VERSION ""

NS_ :

BS_:

BU_: PowertrainControlModule AtmosphericSensor SafetyRestraintSystem2 Aftertreatment_2_GasOutlet Aftertreatment_2_GasIntake DieselPartFilterControl Turbocharger SafetyRestraintSystem1 CabDisplay2 Aftertreatment_1_GasOutlet Aftertreatment_1_GasIntake OnBoardDataLogger OffBoardDiagnosticTool2 OffBoardDiagnosticTool1 FileServer ParkingBrakeController SeatController2 FanDriveController SteeringColumnUnit CommunicationUnitRadio CommunicationUnitSatellite CommunicationUnitCellular PropulsionBatteryCharger ChassisController2 ChassisController1 EngineValveControl AuxiliaryHeater2 AuxiliaryHeater1 ClutchUnit RampControl InformationSystem1 SuspensionSystemController2 OilSensor VehicleDynamicStability ExhaustEmissionController TransmissionDisplay2 TransmissionDisplay1 ClimateControl2 WaterPumpController RearAxleSteeringController LightingOperatorControl SeatController1 IgnitionController2 IgnitionController1 TirePressureController CabController2 CabController1 PneumaticSystemController SuspensionSystemController1 HydraulicPumpController EnduranceBrakingSystem RetarderExhaustEngine2 OnBoardDiagnosticUnit HeadwayController RetarderExhaustEngine1 CabDisplay1 ManagementComputer VirtualTerminal OffVehicleGateway PowerTakeOffFront HitchControl AuxiliaryValveControl BodyController TractorTrailerBridge1 StarterSystem ElectricalSystem VehicleSecurity VehicleNavigation AerodynamicControl ElectricalChargingSystem ClimateControl1 TripRecorder InstrumentCluster SuspensionDriveAxle2 SuspensionDriveAxle1 SuspensionSteerAxle SteeringController FuelSystem CruiseControl RetarderDriveline RetarderEngine BrakesDriveAxle2 BrakesDriveAxle1 BrakesSystemController BrakesSteerAxle AxleDrive2 AxleDrive1 AxleSteering PowerTakeOff ShiftConsoleSecondary ShiftConsolePrimary Transmission2 Transmission1 Engine2 Engine1

BO_ 2566718974 DLCD1: 8 Vector__XXX
 SG_ VhclAcclerationRateLimitLampData : 34|2@1+ (1,0) [0|3] "" Vector__XXX
 SG_ EngSpeedVeryHighLampData : 32|2@1+ (1,0) [0|3] "" Vector__XXX
 SG_ EngSpeedHighLampData : 30|2@1+ (1,0) [0|3] "" Vector__XXX
 SG_ EngCtrlMdule3ReadyForUseLampData : 28|2@1+ (1,0) [0|3] "" Vector__XXX
 SG_ EngCtrlMdule2ReadyForUseLampData : 26|2@1+ (1,0) [0|3] "" Vector__XXX
 SG_ EngCtrlMdule1ReadyForUseLampData : 24|2@1+ (1,0) [0|3] "" Vector__XXX
 SG_ EngWaitToStartLampData : 62|2@1+ (1,0) [0|3] "" Vector__XXX
 SG_ EngFuelFilterRestrictedLampData : 22|2@1+ (1,0) [0|3] "" Vector__XXX
 SG_ EngAirFilterRestrictionLampData : 20|2@1+ (1,0) [0|3] "" Vector__XXX
 SG_ EngIdleManagementActiveLampData : 18|2@1+ (1,0) [0|3] "" Vector__XXX
 SG_ EngCoolantLevelLowLampData : 16|2@1+ (1,0) [0|3] "" Vector__XXX
 SG_ EngCoolantTempHighLampData : 14|2@1+ (1,0) [0|3] "" Vector__XXX
 SG_ EngOilPressLowLampData : 12|2@1+ (1,0) [0|3] "" Vector__XXX
 SG_ CmprssnBrkEnblSwtchIndctrLmpData : 10|2@1+ (1,0) [0|3] "" Vector__XXX
 SG_ EngBrakeActiveLampData : 8|2@1+ (1,0) [0|3] "" Vector__XXX
 SG_ OBDMalfunctionIndicatorLampData : 6|2@1+ (1,0) [0|3] "" Vector__XXX
 SG_ EngRedStopLampData : 4|2@1+ (1,0) [0|3] "" Vector__XXX
 SG_ EngAmberWarningLampData : 2|2@1+ (1,0) [0|3] "" Vector__XXX
 SG_ EngProtectLampData : 0|2@1+ (1,0) [0|3] "" Vector__XXX

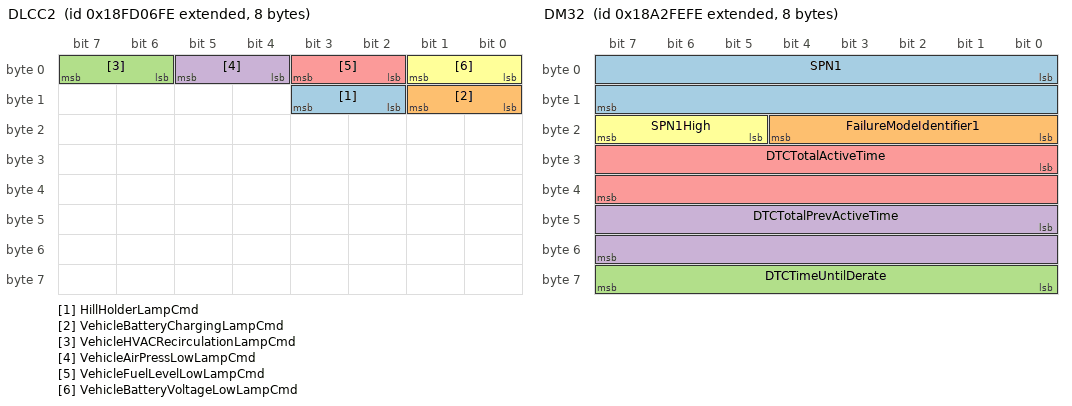
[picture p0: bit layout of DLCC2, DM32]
BO_ 2566719230 DLCC2: 8 Vector__XXX
 SG_ HillHolderLampCmd : 10|2@1+ (1,0) [0|3] "" Vector__XXX
 SG_ VehicleBatteryChargingLampCmd : 8|2@1+ (1,0) [0|3] "" Vector__XXX
 SG_ VehicleHVACRecirculationLampCmd : 6|2@1+ (1,0) [0|3] "" Vector__XXX
 SG_ VehicleAirPressLowLampCmd : 4|2@1+ (1,0) [0|3] "" Vector__XXX
 SG_ VehicleFuelLevelLowLampCmd : 2|2@1+ (1,0) [0|3] "" Vector__XXX
 SG_ VehicleBatteryVoltageLowLampCmd : 0|2@1+ (1,0) [0|3] "" Vector__XXX

BO_ 2560818942 DM32: 8 Vector__XXX
 SG_ SPN1 : 0|16@1+ (1,0) [0|65535] "" Vector__XXX
 SG_ FailureModeIdentifier1 : 16|5@1+ (1,0) [0|0] "" Vector__XXX
 SG_ DTCTimeUntilDerate : 56|8@1+ (0.25,0) [0|62.5] "hr" Vector__XXX
 SG_ DTCTotalPrevActiveTime : 40|16@1+ (0.2,0) [0|12851] "hr" Vector__XXX
 SG_ DTCTotalActiveTime : 24|16@1+ (0.2,0) [0|12851] "hr" Vector__XXX
 SG_ SPN1High : 21|3@1+ (1,0) [0|7] "" Vector__XXX

BO_ 2561212158 DISP1: 8 Vector__XXX
 SG_ TextDisplayIndex : 16|8@1+ (1,0) [0|200] "" Vector__XXX
 SG_ TextDisplayInstructions : 0|4@1+ (1,0) [0|15] "" Vector__XXX

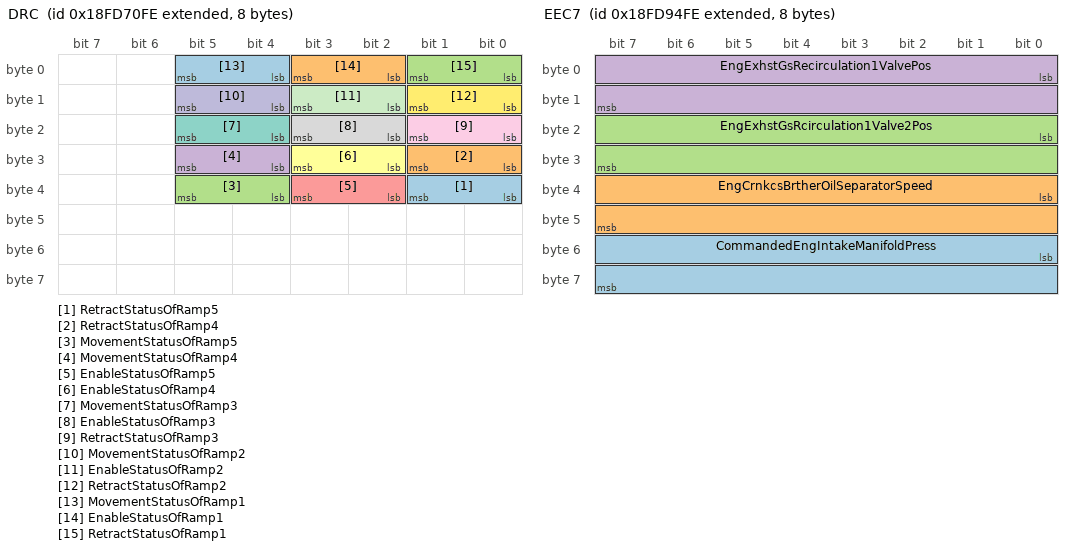
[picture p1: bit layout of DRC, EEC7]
BO_ 2566746366 DRC: 8 Vector__XXX
 SG_ RetractStatusOfRamp5 : 32|2@1+ (1,0) [0|3] "" Vector__XXX
 SG_ RetractStatusOfRamp4 : 24|2@1+ (1,0) [0|3] "" Vector__XXX
 SG_ MovementStatusOfRamp5 : 36|2@1+ (1,0) [0|3] "" Vector__XXX
 SG_ MovementStatusOfRamp4 : 28|2@1+ (1,0) [0|3] "" Vector__XXX
 SG_ EnableStatusOfRamp5 : 34|2@1+ (1,0) [0|3] "" Vector__XXX
 SG_ EnableStatusOfRamp4 : 26|2@1+ (1,0) [0|3] "" Vector__XXX
 SG_ MovementStatusOfRamp3 : 20|2@1+ (1,0) [0|3] "" Vector__XXX
 SG_ EnableStatusOfRamp3 : 18|2@1+ (1,0) [0|3] "" Vector__XXX
 SG_ RetractStatusOfRamp3 : 16|2@1+ (1,0) [0|3] "" Vector__XXX
 SG_ MovementStatusOfRamp2 : 12|2@1+ (1,0) [0|3] "" Vector__XXX
 SG_ EnableStatusOfRamp2 : 10|2@1+ (1,0) [0|3] "" Vector__XXX
 SG_ RetractStatusOfRamp2 : 8|2@1+ (1,0) [0|3] "" Vector__XXX
 SG_ MovementStatusOfRamp1 : 4|2@1+ (1,0) [0|3] "" Vector__XXX
 SG_ EnableStatusOfRamp1 : 2|2@1+ (1,0) [0|3] "" Vector__XXX
 SG_ RetractStatusOfRamp1 : 0|2@1+ (1,0) [0|3] "" Vector__XXX

BO_ 2566750206 EC2: 8 Vector__XXX
 SG_ EngConfigIdentification : 16|16@1+ (1,0) [0|64255] "" Vector__XXX
 SG_ NmbrOfCmbstionCyclesForAveraging : 8|8@1+ (1,0) [1|250] "" Vector__XXX
 SG_ MaxCrankAttemptsPerStartAttempt : 0|8@1+ (1,0) [0|250] "" Vector__XXX

BO_ 2566755582 EEC7: 8 Vector__XXX
 SG_ CommandedEngIntakeManifoldPress : 48|16@1+ (0.125,0) [0|8031.875] "kPa" Vector__XXX
 SG_ EngCrnkcsBrtherOilSeparatorSpeed : 32|16@1+ (1,0) [0|64255] "rpm" Vector__XXX
 SG_ EngExhstGsRcirculation1Valve2Pos : 16|16@1+ (0.0025,0) [0|160.6375] "%" Vector__XXX
 SG_ EngExhstGsRecirculation1ValvePos : 0|16@1+ (0.0025,0) [0|160.6375] "%" Vector__XXX

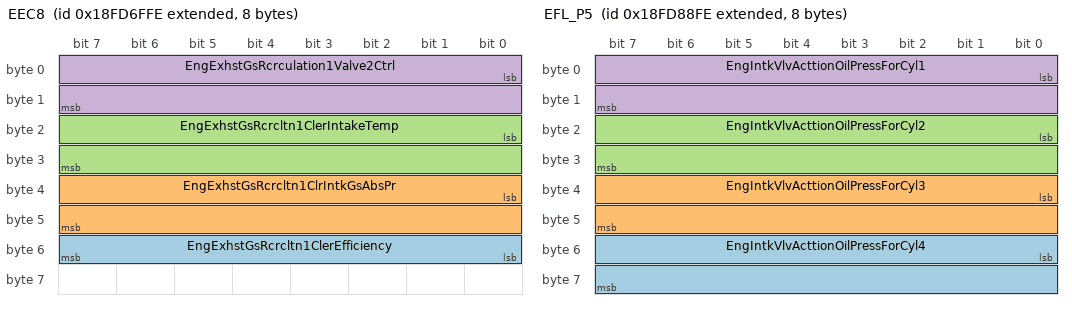
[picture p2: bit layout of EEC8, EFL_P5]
BO_ 2566746110 EEC8: 8 Vector__XXX
 SG_ EngExhstGsRcrcltn1ClerEfficiency : 48|8@1+ (0.4,0) [0|100] "%" Vector__XXX
 SG_ EngExhstGsRcrcltn1ClrIntkGsAbsPr : 32|16@1+ (0.5,0) [0|32127.5] "kPa" Vector__XXX
 SG_ EngExhstGsRcrcltn1ClerIntakeTemp : 16|16@1+ (0.03125,-273) [-273|1734.96875] "°C" Vector__XXX
 SG_ EngExhstGsRcrculation1Valve2Ctrl : 0|16@1+ (0.0025,0) [0|160.6375] "%" Vector__XXX

BO_ 2566752510 EFL_P5: 8 Vector__XXX
 SG_ EngIntkVlvActtionOilPressForCyl4 : 48|16@1+ (0.1,0) [0|6425.5] "kPa" Vector__XXX
 SG_ EngIntkVlvActtionOilPressForCyl3 : 32|16@1+ (0.1,0) [0|6425.5] "kPa" Vector__XXX
 SG_ EngIntkVlvActtionOilPressForCyl2 : 16|16@1+ (0.1,0) [0|6425.5] "kPa" Vector__XXX
 SG_ EngIntkVlvActtionOilPressForCyl1 : 0|16@1+ (0.1,0) [0|6425.5] "kPa" Vector__XXX

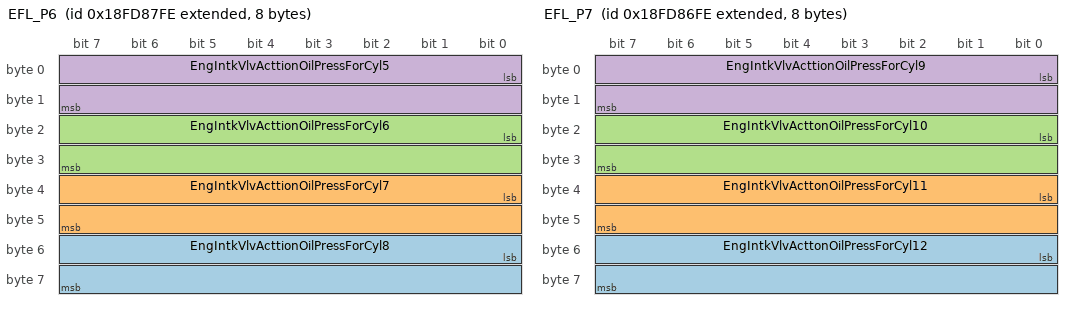
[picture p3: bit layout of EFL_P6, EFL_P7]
BO_ 2566752254 EFL_P6: 8 Vector__XXX
 SG_ EngIntkVlvActtionOilPressForCyl8 : 48|16@1+ (0.1,0) [0|6425.5] "kPa" Vector__XXX
 SG_ EngIntkVlvActtionOilPressForCyl7 : 32|16@1+ (0.1,0) [0|6425.5] "kPa" Vector__XXX
 SG_ EngIntkVlvActtionOilPressForCyl6 : 16|16@1+ (0.1,0) [0|6425.5] "kPa" Vector__XXX
 SG_ EngIntkVlvActtionOilPressForCyl5 : 0|16@1+ (0.1,0) [0|6425.5] "kPa" Vector__XXX

BO_ 2566751998 EFL_P7: 8 Vector__XXX
 SG_ EngIntkVlvActtonOilPressForCyl12 : 48|16@1+ (0.1,0) [0|6425.5] "kPa" Vector__XXX
 SG_ EngIntkVlvActtonOilPressForCyl11 : 32|16@1+ (0.1,0) [0|6425.5] "kPa" Vector__XXX
 SG_ EngIntkVlvActtonOilPressForCyl10 : 16|16@1+ (0.1,0) [0|6425.5] "kPa" Vector__XXX
 SG_ EngIntkVlvActtionOilPressForCyl9 : 0|16@1+ (0.1,0) [0|6425.5] "kPa" Vector__XXX

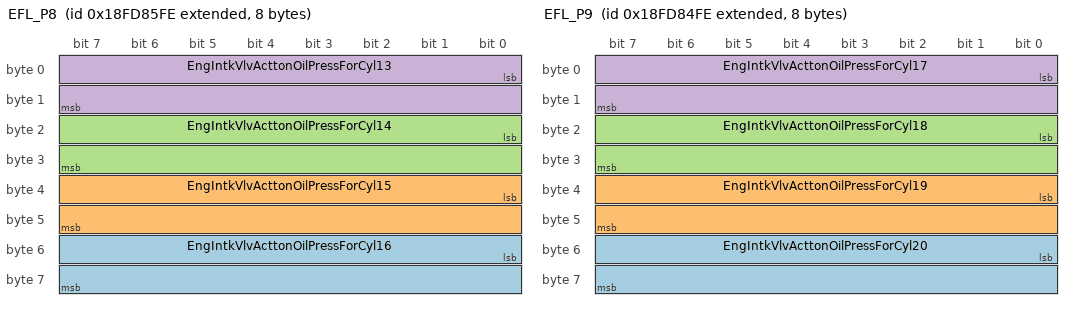
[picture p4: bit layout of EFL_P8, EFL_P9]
BO_ 2566751742 EFL_P8: 8 Vector__XXX
 SG_ EngIntkVlvActtonOilPressForCyl16 : 48|16@1+ (0.1,0) [0|6425.5] "kPa" Vector__XXX
 SG_ EngIntkVlvActtonOilPressForCyl15 : 32|16@1+ (0.1,0) [0|6425.5] "kPa" Vector__XXX
 SG_ EngIntkVlvActtonOilPressForCyl14 : 16|16@1+ (0.1,0) [0|6425.5] "kPa" Vector__XXX
 SG_ EngIntkVlvActtonOilPressForCyl13 : 0|16@1+ (0.1,0) [0|6425.5] "kPa" Vector__XXX

BO_ 2566751486 EFL_P9: 8 Vector__XXX
 SG_ EngIntkVlvActtonOilPressForCyl20 : 48|16@1+ (0.1,0) [0|6425.5] "kPa" Vector__XXX
 SG_ EngIntkVlvActtonOilPressForCyl19 : 32|16@1+ (0.1,0) [0|6425.5] "kPa" Vector__XXX
 SG_ EngIntkVlvActtonOilPressForCyl18 : 16|16@1+ (0.1,0) [0|6425.5] "kPa" Vector__XXX
 SG_ EngIntkVlvActtonOilPressForCyl17 : 0|16@1+ (0.1,0) [0|6425.5] "kPa" Vector__XXX

BO_ 2499641854 EGRBV: 8 Vector__XXX
 SG_ EGR1CoolerBypassActuatorPostion : 0|8@1+ (0.4,0) [0|100] "%" Vector__XXX

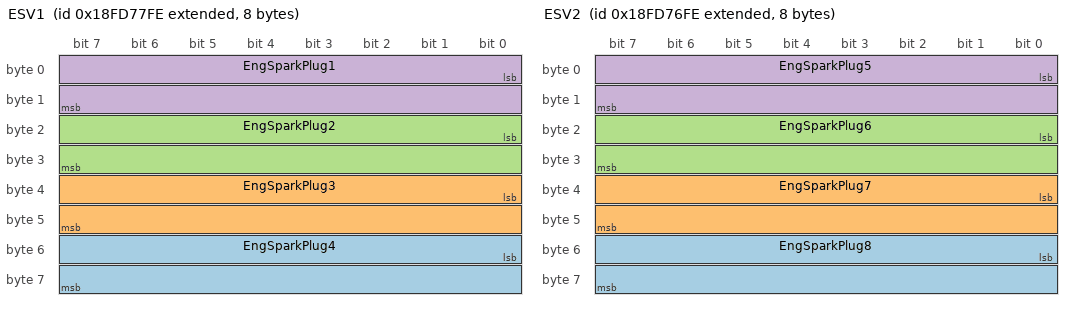
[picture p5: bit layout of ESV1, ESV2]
BO_ 2566748158 ESV1: 8 Vector__XXX
 SG_ EngSparkPlug4 : 48|16@1+ (1,0) [0|64255] "V" Vector__XXX
 SG_ EngSparkPlug3 : 32|16@1+ (1,0) [0|64255] "V" Vector__XXX
 SG_ EngSparkPlug2 : 16|16@1+ (1,0) [0|64255] "V" Vector__XXX
 SG_ EngSparkPlug1 : 0|16@1+ (1,0) [0|64255] "V" Vector__XXX

BO_ 2566747902 ESV2: 8 Vector__XXX
 SG_ EngSparkPlug8 : 48|16@1+ (1,0) [0|64255] "V" Vector__XXX
 SG_ EngSparkPlug7 : 32|16@1+ (1,0) [0|64255] "V" Vector__XXX
 SG_ EngSparkPlug6 : 16|16@1+ (1,0) [0|64255] "V" Vector__XXX
 SG_ EngSparkPlug5 : 0|16@1+ (1,0) [0|64255] "V" Vector__XXX

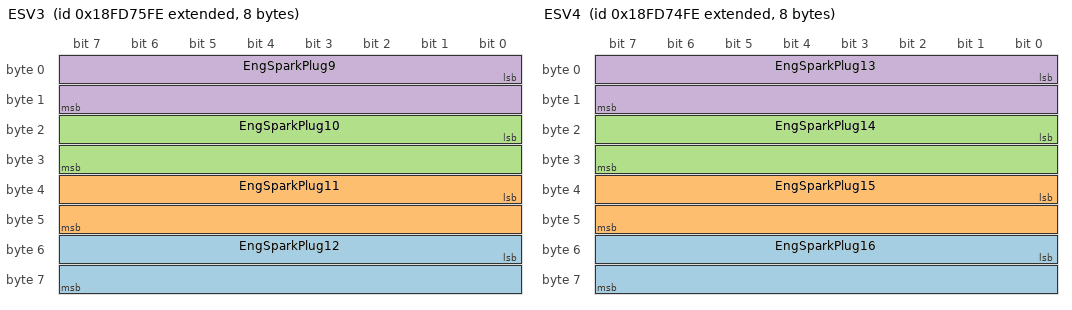
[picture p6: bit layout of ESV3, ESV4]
BO_ 2566747646 ESV3: 8 Vector__XXX
 SG_ EngSparkPlug12 : 48|16@1+ (1,0) [0|64255] "V" Vector__XXX
 SG_ EngSparkPlug11 : 32|16@1+ (1,0) [0|64255] "V" Vector__XXX
 SG_ EngSparkPlug10 : 16|16@1+ (1,0) [0|64255] "V" Vector__XXX
 SG_ EngSparkPlug9 : 0|16@1+ (1,0) [0|64255] "V" Vector__XXX

BO_ 2566747390 ESV4: 8 Vector__XXX
 SG_ EngSparkPlug16 : 48|16@1+ (1,0) [0|64255] "V" Vector__XXX
 SG_ EngSparkPlug15 : 32|16@1+ (1,0) [0|64255] "V" Vector__XXX
 SG_ EngSparkPlug14 : 16|16@1+ (1,0) [0|64255] "V" Vector__XXX
 SG_ EngSparkPlug13 : 0|16@1+ (1,0) [0|64255] "V" Vector__XXX

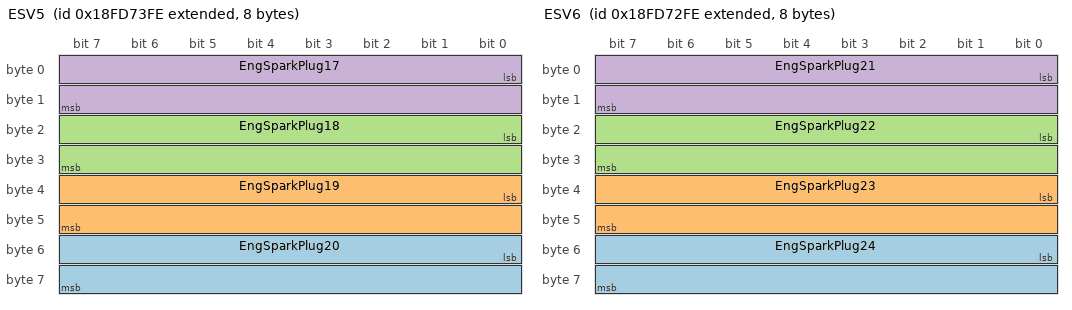
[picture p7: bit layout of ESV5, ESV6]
BO_ 2566747134 ESV5: 8 Vector__XXX
 SG_ EngSparkPlug20 : 48|16@1+ (1,0) [0|64255] "V" Vector__XXX
 SG_ EngSparkPlug19 : 32|16@1+ (1,0) [0|64255] "V" Vector__XXX
 SG_ EngSparkPlug18 : 16|16@1+ (1,0) [0|64255] "V" Vector__XXX
 SG_ EngSparkPlug17 : 0|16@1+ (1,0) [0|64255] "V" Vector__XXX

BO_ 2566746878 ESV6: 8 Vector__XXX
 SG_ EngSparkPlug24 : 48|16@1+ (1,0) [0|64255] "V" Vector__XXX
 SG_ EngSparkPlug23 : 32|16@1+ (1,0) [0|64255] "V" Vector__XXX
 SG_ EngSparkPlug22 : 16|16@1+ (1,0) [0|64255] "V" Vector__XXX
 SG_ EngSparkPlug21 : 0|16@1+ (1,0) [0|64255] "V" Vector__XXX

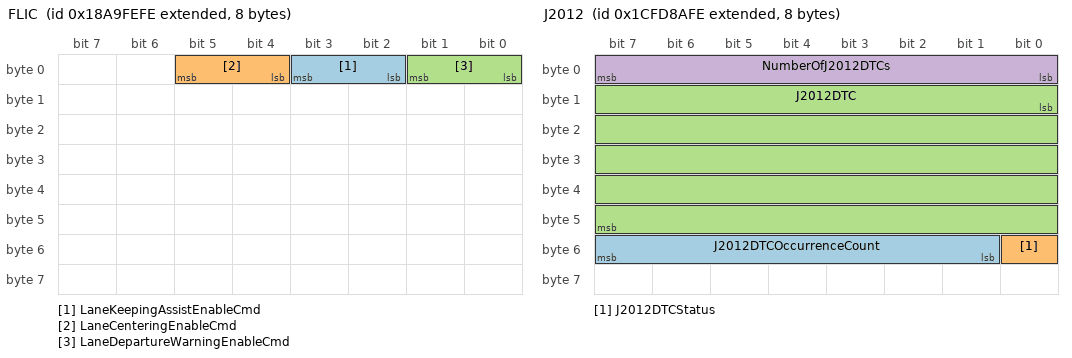
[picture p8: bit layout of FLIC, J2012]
BO_ 2561277694 FLIC: 8 Vector__XXX
 SG_ LaneKeepingAssistEnableCmd : 2|2@1+ (1,0) [0|3] "" Vector__XXX
 SG_ LaneCenteringEnableCmd : 4|2@1+ (1,0) [0|3] "" Vector__XXX
 SG_ LaneDepartureWarningEnableCmd : 0|2@1+ (1,0) [0|3] "" Vector__XXX

BO_ 2633861886 J2012: 8 Vector__XXX
 SG_ J2012DTCOccurrenceCount : 49|7@1+ (1,0) [0|126] "" Vector__XXX
 SG_ J2012DTCStatus : 48|1@1+ (1,0) [0|1] "" Vector__XXX
 SG_ J2012DTC : 8|40@1+ (1,0) [0|255] "" Vector__XXX
 SG_ NumberOfJ2012DTCs : 0|8@1+ (1,0) [0|250] "" Vector__XXX

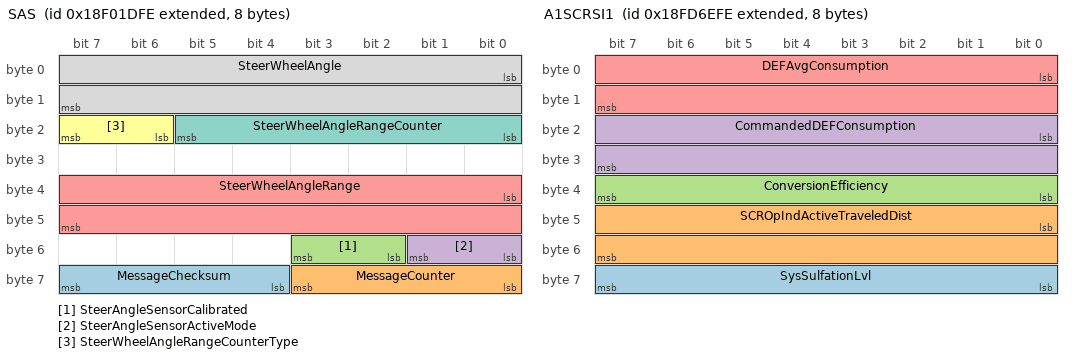
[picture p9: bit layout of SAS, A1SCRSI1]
BO_ 2565873150 SAS: 8 Vector__XXX
 SG_ MessageChecksum : 60|4@1+ (1,0) [0|15] "" Vector__XXX
 SG_ MessageCounter : 56|4@1+ (1,0) [0|15] "" Vector__XXX
 SG_ SteerAngleSensorCalibrated : 50|2@1+ (1,0) [0|3] "" Vector__XXX
 SG_ SteerAngleSensorActiveMode : 48|2@1+ (1,0) [0|3] "" Vector__XXX
 SG_ SteerWheelAngleRange : 32|16@1+ (0.0009765625,-31.374) [0|31.374] "rad" Vector__XXX
 SG_ SteerWheelAngleRangeCounterType : 22|2@1+ (1,0) [0|3] "" Vector__XXX
 SG_ SteerWheelAngleRangeCounter : 16|6@1+ (1,-32) [-32|29] "ranges" Vector__XXX
 SG_ SteerWheelAngle : 0|16@1+ (0.0009765625,-31.374) [-31.374|31.374] "rad" Vector__XXX

BO_ 2566745854 A1SCRSI1: 8 Vector__XXX
 SG_ SysSulfationLvl : 56|8@1+ (1,0) [0|250] "%" Vector__XXX
 SG_ SCROpIndActiveTraveledDist : 40|16@1+ (1,0) [0|64255] "km" Vector__XXX
 SG_ ConversionEfficiency : 32|8@1+ (0.4,0) [0|100] "%" Vector__XXX
 SG_ CommandedDEFConsumption : 16|16@1+ (0.05,0) [0|3212.75] "L/h" Vector__XXX
 SG_ DEFAvgConsumption : 0|16@1+ (0.05,0) [0|3212.75] "L/h" Vector__XXX

BO_ 2566751230 TCI: 8 Vector__XXX
 SG_ TransferCaseStatus : 0|3@1+ (1,0) [0|7] "" Vector__XXX

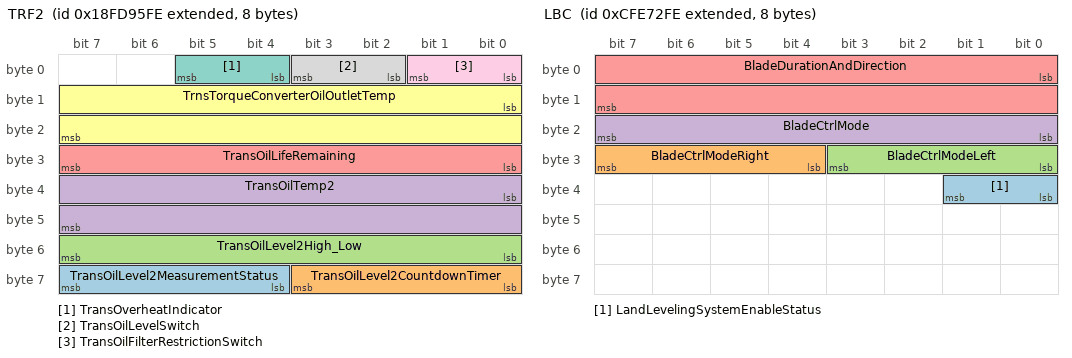
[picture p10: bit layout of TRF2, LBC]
BO_ 2566755838 TRF2: 8 Vector__XXX
 SG_ TransOilLevel2MeasurementStatus : 60|4@1+ (1,0) [0|15] "" Vector__XXX
 SG_ TransOilLevel2CountdownTimer : 56|4@1+ (1,0) [0|13] "" Vector__XXX
 SG_ TransOilLevel2High_Low : 48|8@1+ (0.5,-62.5) [-62.5|62.5] "L" Vector__XXX
 SG_ TransOilTemp2 : 32|16@1+ (0.03125,-273) [-273|1734.96875] "°C" Vector__XXX
 SG_ TransOilLifeRemaining : 24|8@1+ (0.4,0) [0|100] "%" Vector__XXX
 SG_ TrnsTorqueConverterOilOutletTemp : 8|16@1+ (0.03125,-273) [-273|1734.96875] "°C" Vector__XXX
 SG_ TransOverheatIndicator : 4|2@1+ (1,0) [0|3] "" Vector__XXX
 SG_ TransOilLevelSwitch : 2|2@1+ (1,0) [0|3] "" Vector__XXX
 SG_ TransOilFilterRestrictionSwitch : 0|2@1+ (1,0) [0|3] "" Vector__XXX

BO_ 2566752766 VDS2: 8 Vector__XXX
 SG_ VehicleRoll : 0|16@1+ (0.0078125,-200) [-90|90] "deg" Vector__XXX

BO_ 2633938942 LF: 10 Vector__XXX
 SG_ TotalEngCruiseTime : 48|32@1+ (0.05,0) [0|210554060.75] "h" Vector__XXX
 SG_ TotalDriveAverageLoadFactor : 40|8@1+ (0.4,0) [0|100] "%" Vector__XXX
 SG_ TripDriveAverageLoadFactor : 32|8@1+ (0.4,0) [0|100] "%" Vector__XXX
 SG_ TripAverageEngSpeed : 16|16@1+ (0.125,0) [0|8031.875] "rpm" Vector__XXX
 SG_ TripMaxEngSpeed : 0|16@1+ (0.125,0) [0|8031.875] "rpm" Vector__XXX

BO_ 2566799614 LD: 8 Vector__XXX
 SG_ ImplementRearWorkLight : 62|2@1+ (1,0) [0|3] "" Vector__XXX
 SG_ ImplLeftFacingWorkLight : 60|2@1+ (1,0) [0|3] "" Vector__XXX
 SG_ ImplRightForwardWorkLight : 58|2@1+ (1,0) [0|3] "" Vector__XXX
 SG_ ImplLeftForwardWorkLight : 54|2@1+ (1,0) [0|3] "" Vector__XXX
 SG_ ImplRightFacingWorkLight : 52|2@1+ (1,0) [0|3] "" Vector__XXX
 SG_ ImplementOEMOption1Light : 50|2@1+ (1,0) [0|3] "" Vector__XXX
 SG_ ImplementOEMOption2Light : 48|2@1+ (1,0) [0|3] "" Vector__XXX
 SG_ TrctorFrontHighMdWkLights : 46|2@1+ (1,0) [0|3] "" Vector__XXX
 SG_ TractorFrontLowMdWkLights : 44|2@1+ (1,0) [0|3] "" Vector__XXX
 SG_ TractorSideHighMdWkLights : 42|2@1+ (1,0) [0|3] "" Vector__XXX
 SG_ TractorSideLowMdWkLights : 40|2@1+ (1,0) [0|3] "" Vector__XXX
 SG_ TractorRearHighMdWkLights : 38|2@1+ (1,0) [0|3] "" Vector__XXX
 SG_ TractorRearLowMdWkLights : 36|2@1+ (1,0) [0|3] "" Vector__XXX
 SG_ TrctorUndersideMdWkLights : 34|2@1+ (1,0) [0|3] "" Vector__XXX
 SG_ RearFogLights : 32|2@1+ (1,0) [0|3] "" Vector__XXX
 SG_ TractorMarkerLight : 30|2@1+ (1,0) [0|3] "" Vector__XXX
 SG_ ImplementMarkerLight : 28|2@1+ (1,0) [0|3] "" Vector__XXX
 SG_ TractorClearanceLight : 26|2@1+ (1,0) [0|3] "" Vector__XXX
 SG_ ImplementClearanceLight : 24|2@1+ (1,0) [0|3] "" Vector__XXX
 SG_ LeftStopLight : 22|2@1+ (1,0) [0|3] "" Vector__XXX
 SG_ RightStopLight : 20|2@1+ (1,0) [0|3] "" Vector__XXX
 SG_ CenterStopLight : 18|2@1+ (1,0) [0|3] "" Vector__XXX
 SG_ BackUpLightAndAlarmHorn : 16|2@1+ (1,0) [0|3] "" Vector__XXX
 SG_ LeftTurnSignalLights : 14|2@1+ (1,0) [0|3] "" Vector__XXX
 SG_ RightTurnSignalLights : 12|2@1+ (1,0) [0|3] "" Vector__XXX
 SG_ RotatingBeaconLight : 10|2@1+ (1,0) [0|3] "" Vector__XXX
 SG_ TractorFrontFogLights : 8|2@1+ (1,0) [0|3] "" Vector__XXX
 SG_ HighBeamHeadLight : 6|2@1+ (1,0) [0|3] "" Vector__XXX
 SG_ LowBeamHeadLight : 4|2@1+ (1,0) [0|3] "" Vector__XXX
 SG_ AltBeamHeadLight : 2|2@1+ (1,0) [0|3] "" Vector__XXX
 SG_ RunningLight : 0|2@1+ (1,0) [0|3] "" Vector__XXX

BO_ 2365473278 LCMD: 8 Vector__XXX
 SG_ ImplementRearWorkLightCmd : 62|2@1+ (1,0) [0|3] "" Vector__XXX
 SG_ ImplLeftFacingWorkLightCmd : 60|2@1+ (1,0) [0|3] "" Vector__XXX
 SG_ ImplRightFwdWorkLightCmd : 58|2@1+ (1,0) [0|3] "" Vector__XXX
 SG_ LightingDataRqCmd : 56|2@1+ (1,0) [0|3] "" Vector__XXX
 SG_ ImplLeftForwardWorkLightCmd : 54|2@1+ (1,0) [0|3] "" Vector__XXX
 SG_ ImplRightFacingWorkLightCmd : 52|2@1+ (1,0) [0|3] "" Vector__XXX
 SG_ ImplOEMOption1LightCmd : 50|2@1+ (1,0) [0|3] "" Vector__XXX
 SG_ ImplOEMOption2LightCmd : 48|2@1+ (1,0) [0|3] "" Vector__XXX
 SG_ TrctrFrntHghMdWkLightsCmd : 46|2@1+ (1,0) [0|3] "" Vector__XXX
 SG_ TrctrFrntLowMdWkLightsCmd : 44|2@1+ (1,0) [0|3] "" Vector__XXX
 SG_ TrctrSdeHighMdWkLightsCmd : 42|2@1+ (1,0) [0|3] "" Vector__XXX
 SG_ TrctrSideLowMdWkLightsCmd : 40|2@1+ (1,0) [0|3] "" Vector__XXX
 SG_ TrctrRarHighMdWkLightsCmd : 38|2@1+ (1,0) [0|3] "" Vector__XXX
 SG_ TrctrRearLowMdWkLightsCmd : 36|2@1+ (1,0) [0|3] "" Vector__XXX
 SG_ TrctrUndrsdeMdWkLightsCmd : 34|2@1+ (1,0) [0|3] "" Vector__XXX
 SG_ RearFogLightsCmd : 32|2@1+ (1,0) [0|3] "" Vector__XXX
 SG_ TractorMarkerLightCmd : 30|2@1+ (1,0) [0|3] "" Vector__XXX
 SG_ ImplementMarkerLightCmd : 28|2@1+ (1,0) [0|3] "" Vector__XXX
 SG_ TractorClearanceLightCmd : 26|2@1+ (1,0) [0|3] "" Vector__XXX
 SG_ ImplementClearanceLightCmd : 24|2@1+ (1,0) [0|3] "" Vector__XXX
 SG_ LeftStopLightCmd : 22|2@1+ (1,0) [0|3] "" Vector__XXX
 SG_ RightStopLightCmd : 20|2@1+ (1,0) [0|3] "" Vector__XXX
 SG_ CenterStopLightCmd : 18|2@1+ (1,0) [0|3] "" Vector__XXX
 SG_ BackUpLightAndAlarmHornCmd : 16|2@1+ (1,0) [0|3] "" Vector__XXX
 SG_ LeftTurnSignalLightsCmd : 14|2@1+ (1,0) [0|3] "" Vector__XXX
 SG_ RightTurnSignalLightsCmd : 12|2@1+ (1,0) [0|3] "" Vector__XXX
 SG_ RotatingBeaconLightCmd : 10|2@1+ (1,0) [0|3] "" Vector__XXX
 SG_ TractorFrontFogLightsCmd : 8|2@1+ (1,0) [0|3] "" Vector__XXX
 SG_ HighBeamHeadLightCmd : 6|2@1+ (1,0) [0|3] "" Vector__XXX
 SG_ LowBeamHeadLightCmd : 4|2@1+ (1,0) [0|3] "" Vector__XXX
 SG_ AltBeamHeadLightCmd : 2|2@1+ (1,0) [0|3] "" Vector__XXX
 SG_ RunningLightCmd : 0|2@1+ (1,0) [0|3] "" Vector__XXX

BO_ 2365485822 LBC: 8 Vector__XXX
 SG_ LandLevelingSystemEnableStatus : 32|2@1+ (1,0) [0|3] "" Vector__XXX
 SG_ BladeCtrlModeRight : 28|4@1+ (1,0) [0|15] "" Vector__XXX
 SG_ BladeCtrlModeLeft : 24|4@1+ (1,0) [0|15] "" Vector__XXX
 SG_ BladeCtrlMode : 16|8@1+ (1,0) [0|255] "" Vector__XXX
 SG_ BladeDurationAndDirection : 0|16@1+ (0.1,-3276.8) [-3276.8|3148.7] "sec" Vector__XXX

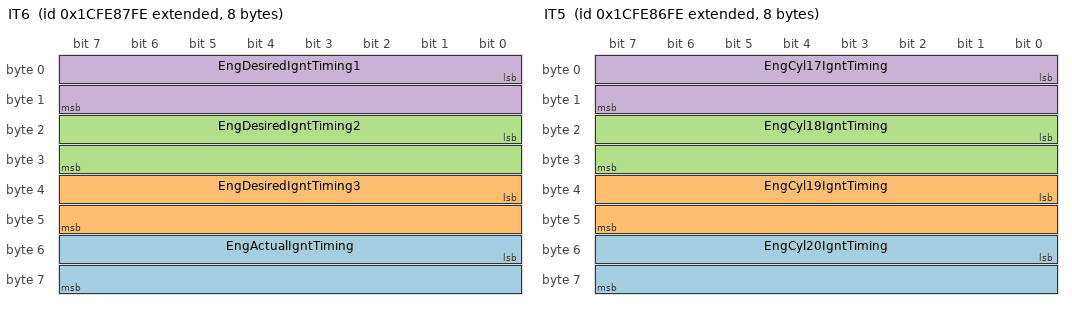
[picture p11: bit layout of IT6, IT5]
BO_ 2633926654 IT6: 8 Vector__XXX
 SG_ EngActualIgntTiming : 48|16@1+ (0.0078125,-200) [-200|301.99] "deg" Vector__XXX
 SG_ EngDesiredIgntTiming3 : 32|16@1+ (0.0078125,-200) [-200|301.99] "deg" Vector__XXX
 SG_ EngDesiredIgntTiming2 : 16|16@1+ (0.0078125,-200) [-200|301.99] "deg" Vector__XXX
 SG_ EngDesiredIgntTiming1 : 0|16@1+ (0.0078125,-200) [-200|301.99] "deg" Vector__XXX

BO_ 2633926398 IT5: 8 Vector__XXX
 SG_ EngCyl20IgntTiming : 48|16@1+ (0.0078125,-200) [-200|301.99] "deg" Vector__XXX
 SG_ EngCyl19IgntTiming : 32|16@1+ (0.0078125,-200) [-200|301.99] "deg" Vector__XXX
 SG_ EngCyl18IgntTiming : 16|16@1+ (0.0078125,-200) [-200|301.99] "deg" Vector__XXX
 SG_ EngCyl17IgntTiming : 0|16@1+ (0.0078125,-200) [-200|301.99] "deg" Vector__XXX

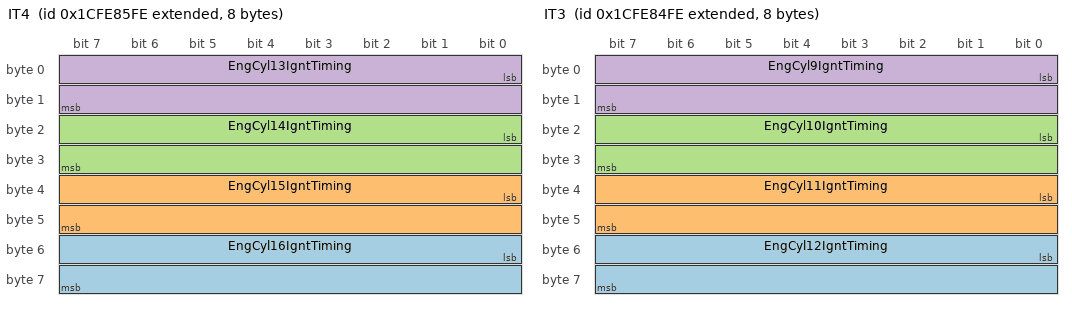
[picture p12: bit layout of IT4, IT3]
BO_ 2633926142 IT4: 8 Vector__XXX
 SG_ EngCyl16IgntTiming : 48|16@1+ (0.0078125,-200) [-200|301.99] "deg" Vector__XXX
 SG_ EngCyl15IgntTiming : 32|16@1+ (0.0078125,-200) [-200|301.99] "deg" Vector__XXX
 SG_ EngCyl14IgntTiming : 16|16@1+ (0.0078125,-200) [-200|301.99] "deg" Vector__XXX
 SG_ EngCyl13IgntTiming : 0|16@1+ (0.0078125,-200) [-200|301.99] "deg" Vector__XXX

BO_ 2633925886 IT3: 8 Vector__XXX
 SG_ EngCyl12IgntTiming : 48|16@1+ (0.0078125,-200) [-200|301.99] "deg" Vector__XXX
 SG_ EngCyl11IgntTiming : 32|16@1+ (0.0078125,-200) [-200|301.99] "deg" Vector__XXX
 SG_ EngCyl10IgntTiming : 16|16@1+ (0.0078125,-200) [-200|301.99] "deg" Vector__XXX
 SG_ EngCyl9IgntTiming : 0|16@1+ (0.0078125,-200) [-200|301.99] "deg" Vector__XXX

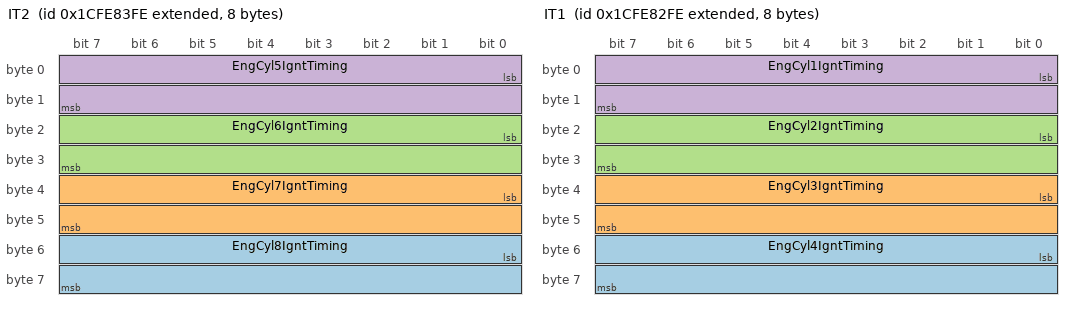
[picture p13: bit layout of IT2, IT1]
BO_ 2633925630 IT2: 8 Vector__XXX
 SG_ EngCyl8IgntTiming : 48|16@1+ (0.0078125,-200) [-200|301.99] "deg" Vector__XXX
 SG_ EngCyl7IgntTiming : 32|16@1+ (0.0078125,-200) [-200|301.99] "deg" Vector__XXX
 SG_ EngCyl6IgntTiming : 16|16@1+ (0.0078125,-200) [-200|301.99] "deg" Vector__XXX
 SG_ EngCyl5IgntTiming : 0|16@1+ (0.0078125,-200) [-200|301.99] "deg" Vector__XXX

BO_ 2633925374 IT1: 8 Vector__XXX
 SG_ EngCyl4IgntTiming : 48|16@1+ (0.0078125,-200) [-200|301.99] "deg" Vector__XXX
 SG_ EngCyl3IgntTiming : 32|16@1+ (0.0078125,-200) [-200|301.99] "deg" Vector__XXX
 SG_ EngCyl2IgntTiming : 16|16@1+ (0.0078125,-200) [-200|301.99] "deg" Vector__XXX
 SG_ EngCyl1IgntTiming : 0|16@1+ (0.0078125,-200) [-200|301.99] "deg" Vector__XXX

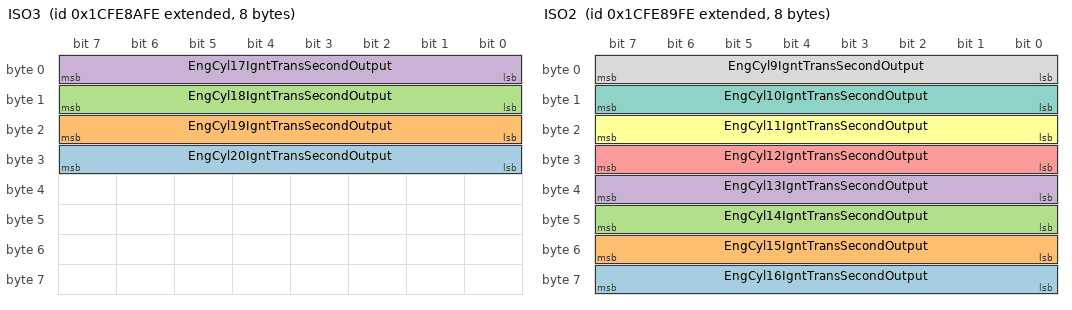
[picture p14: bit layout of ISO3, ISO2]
BO_ 2633927422 ISO3: 8 Vector__XXX
 SG_ EngCyl20IgntTransSecondOutput : 24|8@1+ (1,-125) [-125|125] "%" Vector__XXX
 SG_ EngCyl19IgntTransSecondOutput : 16|8@1+ (1,-125) [-125|125] "%" Vector__XXX
 SG_ EngCyl18IgntTransSecondOutput : 8|8@1+ (1,-125) [-125|125] "%" Vector__XXX
 SG_ EngCyl17IgntTransSecondOutput : 0|8@1+ (1,-125) [-125|125] "%" Vector__XXX

BO_ 2633927166 ISO2: 8 Vector__XXX
 SG_ EngCyl16IgntTransSecondOutput : 56|8@1+ (1,-125) [-125|125] "%" Vector__XXX
 SG_ EngCyl15IgntTransSecondOutput : 48|8@1+ (1,-125) [-125|125] "%" Vector__XXX
 SG_ EngCyl14IgntTransSecondOutput : 40|8@1+ (1,-125) [-125|125] "%" Vector__XXX
 SG_ EngCyl13IgntTransSecondOutput : 32|8@1+ (1,-125) [-125|125] "%" Vector__XXX
 SG_ EngCyl12IgntTransSecondOutput : 24|8@1+ (1,-125) [-125|125] "%" Vector__XXX
 SG_ EngCyl11IgntTransSecondOutput : 16|8@1+ (1,-125) [-125|125] "%" Vector__XXX
 SG_ EngCyl10IgntTransSecondOutput : 8|8@1+ (1,-125) [-125|125] "%" Vector__XXX
 SG_ EngCyl9IgntTransSecondOutput : 0|8@1+ (1,-125) [-125|125] "%" Vector__XXX

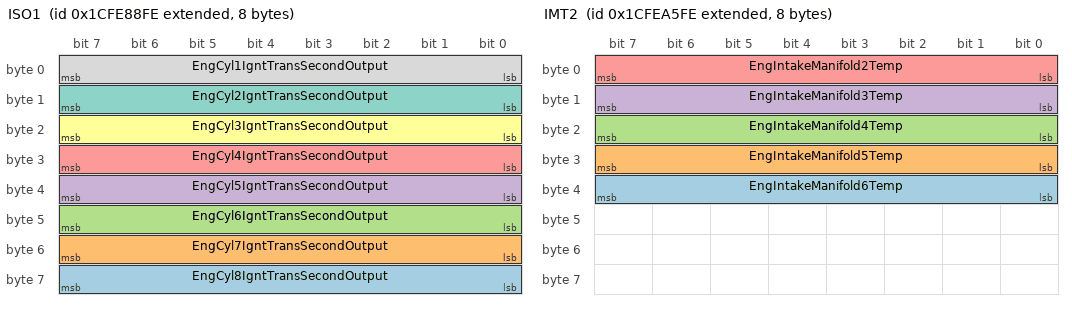
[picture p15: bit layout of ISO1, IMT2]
BO_ 2633926910 ISO1: 8 Vector__XXX
 SG_ EngCyl8IgntTransSecondOutput : 56|8@1+ (1,-125) [-125|125] "%" Vector__XXX
 SG_ EngCyl7IgntTransSecondOutput : 48|8@1+ (1,-125) [-125|125] "%" Vector__XXX
 SG_ EngCyl6IgntTransSecondOutput : 40|8@1+ (1,-125) [-125|125] "%" Vector__XXX
 SG_ EngCyl5IgntTransSecondOutput : 32|8@1+ (1,-125) [-125|125] "%" Vector__XXX
 SG_ EngCyl4IgntTransSecondOutput : 24|8@1+ (1,-125) [-125|125] "%" Vector__XXX
 SG_ EngCyl3IgntTransSecondOutput : 16|8@1+ (1,-125) [-125|125] "%" Vector__XXX
 SG_ EngCyl2IgntTransSecondOutput : 8|8@1+ (1,-125) [-125|125] "%" Vector__XXX
 SG_ EngCyl1IgntTransSecondOutput : 0|8@1+ (1,-125) [-125|125] "%" Vector__XXX

BO_ 2566768894 ISCS: 8 Vector__XXX
 SG_ EngOprtrPrmryIntrmdtSpdSlctState : 0|4@1+ (1,0) [0|15] "" Vector__XXX

BO_ 2566769406 ISC: 8 Vector__XXX
 SG_ EngOprtrPrmryIntrmdteSpeedSelect : 0|4@1+ (1,0) [0|15] "" Vector__XXX

BO_ 2566839550 IO: 8 Vector__XXX
 SG_ EngTotalIdleHours : 32|32@1+ (0.05,0) [0|210554060.75] "h" Vector__XXX
 SG_ EngTotalIdleFuelUsed : 0|32@1+ (0.5,0) [0|2105540607.5] "L" Vector__XXX

BO_ 2633934334 IMT2: 8 Vector__XXX
 SG_ EngIntakeManifold6Temp : 32|8@1+ (1,-40) [-40|210] "°C" Vector__XXX
 SG_ EngIntakeManifold5Temp : 24|8@1+ (1,-40) [-40|210] "°C" Vector__XXX
 SG_ EngIntakeManifold4Temp : 16|8@1+ (1,-40) [-40|210] "°C" Vector__XXX
 SG_ EngIntakeManifold3Temp : 8|8@1+ (1,-40) [-40|210] "°C" Vector__XXX
 SG_ EngIntakeManifold2Temp : 0|8@1+ (1,-40) [-40|210] "°C" Vector__XXX

BO_ 2566825726 IMT1: 8 Vector__XXX
 SG_ EngTurbo4BoostPress : 48|16@1+ (0.125,0) [0|8031.875] "kPa" Vector__XXX
 SG_ EngTurbo3BoostPress : 32|16@1+ (0.125,0) [0|8031.875] "kPa" Vector__XXX
 SG_ EngTurbo2BoostPress : 16|16@1+ (0.125,0) [0|8031.875] "kPa" Vector__XXX
 SG_ EngTurbo1BoostPress : 0|16@1+ (0.125,0) [0|8031.875] "kPa" Vector__XXX

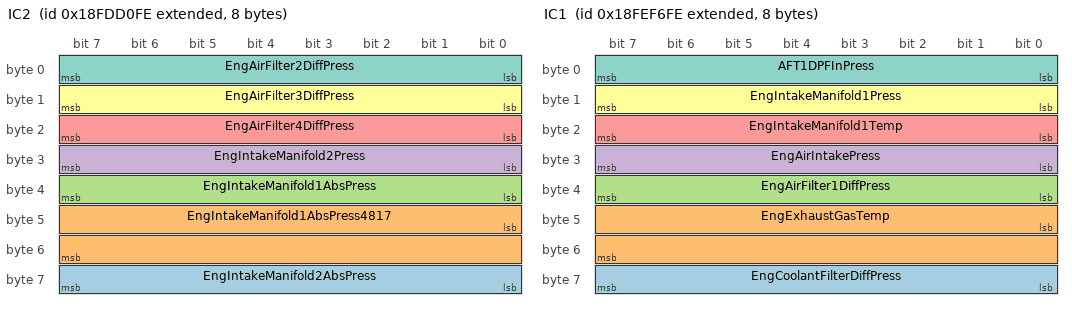
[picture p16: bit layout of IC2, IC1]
BO_ 2566770942 IC2: 8 Vector__XXX
 SG_ EngIntakeManifold2AbsPress : 56|8@1+ (2,0) [0|500] "kPa" Vector__XXX
 SG_ EngIntakeManifold1AbsPress4817 : 40|16@1+ (0.1,0) [0|6425.5] "kPa" Vector__XXX
 SG_ EngIntakeManifold1AbsPress : 32|8@1+ (2,0) [0|500] "kPa" Vector__XXX
 SG_ EngIntakeManifold2Press : 24|8@1+ (2,0) [0|500] "kPa" Vector__XXX
 SG_ EngAirFilter4DiffPress : 16|8@1+ (0.05,0) [0|12.5] "kPa" Vector__XXX
 SG_ EngAirFilter3DiffPress : 8|8@1+ (0.05,0) [0|12.5] "kPa" Vector__XXX
 SG_ EngAirFilter2DiffPress : 0|8@1+ (0.05,0) [0|12.5] "kPa" Vector__XXX

BO_ 2566846206 IC1: 8 Vector__XXX
 SG_ EngCoolantFilterDiffPress : 56|8@1+ (0.5,0) [0|125] "kPa" Vector__XXX
 SG_ EngExhaustGasTemp : 40|16@1+ (0.03125,-273) [-273|1734.96875] "°C" Vector__XXX
 SG_ EngAirFilter1DiffPress : 32|8@1+ (0.05,0) [0|12.5] "kPa" Vector__XXX
 SG_ EngAirIntakePress : 24|8@1+ (2,0) [0|500] "kPa" Vector__XXX
 SG_ EngIntakeManifold1Temp : 16|8@1+ (1,-40) [-40|210] "°C" Vector__XXX
 SG_ EngIntakeManifold1Press : 8|8@1+ (2,0) [0|500] "kPa" Vector__XXX
 SG_ AFT1DPFInPress : 0|8@1+ (0.5,0) [0|125] "kPa" Vector__XXX

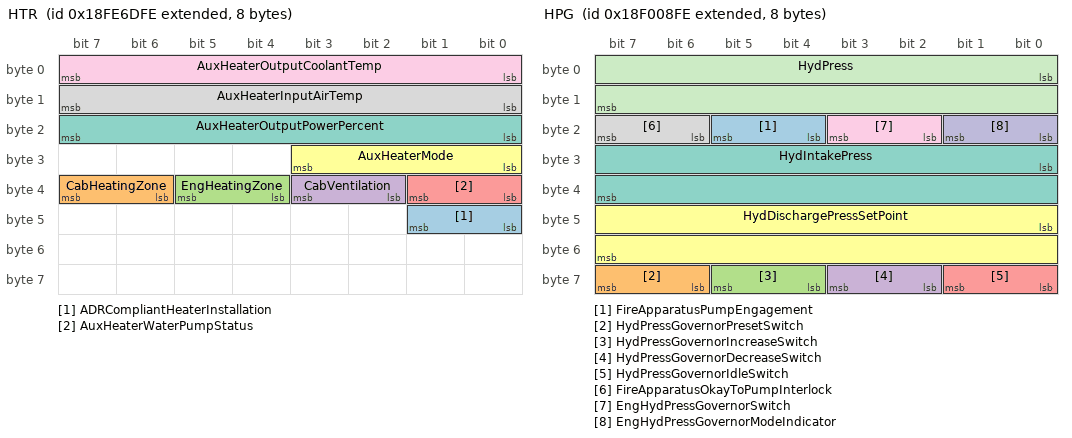
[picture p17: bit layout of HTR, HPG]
BO_ 2566811134 HTR: 8 Vector__XXX
 SG_ ADRCompliantHeaterInstallation : 40|2@1+ (1,0) [0|3] "" Vector__XXX
 SG_ CabHeatingZone : 38|2@1+ (1,0) [0|3] "" Vector__XXX
 SG_ EngHeatingZone : 36|2@1+ (1,0) [0|3] "" Vector__XXX
 SG_ CabVentilation : 34|2@1+ (1,0) [0|3] "" Vector__XXX
 SG_ AuxHeaterWaterPumpStatus : 32|2@1+ (1,0) [0|3] "" Vector__XXX
 SG_ AuxHeaterMode : 24|4@1+ (1,0) [0|15] "" Vector__XXX
 SG_ AuxHeaterOutputPowerPercent : 16|8@1+ (0.4,0) [0|100] "%" Vector__XXX
 SG_ AuxHeaterInputAirTemp : 8|8@1+ (1,-40) [-40|210] "°C" Vector__XXX
 SG_ AuxHeaterOutputCoolantTemp : 0|8@1+ (1,-40) [-40|210] "°C" Vector__XXX

BO_ 2298375934 HRW: 8 Vector__XXX
 SG_ RearAxleRightWheelSpeed : 48|16@1+ (0.00390625,0) [0|250.996] "km/h" Vector__XXX
 SG_ RearAxleLeftWheelSpeed : 32|16@1+ (0.00390625,0) [0|250.996] "km/h" Vector__XXX
 SG_ FrontAxleRightWheelSpeed : 16|16@1+ (0.00390625,0) [0|250.996] "km/h" Vector__XXX
 SG_ FrontAxleLeftWheelSpeed : 0|16@1+ (0.00390625,0) [0|250.996] "km/h" Vector__XXX

BO_ 2565867774 HPG: 8 Vector__XXX
 SG_ FireApparatusPumpEngagement : 20|2@1+ (1,0) [0|3] "" Vector__XXX
 SG_ HydPressGovernorPresetSwitch : 62|2@1+ (1,0) [0|3] "" Vector__XXX
 SG_ HydPressGovernorIncreaseSwitch : 60|2@1+ (1,0) [0|3] "" Vector__XXX
 SG_ HydPressGovernorDecreaseSwitch : 58|2@1+ (1,0) [0|3] "" Vector__XXX
 SG_ HydPressGovernorIdleSwitch : 56|2@1+ (1,0) [0|3] "" Vector__XXX
 SG_ HydDischargePressSetPoint : 40|16@1+ (2,0) [0|128510] "kPa" Vector__XXX
 SG_ HydIntakePress : 24|16@1+ (0.0001220703125,-1) [-1|6.84362793] "MPa" Vector__XXX
 SG_ FireApparatusOkayToPumpInterlock : 22|2@1+ (1,0) [0|3] "" Vector__XXX
 SG_ EngHydPressGovernorSwitch : 18|2@1+ (1,0) [0|3] "" Vector__XXX
 SG_ EngHydPressGovernorModeIndicator : 16|2@1+ (1,0) [0|3] "" Vector__XXX
 SG_ HydPress : 0|16@1+ (2,0) [0|128510] "kPa" Vector__XXX

BO_ 2566841854 HOURS: 8 Vector__XXX
 SG_ EngTotalRevolutions : 32|32@1+ (1000,0) [0|4211081215000] "r" Vector__XXX
 SG_ EngTotalHoursOfOperation : 0|32@1+ (0.05,0) [0|210554060.75] "h" Vector__XXX

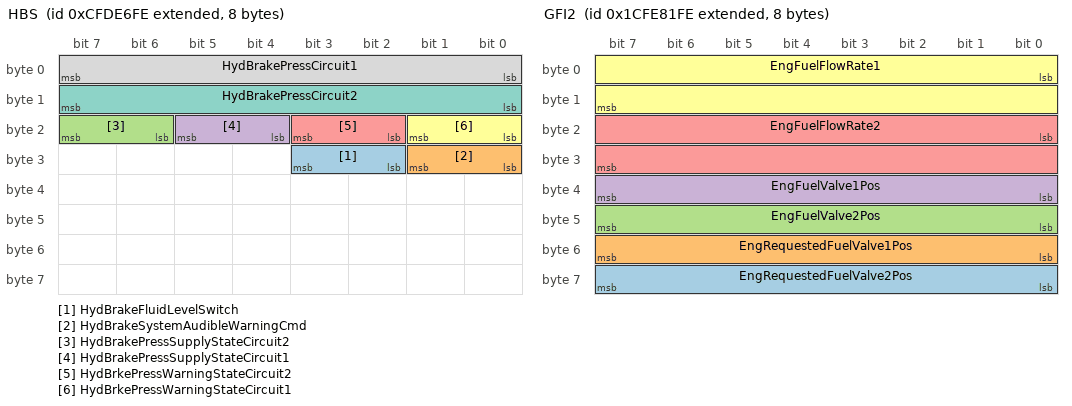
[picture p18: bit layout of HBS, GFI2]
BO_ 2365449982 HBS: 8 Vector__XXX
 SG_ HydBrakeFluidLevelSwitch : 26|2@1+ (1,0) [0|3] "" Vector__XXX
 SG_ HydBrakeSystemAudibleWarningCmd : 24|2@1+ (1,0) [0|3] "" Vector__XXX
 SG_ HydBrakePressSupplyStateCircuit2 : 22|2@1+ (1,0) [0|3] "" Vector__XXX
 SG_ HydBrakePressSupplyStateCircuit1 : 20|2@1+ (1,0) [0|3] "" Vector__XXX
 SG_ HydBrkePressWarningStateCircuit2 : 18|2@1+ (1,0) [0|3] "" Vector__XXX
 SG_ HydBrkePressWarningStateCircuit1 : 16|2@1+ (1,0) [0|3] "" Vector__XXX
 SG_ HydBrakePressCircuit2 : 8|8@1+ (100,0) [0|25000] "kPa" Vector__XXX
 SG_ HydBrakePressCircuit1 : 0|8@1+ (100,0) [0|25000] "kPa" Vector__XXX

BO_ 2633939198 GTFI: 22 Vector__XXX
 SG_ TripDriveFuelEconomy : 160|16@1+ (0.001953125,0) [0|125.498046875] "km/kg" Vector__XXX
 SG_ TripCruiseFuelUsed : 128|32@1+ (0.5,0) [0|2105540607.5] "kg" Vector__XXX
 SG_ TripVehicleIdleFuelUsed : 96|32@1+ (0.5,0) [0|2105540607.5] "kg" Vector__XXX
 SG_ TripPTOGovernorNonmovingFuelUsed : 64|32@1+ (0.5,0) [0|2105540607.5] "kg" Vector__XXX
 SG_ TripPTOGovernorMovingFuelUsed : 32|32@1+ (0.5,0) [0|2105540607.5] "kg" Vector__XXX
 SG_ TripDriveFuelUsed : 0|32@1+ (0.5,0) [0|2105540607.5] "kg" Vector__XXX

BO_ 2633927678 GFP: 8 Vector__XXX
 SG_ EngFuelValve1OutletAbsPress : 48|16@1+ (0.1,0) [0|6425.5] "kPa" Vector__XXX
 SG_ EngAirToFuelDiffPress : 32|16@1+ (0.1,0) [0|6425.5] "kPa" Vector__XXX
 SG_ EngFuelValveDiffPress : 16|16@1+ (0.1,0) [0|6425.5] "kPa" Vector__XXX
 SG_ EngFuelValve1IntakeAbsPress : 0|16@1+ (0.1,0) [0|6425.5] "kPa" Vector__XXX

BO_ 2633925118 GFI2: 8 Vector__XXX
 SG_ EngRequestedFuelValve2Pos : 56|8@1+ (0.4,0) [0|100] "%" Vector__XXX
 SG_ EngRequestedFuelValve1Pos : 48|8@1+ (0.4,0) [0|100] "%" Vector__XXX
 SG_ EngFuelValve2Pos : 40|8@1+ (0.4,0) [0|100] "%" Vector__XXX
 SG_ EngFuelValve1Pos : 32|8@1+ (0.4,0) [0|100] "%" Vector__XXX
 SG_ EngFuelFlowRate2 : 16|16@1+ (0.1,0) [0|6425.5] "m³/h" Vector__XXX
 SG_ EngFuelFlowRate1 : 0|16@1+ (0.1,0) [0|6425.5] "m³/h" Vector__XXX

BO_ 2633937662 GFI1: 8 Vector__XXX
 SG_ EngFuelSpecificGravity : 48|16@1+ (0.0001,0) [0|2] "" Vector__XXX
 SG_ TripAverageFuelRate : 32|16@1+ (0.05,0) [0|3212.75] "kg/h" Vector__XXX
 SG_ TotalEngPTOGovernorFuelUsed : 0|32@1+ (0.5,0) [0|2105540607.5] "kg" Vector__XXX

BO_ 2566804990 GFD: 8 Vector__XXX
 SG_ FuelEnergyContent : 32|16@1+ (0.00390625,0) [0|250.996] "MJ/Nm³" Vector__XXX
 SG_ ReferenceEngGasMassFlowRate : 16|16@1+ (0.05,0) [0|3212.75] "kg/h" Vector__XXX
 SG_ SpecificHeatRatio : 0|16@1+ (0.001,0) [0|2] "" Vector__XXX

BO_ 2633936894 GFC: 8 Vector__XXX
 SG_ TotalFuelUsed : 32|32@1+ (0.5,0) [0|2105540607.5] "kg" Vector__XXX
 SG_ TripFuel : 0|32@1+ (0.5,0) [0|2105540607.5] "kg" Vector__XXX

BO_ 2566757630 SEP2: 8 Vector__XXX
 SG_ SensorSupplyVoltage8 : 48|16@1+ (0.05,0) [0|3212.75] "V" Vector__XXX
 SG_ SensorSupplyVoltage7 : 32|16@1+ (0.05,0) [0|3212.75] "V" Vector__XXX
 SG_ SensorSupplyVoltage6 : 16|16@1+ (0.05,0) [0|3212.75] "V" Vector__XXX
 SG_ SensorSupplyVoltage5 : 0|16@1+ (0.05,0) [0|3212.75] "V" Vector__XXX

BO_ 2566757886 SEP1: 8 Vector__XXX
 SG_ SensorSupplyVoltage4 : 48|16@1+ (0.05,0) [0|3212.75] "V" Vector__XXX
 SG_ SensorSupplyVoltage3 : 32|16@1+ (0.05,0) [0|3212.75] "V" Vector__XXX
 SG_ SensorSupplyVoltage2 : 16|16@1+ (0.05,0) [0|3212.75] "V" Vector__XXX
 SG_ SensorSupplyVoltage1 : 0|16@1+ (0.05,0) [0|3212.75] "V" Vector__XXX

BO_ 2566759678 PTODE: 8 Vector__XXX
 SG_ AtLeastOnePTOEngaged : 48|2@1+ (1,0) [0|3] "" Vector__XXX
 SG_ EnggmntSttsPTOEngAccessoryDrive2 : 44|2@1+ (1,0) [0|3] "" Vector__XXX
 SG_ EnggmntSttsPTOEngAccessoryDrive1 : 42|2@1+ (1,0) [0|3] "" Vector__XXX
 SG_ EngagementStatusPTOEngFlywheel : 40|2@1+ (1,0) [0|3] "" Vector__XXX
 SG_ EnggmntStatusTransInputShaftPTO1 : 38|2@1+ (1,0) [0|3] "" Vector__XXX
 SG_ EnggmntStatusTransInputShaftPTO2 : 36|2@1+ (1,0) [0|3] "" Vector__XXX
 SG_ EnggmntStatusTransOutputShaftPTO : 34|2@1+ (1,0) [0|3] "" Vector__XXX
 SG_ EnggmntSttsTrnsfrCsOtputShaftPTO : 32|2@1+ (1,0) [0|3] "" Vector__XXX
 SG_ EnggmntCnsntPTOEngAccssoryDrive2 : 28|2@1+ (1,0) [0|3] "" Vector__XXX
 SG_ EnggmntCnsntPTOEngAccssoryDrive1 : 26|2@1+ (1,0) [0|3] "" Vector__XXX
 SG_ EngagementConsentPTOEngFlywheel : 24|2@1+ (1,0) [0|3] "" Vector__XXX
 SG_ EnggmntCnsentTransInputShaftPTO1 : 22|2@1+ (1,0) [0|3] "" Vector__XXX
 SG_ EnggmntCnsentTransInputShaftPTO2 : 20|2@1+ (1,0) [0|3] "" Vector__XXX
 SG_ EnggmntCnsentTransOutputShaftPTO : 18|2@1+ (1,0) [0|3] "" Vector__XXX
 SG_ EnggmntCnsntTrnsfrCsOtptShaftPTO : 16|2@1+ (1,0) [0|3] "" Vector__XXX
 SG_ EnbleSwitchPTOEngAccessoryDrive2 : 12|2@1+ (1,0) [0|3] "" Vector__XXX
 SG_ EnbleSwitchPTOEngAccessoryDrive1 : 10|2@1+ (1,0) [0|3] "" Vector__XXX
 SG_ EnableSwitchPTOEngFlywheel : 8|2@1+ (1,0) [0|3] "" Vector__XXX
 SG_ EnableSwitchTransInputShaftPTO1 : 6|2@1+ (1,0) [0|3] "" Vector__XXX
 SG_ EnableSwitchTransInputShaftPTO2 : 4|2@1+ (1,0) [0|3] "" Vector__XXX
 SG_ EnableSwitchTransOutputShaftPTO : 2|2@1+ (1,0) [0|3] "" Vector__XXX
 SG_ EnblSwtchTrnsfrCseOutputShaftPTO : 0|2@1+ (1,0) [0|3] "" Vector__XXX

BO_ 2432541438 GFI3: 8 Vector__XXX
 SG_ EngFuelValve2OutletAbsPress : 48|16@1+ (0.1,0) [0|6425.5] "kPa" Vector__XXX
 SG_ EngFuelTemp2 : 32|8@1+ (1,-40) [-40|210] "°C" Vector__XXX
 SG_ EngGas2MassFlowRate : 16|16@1+ (0.05,0) [0|3212.75] "kg/h" Vector__XXX
 SG_ EngFuelValve2IntakeAbsPress : 0|16@1+ (0.1,0) [0|6425.5] "kPa" Vector__XXX

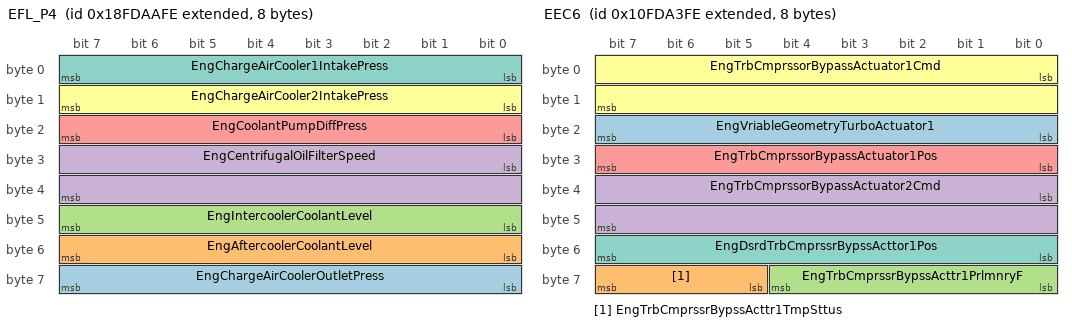
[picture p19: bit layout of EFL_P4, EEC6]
BO_ 2566761214 EFL_P4: 8 Vector__XXX
 SG_ EngChargeAirCoolerOutletPress : 56|8@1+ (2,0) [0|500] "kPa" Vector__XXX
 SG_ EngAftercoolerCoolantLevel : 48|8@1+ (0.4,0) [0|100] "%" Vector__XXX
 SG_ EngIntercoolerCoolantLevel : 40|8@1+ (0.4,0) [0|100] "%" Vector__XXX
 SG_ EngCentrifugalOilFilterSpeed : 24|16@1+ (4,0) [0|257020] "rpm" Vector__XXX
 SG_ EngCoolantPumpDiffPress : 16|8@1+ (1.64,-7) [-7|403] "kPa" Vector__XXX
 SG_ EngChargeAirCooler2IntakePress : 8|8@1+ (2,0) [0|500] "kPa" Vector__XXX
 SG_ EngChargeAirCooler1IntakePress : 0|8@1+ (2,0) [0|500] "kPa" Vector__XXX

BO_ 2432541694 EEC6: 8 Vector__XXX
 SG_ EngVriableGeometryTurboActuator1 : 16|8@1+ (0.4,0) [0|100] "%" Vector__XXX
 SG_ EngTrbCmprssrBypssActtr1TmpSttus : 61|3@1+ (1,0) [0|7] "" Vector__XXX
 SG_ EngTrbCmprssrBypssActtr1PrlmnryF : 56|5@1+ (1,0) [0|31] "" Vector__XXX
 SG_ EngTrbCmprssorBypassActuator2Cmd : 32|16@1+ (0.0025,0) [0|160.6375] "%" Vector__XXX
 SG_ EngTrbCmprssorBypassActuator1Pos : 24|8@1+ (0.4,0) [0|100] "%" Vector__XXX
 SG_ EngTrbCmprssorBypassActuator1Cmd : 0|16@1+ (0.0025,0) [0|100] "%" Vector__XXX
 SG_ EngDsrdTrbCmprssrBypssActtor1Pos : 48|8@1+ (0.4,0) [0|100] "%" Vector__XXX

BO_ 2566759934 DC2: 8 Vector__XXX
 SG_ EnableStatusOfDoor10 : 58|2@1+ (1,0) [0|3] "" Vector__XXX
 SG_ OpenStatusOfDoor10 : 56|2@1+ (1,0) [0|3] "" Vector__XXX
 SG_ LockStatusOfDoor10 : 54|2@1+ (1,0) [0|3] "" Vector__XXX
 SG_ EnableStatusOfDoor9 : 52|2@1+ (1,0) [0|3] "" Vector__XXX
 SG_ OpenStatusOfDoor9 : 50|2@1+ (1,0) [0|3] "" Vector__XXX
 SG_ LockStatusOfDoor9 : 48|2@1+ (1,0) [0|3] "" Vector__XXX
 SG_ EnableStatusOfDoor8 : 46|2@1+ (1,0) [0|3] "" Vector__XXX
 SG_ OpenStatusOfDoor8 : 44|2@1+ (1,0) [0|3] "" Vector__XXX
 SG_ LockStatusOfDoor8 : 42|2@1+ (1,0) [0|3] "" Vector__XXX
 SG_ EnableStatusOfDoor7 : 40|2@1+ (1,0) [0|3] "" Vector__XXX
 SG_ OpenStatusOfDoor7 : 38|2@1+ (1,0) [0|3] "" Vector__XXX
 SG_ LockStatusOfDoor7 : 36|2@1+ (1,0) [0|3] "" Vector__XXX
 SG_ EnableStatusOfDoor6 : 34|2@1+ (1,0) [0|3] "" Vector__XXX
 SG_ OpenStatusOfDoor6 : 32|2@1+ (1,0) [0|3] "" Vector__XXX
 SG_ LockStatusOfDoor6 : 30|2@1+ (1,0) [0|3] "" Vector__XXX
 SG_ EnableStatusOfDoor5 : 28|2@1+ (1,0) [0|3] "" Vector__XXX
 SG_ OpenStatusOfDoor5 : 26|2@1+ (1,0) [0|3] "" Vector__XXX
 SG_ LockStatusOfDoor5 : 24|2@1+ (1,0) [0|3] "" Vector__XXX
 SG_ EnableStatusOfDoor4 : 22|2@1+ (1,0) [0|3] "" Vector__XXX
 SG_ OpenStatusOfDoor4 : 20|2@1+ (1,0) [0|3] "" Vector__XXX
 SG_ LockStatusOfDoor4 : 18|2@1+ (1,0) [0|3] "" Vector__XXX
 SG_ EnableStatusOfDoor3 : 16|2@1+ (1,0) [0|3] "" Vector__XXX
 SG_ OpenStatusOfDoor3 : 14|2@1+ (1,0) [0|3] "" Vector__XXX
 SG_ LockStatusOfDoor3 : 12|2@1+ (1,0) [0|3] "" Vector__XXX
 SG_ EnableStatusOfDoor2 : 10|2@1+ (1,0) [0|3] "" Vector__XXX
 SG_ OpenStatusOfDoor2 : 8|2@1+ (1,0) [0|3] "" Vector__XXX
 SG_ LockStatusOfDoor2 : 6|2@1+ (1,0) [0|3] "" Vector__XXX
 SG_ EnableStatusOfDoor1 : 4|2@1+ (1,0) [0|3] "" Vector__XXX
 SG_ OpenStatusOfDoor1 : 2|2@1+ (1,0) [0|3] "" Vector__XXX
 SG_ LockStatusOfDoor1 : 0|2@1+ (1,0) [0|3] "" Vector__XXX

CM_ BO_ 2566718974 "Direct Lamp Control Data 1
This message will be transmitted by the controller that is illuminating the lamps.

It is not required to be used with PGN 64775.";
CM_ SG_ 2566718974 VhclAcclerationRateLimitLampData "This parameter provides measured data from the Vehicle Acceleration Rate Limit Lamp.

00 - Lamp deactivated (Off)
01 - Lamp activated (On)
10 - Error
11 - Not available";
CM_ SG_ 2566718974 EngSpeedVeryHighLampData "This parameter provides measured data from the Engine Speed Very High Warning Lamp.

00 - Lamp Deactivated (Off)
01 - Lamp Activated (On)
10 - Error
11 - Not available";
CM_ SG_ 2566718974 EngSpeedHighLampData "This parameter provides measured data from the Engine Speed High Warning Lamp.

00 - Lamp Deactivated (Off)
01 - Lamp Activated (On)
10 - Error
11 - Not available";
CM_ SG_ 2566718974 EngCtrlMdule3ReadyForUseLampData "This parameter provides measured data from the Engine Control Module 3 Ready for Use Lamp.

00 - Lamp deactivated (Off)
01 - Lamp activated (On)
10 - Error
11 - Not Available";
CM_ SG_ 2566718974 EngCtrlMdule2ReadyForUseLampData "This parameter provides measured data from the Engine Control Module 2 Ready for Use Lamp.

00 - Lamp deactivated (Off)
01 - Lamp activated (On)
10 - Error
11 - Not Available";
CM_ SG_ 2566718974 EngCtrlMdule1ReadyForUseLampData "This parameter provides measured data from the Engine Control Module 1 Ready for Use Lamp.

00 - Lamp deactivated (Off)
01 - Lamp activated (On)
10 - Error
11 - Not Available";
CM_ SG_ 2566718974 EngWaitToStartLampData "This parameter provides measured data from the Engine Wait To Start Lamp.  See SPN 1081 for the command.

00 - Lamp deactived (off)
01 - Lamp actived (on)
10 - Error
11 - Not available";
CM_ SG_ 2566718974 EngFuelFilterRestrictedLampData "This parameter provides measured data from the Engine Fuel Filter Restricted Lamp.

00 - Lamp deactivated (Off)
01 - Lamp activated (On)
10 - Error
11 - Not available";
CM_ SG_ 2566718974 EngAirFilterRestrictionLampData "This parameter provides measured data from the Engine Air Filter Restriction Lamp.

00 - Lamp deactivated (Off)
01 - Lamp activated (On)
10 - Error
11 - Not available";
CM_ SG_ 2566718974 EngIdleManagementActiveLampData "This parameter provides measured data from the Engine Idle Management Active Lamp.

00 - Lamp deactivated (Off)
01 - Lamp activated (On)
10 - Error
11 - Not available";
CM_ SG_ 2566718974 EngCoolantLevelLowLampData "This parameter provides measured data from the Engine Coolant Level Low Lamp.

00 - Lamp deactivated (Off)
01 - Lamp activated (On)
10 - Error
11 - Not available";
CM_ SG_ 2566718974 EngCoolantTempHighLampData "This parameter provides measured data from the Engine Coolant Temperature High Lamp.

00 - Lamp deactivated (Off)
01 - Lamp activated (On)
10 - Error
11 - Not available";
CM_ SG_ 2566718974 EngOilPressLowLampData "This parameter provides measured data from the Engine Oil Pressure Low Lamp.

00 - Lamp deactivated (Off)
01 - Lamp activated (On)
10 - Error
11 - Not available";
CM_ SG_ 2566718974 CmprssnBrkEnblSwtchIndctrLmpData "This parameter provides measured data from the Compression Brake Enable Switch Indicator Lamp.

00 - Lamp deactivated (Off)
01 - Lamp activated (On)
10 - Error
11 - Not available";
CM_ SG_ 2566718974 EngBrakeActiveLampData "This parameter provides measured data from the Engine Brake Active Lamp.

00 - Lamp deactivated (Off)
01 - Lamp activated (On)
10 - Error
11 - Not available";
CM_ SG_ 2566718974 OBDMalfunctionIndicatorLampData "This parameter provides measured data from the OBD Malfunction Indicator Lamp.

00 - Lamp deactivated (Off)
01 - Lamp activated (On)
10 - Error
11 - Not available";
CM_ SG_ 2566718974 EngRedStopLampData "This parameter provides measured data from the Engine Red Stop Lamp.

00 - Lamp deactivated (Off)
01 - Lamp activated (On)
10 - Error
11 - Not available";
CM_ SG_ 2566718974 EngAmberWarningLampData "This parameter provides measured data from the Engine Amber Warning Lamp.

00 - Lamp deactivated (Off)
01 - Lamp activated (On)
10 - Error
11 - Not available";
CM_ SG_ 2566718974 EngProtectLampData "This parameter provides measured data from the Engine Protect Lamp.

00 - Lamp deactivated (Off)
01 - Lamp activated (On)
10 - Error
11 - Not available";
CM_ BO_ 2566719230 "Direct Lamp Control Command 2
Message that directly controls the driver indicator lamps.   See also PGN 64775 for additional lamps and PGN 64772 for the feedback information about these lamps.
Note: Since this message is direct lamp control, it is ...";
CM_ SG_ 2566719230 HillHolderLampCmd "Command signal directly controlling Hill Holder Lamp.

00 - Lamp Off
01 - Lamp On
10 - Lamp Flash (1 Hz)
11 - Not available";
CM_ SG_ 2566719230 VehicleBatteryChargingLampCmd "Command signal directly controlling the Vehicle Battery Charging Lamp.

00 - Lamp Off
01 - Lamp On
10 - Reserved
11 - Not available";
CM_ SG_ 2566719230 VehicleHVACRecirculationLampCmd "Command signal directly controlling the Vehicle HVAC Recirculation Lamp.

00 - Lamp Off
01 - Lamp On
10 - Reserved
11 - Not available";
CM_ SG_ 2566719230 VehicleAirPressLowLampCmd "Command signal directly controlling the Vehicle Air Pressure Low Lamp.

00 - Lamp Off
01 - Lamp On
10 - Reserved
11 - Not available";
CM_ SG_ 2566719230 VehicleFuelLevelLowLampCmd "Command signal directly controlling the Vehicle Fuel Level Low Lamp.

00 - Lamp Off
01 - Lamp On
10 - Reserved
11 - Not available";
CM_ SG_ 2566719230 VehicleBatteryVoltageLowLampCmd "Command signal directly controlling the Vehicle Battery Voltage Low Lamp.

00 - Lamp Off
01 - Lamp On
10 - Reserved
11 - Not available";
CM_ BO_ 2560818942 "Regulated Exhaust Emission Level Exceedance
Provides the DTCs and associated timers related to a regulated exhaust emission level exceedance due to an emission control system malfunction.";
CM_ SG_ 2560818942 SPN1 "This 19-bit number is used to identify the item for which diagnostics are being reported.";
CM_ SG_ 2560818942 FailureModeIdentifier1 "The FMI defines the type of failure detected in the subsystem identified by an SPN.";
CM_ SG_ 2560818942 DTCTimeUntilDerate "This timer provides the number of hours the malfunction has until the OBD required derate will occur";
CM_ SG_ 2560818942 DTCTotalPrevActiveTime "This timer provides the number of hours the NOx malfunction has been confirmed and previously active";
CM_ SG_ 2560818942 DTCTotalActiveTime "This timer provides the total number of hours the DTC has been confirmed and active";
CM_ SG_ 2560818942 SPN1High "SPN #1 (Conversion Version 4)";
CM_ BO_ 2561212158 "Text Display
This provides ASCII text information, for example to an display instrument.  Broadcast rate should be on event and 1-5 seconds due to variable character length.  This message is to convey information from an ecu to a display.  In its ...";
CM_ SG_ 2561212158 TextDisplayIndex "Used for overwriting consecutive bytes of a displayed string when byte 1 'Text Display Instructions' state is set for 'overwrite substring' mode.  When used, this byte declares where in the text string that the new text will start overwriting, this ...";
CM_ SG_ 2561212158 TextDisplayInstructions "This parameter describes the status for the display how to show the information.
0000 Clear display - The displayed information should be deleted or not displayed any more.
0001 Hold display - The presently displayed information should be retained
 ...";
CM_ BO_ 2566746366 "Door ramp control
This message reports the current status of door ramps";
CM_ SG_ 2566746366 RetractStatusOfRamp5 "Retract status of ramp at doorway 5, counting from front to back on the vehicle.
 
00 ramp retracted
01 ramp extended
10 error
11 not available";
CM_ SG_ 2566746366 RetractStatusOfRamp4 "Retract status of ramp at doorway 4, counting from front to back on the vehicle.
 
00 ramp retracted
01 ramp extended
10 error
11 not available";
CM_ SG_ 2566746366 MovementStatusOfRamp5 "Movement status of ramp at doorway 5, counting from front to back on the vehicle.

00 ramp not being moved
01 ramp being moved
10 error
11 not available";
CM_ SG_ 2566746366 MovementStatusOfRamp4 "Movement status of ramp at doorway 4, counting from front to back on the vehicle.

00 ramp not being moved
01 ramp being moved
10 error
11 not available";
CM_ SG_ 2566746366 EnableStatusOfRamp5 "Enable status of ramp at doorway 5, counting from front to back on the vehicle.

00 ramp disabled
01 ramp enabled 
10 error 
11 not available";
CM_ SG_ 2566746366 EnableStatusOfRamp4 "Enable status of ramp at doorway 4, counting from front to back on the vehicle.

00 ramp disabled
01 ramp enabled 
10 error 
11 not available";
CM_ SG_ 2566746366 MovementStatusOfRamp3 "Movement status of ramp at doorway 3, counting from front to back on the vehicle.

00 ramp not being moved
01 ramp being moved
10 error
11 not available";
CM_ SG_ 2566746366 EnableStatusOfRamp3 "Enable status of ramp at doorway 3, counting from front to back on the vehicle.

00 ramp disabled
01 ramp enabled 
10 error 
11 not available";
CM_ SG_ 2566746366 RetractStatusOfRamp3 "Retract status of ramp at doorway 3, counting from front to back on the vehicle.

00 ramp retracted
01 ramp extended
10 error
11 not available";
CM_ SG_ 2566746366 MovementStatusOfRamp2 "Movement status of ramp at doorway 2, counting from front to back on the vehicle.

00 ramp not being moved
01 ramp being moved
10 error
11 not available";
CM_ SG_ 2566746366 EnableStatusOfRamp2 "Enable status of ramp at doorway 2, counting from front to back on the vehicle.

00 ramp disabled
01 ramp enabled 
10 error 
11 not available";
CM_ SG_ 2566746366 RetractStatusOfRamp2 "Retract status of ramp at doorway 2, counting from front to back on the vehicle.

00 ramp retracted
01 ramp extended
10 error
11 not available";
CM_ SG_ 2566746366 MovementStatusOfRamp1 "Movement status of ramp at doorway 1, counting from front to back on the vehicle.

00 ramp not being moved
01 ramp being moved
10 error
11 not available";
CM_ SG_ 2566746366 EnableStatusOfRamp1 "Enable status of ramp at doorway 1, counting from front to back on the vehicle.

        00 ramp disabled
        01 ramp enabled 
       10 error 
       11 not available";
CM_ SG_ 2566746366 RetractStatusOfRamp1 "Retract status of ramp at doorway 1, counting from front to back on the vehicle.
 
00 ramp retracted
01 ramp extended
10 error
11 not available";
CM_ BO_ 2566750206 "Engine Configuration 2
Contains static information about the engine.  To be used with data that will not change during vehicle operation.
.";
CM_ SG_ 2566750206 EngConfigIdentification "Used to identify the hardware configuration of engine family. Each number will have a reference to set of parameters such as, but not limited to, number of cylinders, piston displacement, bore size and firing angles.";
CM_ SG_ 2566750206 NmbrOfCmbstionCyclesForAveraging "Defined number of combustion cycles used for calculating average parameters of combustion in each cylinder.";
CM_ SG_ 2566750206 MaxCrankAttemptsPerStartAttempt "The number of cranking cycles that will be performed before ending the start attempt.  This is intended to be used in conjunction with Crank Attempt Count on Present Start Attempt, in order to give a FMI 0 diagnostic on the latter.";
CM_ BO_ 2566755582 "Electronic Engine Controller 7
Engine related parameters";
CM_ SG_ 2566755582 CommandedEngIntakeManifoldPress "Provides the commanded set point value for the engine intake manifold pressure.";
CM_ SG_ 2566755582 EngCrnkcsBrtherOilSeparatorSpeed "The speed of a rotating (centrifugal) crankcase oil separator.";
CM_ SG_ 2566755582 EngExhstGsRcirculation1Valve2Pos "The position of the second exhaust gas recirculation valve expressed as a percentage of full travel. Zero percent means the valve is closed and no exhaust gas is flowing into the intake air stream. One hundred percent means the valve is fully ...";
CM_ SG_ 2566755582 EngExhstGsRecirculation1ValvePos "The position of the exhaust gas recirculation valve expressed as a percentage of full travel. Zero percent means the valve is closed and no exhaust gas is flowing into the intake air stream. One hundred percent means the valve is fully opened.";
CM_ BO_ 2566746110 "Electronic Engine Controller 8
Engine related parameters";
CM_ SG_ 2566746110 EngExhstGsRcrcltn1ClerEfficiency "Exhaust Gas Recirculation cooler efficiency is an indication of the cooler's ability to reduce the temperature of the exhaust gas that is being recirculated back to the intake. 0% = no reduction in temperature, 100% = maximum cooling.  The EGR ...";
CM_ SG_ 2566746110 EngExhstGsRcrcltn1ClrIntkGsAbsPr "Exhaust gas recirculation absolute pressure is measured at the EGR cooler intake. See SPN 3358 for EGR pressure measured at the EGR cooler outlet before the valve.";
CM_ SG_ 2566746110 EngExhstGsRcrcltn1ClerIntakeTemp "Exhaust Gas Recirculation (EGR) Temperature measured at the EGR cooler intake.  See SPN 412 for Engine EGR temperature which is typically measured at the EGR cooler outlet.";
CM_ SG_ 2566746110 EngExhstGsRcrculation1Valve2Ctrl "Desired percentage of maximum Exhaust Gas Recirculation (EGR) valve opening for valve 2.  0% means valve is closed. 100% means maximum valve opening (full gas flow).";
CM_ BO_ 2566752510 "Engine Fluid Level/Pressure 5
This message contains Engine Intake Valve Actuation Oil Pressure information.";
CM_ SG_ 2566752510 EngIntkVlvActtionOilPressForCyl4 "The gage pressure of the oil in the hydraulic accumulator that powers the engine intake valve for cylinder #4.";
CM_ SG_ 2566752510 EngIntkVlvActtionOilPressForCyl3 "The gage pressure of the oil in the hydraulic accumulator that powers the engine intake valve for cylinder #3.";
CM_ SG_ 2566752510 EngIntkVlvActtionOilPressForCyl2 "The gage pressure of the oil in the hydraulic accumulator that powers the engine intake valve for cylinder #2.";
CM_ SG_ 2566752510 EngIntkVlvActtionOilPressForCyl1 "The gage pressure of the oil in the hydraulic accumulator that powers the engine intake valve for cylinder #1.
This intake valve pressure is at the first cylinder in the engine, while SPN 2948 reflects the intake valve pressure of the entire engine ...";
CM_ BO_ 2566752254 "Engine Fluid Level/Pressure 6
This message contains Engine Intake Valve Actuation Oil Pressure information.";
CM_ SG_ 2566752254 EngIntkVlvActtionOilPressForCyl8 "The gage pressure of the oil in the hydraulic accumulator that powers the engine intake valve for cylinder #8.";
CM_ SG_ 2566752254 EngIntkVlvActtionOilPressForCyl7 "The gage pressure of the oil in the hydraulic accumulator that powers the engine intake valve for cylinder #7.";
CM_ SG_ 2566752254 EngIntkVlvActtionOilPressForCyl6 "The gage pressure of the oil in the hydraulic accumulator that powers the engine intake valve for cylinder #6.";
CM_ SG_ 2566752254 EngIntkVlvActtionOilPressForCyl5 "The gage pressure of the oil in the hydraulic accumulator that powers the engine intake valve for cylinder #5.";
CM_ BO_ 2566751998 "Engine Fluid Level/Pressure 7
This message contains Engine Intake Valve Actuation Oil Pressure information.";
CM_ SG_ 2566751998 EngIntkVlvActtonOilPressForCyl12 "The gage pressure of the oil in the hydraulic accumulator that powers the engine intake valve for cylinder #12.";
CM_ SG_ 2566751998 EngIntkVlvActtonOilPressForCyl11 "The gage pressure of the oil in the hydraulic accumulator that powers the engine intake valve for cylinder #11.";
CM_ SG_ 2566751998 EngIntkVlvActtonOilPressForCyl10 "The gage pressure of the oil in the hydraulic accumulator that powers the engine intake valve for cylinder #10.";
CM_ SG_ 2566751998 EngIntkVlvActtionOilPressForCyl9 "The gage pressure of the oil in the hydraulic accumulator that powers the engine intake valve for cylinder #9.";
CM_ BO_ 2566751742 "Engine Fluid Level/Pressure 8
This message contains Engine Intake Valve Actuation Oil Pressure information.";
CM_ SG_ 2566751742 EngIntkVlvActtonOilPressForCyl16 "The gage pressure of the oil in the hydraulic accumulator that powers the engine intake valve for cylinder #16.";
CM_ SG_ 2566751742 EngIntkVlvActtonOilPressForCyl15 "The gage pressure of the oil in the hydraulic accumulator that powers the engine intake valve for cylinder #15.";
CM_ SG_ 2566751742 EngIntkVlvActtonOilPressForCyl14 "The gage pressure of the oil in the hydraulic accumulator that powers the engine intake valve for cylinder #14.";
CM_ SG_ 2566751742 EngIntkVlvActtonOilPressForCyl13 "The gage pressure of the oil in the hydraulic accumulator that powers the engine intake valve for cylinder #13.";
CM_ BO_ 2566751486 "Engine Fluid Level/Pressure 9
This message contains Engine Intake Valve Actuation Oil Pressure information.";
CM_ SG_ 2566751486 EngIntkVlvActtonOilPressForCyl20 "The gage pressure of the oil in the hydraulic accumulator that powers the engine intake valve for cylinder #20.";
CM_ SG_ 2566751486 EngIntkVlvActtonOilPressForCyl19 "The gage pressure of the oil in the hydraulic accumulator that powers the engine intake valve for cylinder #19.";
CM_ SG_ 2566751486 EngIntkVlvActtonOilPressForCyl18 "The gage pressure of the oil in the hydraulic accumulator that powers the engine intake valve for cylinder #18.";
CM_ SG_ 2566751486 EngIntkVlvActtonOilPressForCyl17 "The gage pressure of the oil in the hydraulic accumulator that powers the engine intake valve for cylinder #17.";
CM_ BO_ 2499641854 "EGR Cooler Bypass
Contains information about the EGR Cooler Bypass";
CM_ SG_ 2499641854 EGR1CoolerBypassActuatorPostion "The parameter gives the % open of the exhaust gas recirculation cooler bypass actuator, where 0% = Fully Closed (no gas flowing through the bypass), and 100% = Fully Open.";
CM_ BO_ 2566748158 "Engine Spark Voltage 1
The PGN contains information about spark voltage values for cylinders 1 through 4.  This is the secondary voltage of the combustion event.";
CM_ SG_ 2566748158 EngSparkPlug4 "The measured voltage of the spark event on Cylinder #4";
CM_ SG_ 2566748158 EngSparkPlug3 "The measured voltage of the spark event on Cylinder #3";
CM_ SG_ 2566748158 EngSparkPlug2 "The measured voltage of the spark event on Cylinder #2";
CM_ SG_ 2566748158 EngSparkPlug1 "The measured voltage of the spark event on Cylinder #1";
CM_ BO_ 2566747902 "Engine Spark Voltage 2
The PGN contains information about spark voltage values for cylinders 5 through 8.  This is the secondary voltage of the combustion event.";
CM_ SG_ 2566747902 EngSparkPlug8 "The measured voltage of the spark event on Cylinder #8";
CM_ SG_ 2566747902 EngSparkPlug7 "The measured voltage of the spark event on Cylinder #7";
CM_ SG_ 2566747902 EngSparkPlug6 "The measured voltage of the spark event on Cylinder #6";
CM_ SG_ 2566747902 EngSparkPlug5 "The measured voltage of the spark event on Cylinder #5";
CM_ BO_ 2566747646 "Engine Spark Voltage 3
The PGN contains information about spark voltage values for cylinders 9 through 12.  This is the secondary voltage of the combustion event.";
CM_ SG_ 2566747646 EngSparkPlug12 "The measured voltage of the spark event on Cylinder #12";
CM_ SG_ 2566747646 EngSparkPlug11 "The measured voltage of the spark event on Cylinder #11";
CM_ SG_ 2566747646 EngSparkPlug10 "The measured voltage of the spark event on Cylinder #10";
CM_ SG_ 2566747646 EngSparkPlug9 "The measured voltage of the spark event on Cylinder #9";
CM_ BO_ 2566747390 "Engine Spark Voltage 4
The PGN contains information about spark voltage values for cylinders 13 through 16.  This is the secondary voltage of the combustion event.";
CM_ SG_ 2566747390 EngSparkPlug16 "The measured voltage of the spark event on Cylinder #16";
CM_ SG_ 2566747390 EngSparkPlug15 "The measured voltage of the spark event on Cylinder #15";
CM_ SG_ 2566747390 EngSparkPlug14 "The measured voltage of the spark event on Cylinder #14";
CM_ SG_ 2566747390 EngSparkPlug13 "The measured voltage of the spark event on Cylinder #13";
CM_ BO_ 2566747134 "Engine Spark Voltage 5
The PGN contains information about spark voltage values for cylinders 17 through 20.  This is the secondary voltage of the combustion event.";
CM_ SG_ 2566747134 EngSparkPlug20 "The measured voltage of the spark event on Cylinder #20";
CM_ SG_ 2566747134 EngSparkPlug19 "The measured voltage of the spark event on Cylinder #19";
CM_ SG_ 2566747134 EngSparkPlug18 "The measured voltage of the spark event on Cylinder #18";
CM_ SG_ 2566747134 EngSparkPlug17 "The measured voltage of the spark event on Cylinder #17";
CM_ BO_ 2566746878 "Engine Spark Voltage 6
The PGN contains information about spark voltage values for cylinders 21 through 24.  This is the secondary voltage of the combustion event.";
CM_ SG_ 2566746878 EngSparkPlug24 "The measured voltage of the spark event on Cylinder #24";
CM_ SG_ 2566746878 EngSparkPlug23 "The measured voltage of the spark event on Cylinder #23";
CM_ SG_ 2566746878 EngSparkPlug22 "The measured voltage of the spark event on Cylinder #22";
CM_ SG_ 2566746878 EngSparkPlug21 "The measured voltage of the spark event on Cylinder #21";
CM_ BO_ 2561277694 "Forward Lane Image Command
Message containing commands, sent to the forward image controller";
CM_ SG_ 2561277694 LaneKeepingAssistEnableCmd "Command to enable/disable lane keeping assist system.

00b = Disable lane keeping assist
01b = Enable lane keeping assist
10b = Reserved
11b = Don?t care";
CM_ SG_ 2561277694 LaneCenteringEnableCmd "Command to enable/disable lane centering system.

00b = Disable lane centering
01b = Enable lane centering
10b = Reserved
11b = Don?t care";
CM_ SG_ 2561277694 LaneDepartureWarningEnableCmd "Command to enable/disable Lane Departure Indication

00   Disable Lane Departure Warning
01   Enable Lane Departure Warning
10   Reserved
11   Don´t care";
CM_ BO_ 2633861886 "SAE J2012 DTC Display
Conveys basic SAE J2012 DTC information for on-board or service tool displays.
If PGN 64906 is requested and a supporting device has no active or inactive J2012 DTCs, PGN 64906 shall be sent with the first data byte ( Number ...";
CM_ SG_ 2633861886 J2012DTCOccurrenceCount "Number of occurrences of the respective SAE J2012 DTC being conveyed.
If more than 126 occurrences happen the value shall be set to 126.
If the occurrence count is not available to be sent then this value shall be set to 127.";
CM_ SG_ 2633861886 J2012DTCStatus "Indicates if the respective SAE J2012 DTC is active or previously active.

0 - DTC is previously active
1 - DTC is active";
CM_ SG_ 2633861886 J2012DTC "Five character ASCII SAE J2012 DTC, sent most significant byte first.";
CM_ SG_ 2633861886 NumberOfJ2012DTCs "The number J2012 DTCs being conveyed in PGN 64906.  If the value of this parameter is zero, the device broadcasting PGN 64906 has no active or previously active J2012 DTCs.";
CM_ BO_ 2565873150 "Steering Angle Sensor Information
Contains information which relates to a steering angle sensor.";
CM_ SG_ 2565873150 MessageChecksum "The message checksum is used to verify the signal path from the demanding device to the steering controller.  The support of this parameter is mandatory if PGN 61469 is supported as there is no means to indicate 'not available'.
The 4 bit checksum ...";
CM_ SG_ 2565873150 MessageCounter "The message counter is to verify the signal path from the demanding device to the steering controller.  The support of this parameter is mandatory.
Note:  The initial value of the 4 bit message counter for the first message during a driving cycle ...";
CM_ SG_ 2565873150 SteerAngleSensorCalibrated "This signal indicates the calibration status of the steering angle sensor.

00 - SAS not calibrated
01 - SAS calibrated
10 - Reserved
11 - Not available";
CM_ SG_ 2565873150 SteerAngleSensorActiveMode "This signal indicates the operational mode of the steering angle sensor.

00 - Programming mode active
01 - Normal mode active
10 - Reserved
11 - Not available";
CM_ SG_ 2565873150 SteerWheelAngleRange "The signal indicates the range of  the steering wheel angle the sensor element is capable to measure. The steering wheel angle signal ranges between the negative and the positive value of the steering wheel angle range.
For example, a steering ...";
CM_ SG_ 2565873150 SteerWheelAngleRangeCounterType "The signal indicates whether the steering wheel angle sensor is capable of absolute measuring of the number of steering wheel angle ranges or not.  Absolute measuring means that the steering wheel angle range counter signal indicates the real ...";
CM_ SG_ 2565873150 SteerWheelAngleRangeCounter "The signal indicates the number of steering wheel angle range overflows if the operating range of steering wheel is greater than the measuring range of sensor element. Positive values indicate left turns (counterclockwise). If the steering wheel ...";
CM_ SG_ 2565873150 SteerWheelAngle "The main operator`s steering wheel angle (on the steering column, not the actual wheel angle). The vehicle being steered to the left (counterclockwise) results in a positive steering wheel angle.  This is the yaw angle of the steering wheel with the ...";
CM_ BO_ 2566745854 "Aftertreatment 1 SCR Service Information 1
This message contains SCR service information for aftertreatment system 1 (or bank 1).";
CM_ SG_ 2566745854 SysSulfationLvl "Indicates the sulfur level in the SCR system for aftertreatment 1.
.
100% level could be the regeneration trigger level (and if conditions are not favorable for regeneration, sulfation loading can continue beyond 100%). During normal operation and ...";
CM_ SG_ 2566745854 SCROpIndActiveTraveledDist "The distance traveled while SCR inducement (SPN 5246 is equal to level 1 to 5) is active.  Distance is reset once inducement is no longer active for SCR (SPN 5246 = 0).
Emission Control System Operator Inducement Severity, SPN 5826, may be active ...";
CM_ SG_ 2566745854 ConversionEfficiency "The SCR conversion efficiency percentage.  Calculated as 100 times the catalyst intake NOx minus the catalyst outlet NOx divided by the catalyst intake NOx.  The catalyst conversion efficiency number in itself does not imply emissions compliance or ...";
CM_ SG_ 2566745854 CommandedDEFConsumption "This parameter transmits the amount of diesel exhaust fluid that the emissions control system has requested to be used, averaged over the past 15 hours of engine operation.
Used to determine whether the SCR system is using an appropriate amount of ...";
CM_ SG_ 2566745854 DEFAvgConsumption "Measured use of diesel exhaust fluid by a Selective Catalytic Reduction system for exhaust emission control, averaged over the previous 15 hours of engine operation.
Used to determine whether the SCR system is using an appropriate amount of diesel ...";
CM_ BO_ 2566751230 "Transfer Case Information
Transfer Case Information";
CM_ SG_ 2566751230 TransferCaseStatus "This parameter describes the feedback from the  transfer case controller . Used by instrument clusters,  tachographs, PTOs , etc.
000 2 wheel high (normal or `'On Highway' Range)
001 4 wheel high (normal or  'On Highway' Range
010 neutral
011 2 ...";
CM_ BO_ 2566755838 "Transmission Fluids 2";
CM_ SG_ 2566755838 TransOilLevel2MeasurementStatus "Measurement status for the second instance of a transmission oil level indicator. Indicates if conditions are acceptable to obtain a valid transmission oil level measurement as conveyed in SPN 5914 Transmission Oil Level 2 High / Low. If conditions ...";
CM_ SG_ 2566755838 TransOilLevel2CountdownTimer "Countdown timer for the second instance of a transmission oil level indicator. Once all vehicle conditions (such as vehicle stopped, etc) are met, some transmissions may require a ‘settling time' to allow the fluid level to normalize. This parameter ...";
CM_ SG_ 2566755838 TransOilLevel2High_Low "Second instance of a transmission oil level indicator. Conveys the current volume of transmission sump oil compared to recommended volume. Positive values indicate overfill. Zero means the transmission fluid is filled to the recommended level. If ...";
CM_ SG_ 2566755838 TransOilTemp2 "Second instance of transmission lubricant temperature. This parameter may reflect the temperature of a second sump or oil supply. If only one instance of transmission lubricant temperature measurement exists, SPN 177 Transmission Oil Temperature 1 ...";
CM_ SG_ 2566755838 TransOilLifeRemaining "Signal which indicates the actual oil life remaining in percent.  100% means the transmission oil is brand new, and 0% means the transmission oil is at the end of its life.";
CM_ SG_ 2566755838 TrnsTorqueConverterOilOutletTemp "Temperature of transmission torque converter outlet oil.";
CM_ SG_ 2566755838 TransOverheatIndicator "Signal from transmission indicating that its fluid temperature is above normal acceptable limits, and as a result, transmission operation may be altered or restricted.  The indicator is typically a lamp.  Distinctions in meaning between the ...";
CM_ SG_ 2566755838 TransOilLevelSwitch "This switch indicates whether transmission oil level is full or empty.

00 - Empty
01 - Full or not empty
10 - Error
11 - Not available";
CM_ SG_ 2566755838 TransOilFilterRestrictionSwitch "This switch indicates whether the transmission oil filter is clogged.

00 - No restriction
01 - Restriction exists on oil filter
10 - Error
11 - Not available";
CM_ BO_ 2566752766 "Vehicle Direction/Speed 2
Vehicle Direction/Speed 2 PGN contains the vehicle roll data.";
CM_ SG_ 2566752766 VehicleRoll "This parameter indicates the roll in degrees from level.  Facing the direction of travel a tip to the left would be indicated by a negative number and a tip to the right would be indicated by a positive number.";
CM_ BO_ 2633938942 "Engine Speed/Load Factor Information";
CM_ SG_ 2633938942 TotalEngCruiseTime "Total time that the engine has operated in the cruise hold state, excluding time in accelerator override, over the life of the engine.";
CM_ SG_ 2633938942 TotalDriveAverageLoadFactor "Average engine load factor while engine speed is greater than zero, vehicle speed is greater than or equal to 2 km/h, and both the PTO (moving/non-moving) and remote PTO governors are not in the hold state, over the life of the engine.  Engine ...";
CM_ SG_ 2633938942 TripDriveAverageLoadFactor "Average engine load factor while engine speed is greater than zero, vehicle speed is greater than or equal to 2 km/h, and both the PTO (moving/non-moving) and remote PTO governors are not in the hold state, since the last trip reset.  Engine ...";
CM_ SG_ 2633938942 TripAverageEngSpeed "Average speed of the engine since the last trip reset.

NOTE - Excludes ignition-on time without the engine speed above zero.  Includes idle, engine PTO governor (moving and non-moving), and drive operation.";
CM_ SG_ 2633938942 TripMaxEngSpeed "Maximum engine speed achieved since the last trip reset.";
CM_ BO_ 2566799614 "Lighting Data
This lighting message is a response to the request for lighting data in the lighting command message.  Each lighting controller on the tractor and attached implements must transmit this message to the Tractor ECU when requested.  The ...";
CM_ SG_ 2566799614 ImplementRearWorkLight "This parameter provides measured data from the implement rear work lamps.

00 De-activated
01 Activated
10 Fault Detected
11 Not Available";
CM_ SG_ 2566799614 ImplLeftFacingWorkLight "This parameter provides measured data from the left facing work lights toward the left end of the implement.

00 De-activated
01 Activated
10 Fault Detected
11 Not Available";
CM_ SG_ 2566799614 ImplRightForwardWorkLight "This parameter provides measured data from the forward facing work lights toward the right end of the implement.

00 De-activated
01 Activated
10 Fault Detected
11 Not Available";
CM_ SG_ 2566799614 ImplLeftForwardWorkLight "This parameter provides measured data from the work lights mounted on an implement to illuminate the forward left end of the implement.

00 De-activate
01 Activate
10 Fault Detected
11 Not Available";
CM_ SG_ 2566799614 ImplRightFacingWorkLight "This parameter provides measured data from the work lights mounted on an implement to illuminate beyond right end of the implement.

00 De-activated
01 Activated
10 Fault Detected
11 Not Available";
CM_ SG_ 2566799614 ImplementOEMOption1Light "This parameter provides measured data from the implement OEM option 1 light.

00 De-activated
01 Activated
10 Fault Detected
11 Not Available";
CM_ SG_ 2566799614 ImplementOEMOption2Light "This parameter provides measured data from the implement OEM option 2 light.

00 De-activated
01 Activated
10 Fault Detected
11 Not Available";
CM_ SG_ 2566799614 TrctorFrontHighMdWkLights "This parameter provides measured data from the tractor front high mounted work lights. 

00 De-activated
01 Activated
10 Fault Detected
11 Not Available";
CM_ SG_ 2566799614 TractorFrontLowMdWkLights "This parameter provides measured data from the tractor front low mounted work lights. 

00 De-activated
01 Activated
10 Fault Detected
11 Not Available";
CM_ SG_ 2566799614 TractorSideHighMdWkLights "This parameter provides measured data from the tractor side high mounted work lights. 

00 De-activated
01 Activated
10 Fault Detected
11 Not Available";
CM_ SG_ 2566799614 TractorSideLowMdWkLights "This parameter provides measured data from the tractor side low mounted work lights. 

00 De-activated
01 Activated
10 Fault Detected
11 Not Available";
CM_ SG_ 2566799614 TractorRearHighMdWkLights "This parameter provides measured data from the tractor rear high mounted work lights. 

00 De-activated
01 Activated
10 Fault Detected
11 Not Available";
CM_ SG_ 2566799614 TractorRearLowMdWkLights "This parameter provides measured data from the tractor rear low mounted work lights.

00 De-activated
01 Activated
10 Fault Detected
11 Not Available";
CM_ SG_ 2566799614 TrctorUndersideMdWkLights "This parameter provides measured data from the tractor underside mounted work lights. 

00 De-activated
01 Activated
10 Fault Detected
11 Not Available";
CM_ SG_ 2566799614 RearFogLights "This parameter provides measured data from the tractor and/or implement rear fog lights.

00 De-activated
01 Activated
10 Fault Detected
11 Not Available";
CM_ SG_ 2566799614 TractorMarkerLight "This parameter provides measured data from the tractor and attached implement marker lights, including front position lights, rear tail lights, side running lights, license plate lights and instruments and switch back lights.
00 De-activated
01 ...";
CM_ SG_ 2566799614 ImplementMarkerLight "This parameter provides measured data from an attached implement marker lights, including front position lights, rear tail lights, side running lights, license plate lights and instruments and switch back lights.
00 De-activated
01 Activated
10 ...";
CM_ SG_ 2566799614 TractorClearanceLight "This parameter provides measured data from the tractor high mounted clearance and center ID lights.

00 De-activated
01 Activated
10 Fault Detected
11 Not Available";
CM_ SG_ 2566799614 ImplementClearanceLight "This parameter provides measured data from an attached implement high mounted clearance lights.

00 De-activated
01 Activated
10 Fault Detected
11 Not Available";
CM_ SG_ 2566799614 LeftStopLight "This parameter provides measured data from the tractor and attached implement left stop lights.

00 De-activated
01 Activated
10 Fault Detected
11 Not Available";
CM_ SG_ 2566799614 RightStopLight "This parameter provides measured data from the tractor and attached implement right stop lights.

00 De-activated
01 Activated
10 Fault Detected
11 Not Available";
CM_ SG_ 2566799614 CenterStopLight "This parameter provides measured data from the tractor and attached implement center stop lights.

00 De-activated
01 Activated
10 Fault Detected
11 Not Available";
CM_ SG_ 2566799614 BackUpLightAndAlarmHorn "This parameter provides measured data from the back up lights and/ or associated alarm.

00 De-activated
01 Activated
10 Fault Detected
11 Not Available";
CM_ SG_ 2566799614 LeftTurnSignalLights "This parameter provides measured data from the tractor and attached implement left turn signal lights.

00 De-activated
01 Activated
10 Fault Detected
11 Not Available";
CM_ SG_ 2566799614 RightTurnSignalLights "This parameter provides measured data from the tractor and attached implement right turn signal lights.

00 De-activated
01 Activated
10 Fault Detected
11 Not Available";
CM_ SG_ 2566799614 RotatingBeaconLight "This parameter provides measured data from the beacon light on tractor or attached implements.

00 De-activated
01 Activated
10 Fault Detected
11 Not Available";
CM_ SG_ 2566799614 TractorFrontFogLights "This parameter provides measured data from the tractor front fog lights.

00 De-activated
01 Activated
10 Fault Detected
11 Not Available";
CM_ SG_ 2566799614 HighBeamHeadLight "This parameter provides measured data from the tractor high beam head light lamps. 

00 De-activated
01 Activated
10 Fault Detected
11 Not Available";
CM_ SG_ 2566799614 LowBeamHeadLight "This parameter provides measured data from the tractor low beam head light lamps. 

00 De-activated
01 Activated
10 Fault Detected
11 Not Available";
CM_ SG_ 2566799614 AltBeamHeadLight "This parameter provides measured data from the tractor alternate beam head light lamps. 

00 De-activated
01 Activated
10 Fault Detected
11 Not Available";
CM_ SG_ 2566799614 RunningLight "This parameter provides measured data from the vehicle's running lights.

00 De-activated
01 Activated
10 Fault Detected
11 Not Available";
CM_ BO_ 2365473278 "Lighting Command
The lighting command message has been defined as a global message from the tractor to all lighting controllers on the tractor and attached implements.  Separate messages are provided for tractor and implement work and driving ...";
CM_ SG_ 2365473278 ImplementRearWorkLightCmd "Command to activate or de-activate implement rear work lights.  (This is also the same as Reversing Lights for truck applications.)  

00 De-activate
01 Activate
10 Reserved
11 Don't Care";
CM_ SG_ 2365473278 ImplLeftFacingWorkLightCmd "Command to activate or de-activate the left facing work lights toward the left end of the implement.

00 De-activate
01 Activate
10 Reserved
11 Don't Care";
CM_ SG_ 2365473278 ImplRightFwdWorkLightCmd "Command to activate or de-activate the forward facing work lights toward the right end of the implement.

00 De-activate
01 Activate
10 Reserved
11 Don't Care";
CM_ SG_ 2365473278 LightingDataRqCmd "Command to provide a response of the light state

00 De-activate
01 Activate
10 Reserved
11 Don't Care";
CM_ SG_ 2365473278 ImplLeftForwardWorkLightCmd "Command to activate or de-activate work lights mounted on an implement to illuminate beyond left end of the implement.

00 De-activate
01 Activate
10 Reserved
11 Don't Care";
CM_ SG_ 2365473278 ImplRightFacingWorkLightCmd "Command to activate or de-activate work lights mounted on an implement to illuminate beyond right end of the implement.

00 De-activate
01 Activate
10 Reserved
11 Don't Care";
CM_ SG_ 2365473278 ImplOEMOption1LightCmd "Command to activate or de-activate an implement OEM option 1 light.  This is provided to meet special needs on implements, such as tank inspection or filling lights.

00 De-activate
01 Activate
10 Reserved
11 Don't Care";
CM_ SG_ 2365473278 ImplOEMOption2LightCmd "Command to activate or de-activate an implement OEM option 2 light.  This is provided to meet special needs on implements, such as tank inspection or filling lights.

00 De-activate
01 Activate
10 Reserved
11 Don't Care";
CM_ SG_ 2365473278 TrctrFrntHghMdWkLightsCmd "Command to activate or de-activate the tractor front high mounted work lights.

00 De-activate
01 Activate
10 Reserved
11 Don't Care";
CM_ SG_ 2365473278 TrctrFrntLowMdWkLightsCmd "Command to activate or de-activate the tractor front low mounted work lights.

00 De-activate
01 Activate
10 Reserved
11 Don't Care";
CM_ SG_ 2365473278 TrctrSdeHighMdWkLightsCmd "Command to activate or de-activate the tractor side high mounted work lights.

00 De-activate
01 Activate
10 Reserved
11 Don't Care";
CM_ SG_ 2365473278 TrctrSideLowMdWkLightsCmd "Command to activate or de-activate the tractor side low mounted work lights.

00 De-activate
01 Activate
10 Reserved
11 Don't Care";
CM_ SG_ 2365473278 TrctrRarHighMdWkLightsCmd "Command to activate or de-activate the tractor rear high  mounted work lights.

00 De-activate
01 Activate
10 Reserved
11 Don't Care";
CM_ SG_ 2365473278 TrctrRearLowMdWkLightsCmd "Command to activate or de-activate the tractor rear low  mounted work lights.

00 De-activate
01 Activate
10 Reserved
11 Don't Care";
CM_ SG_ 2365473278 TrctrUndrsdeMdWkLightsCmd "Command to activate or de-activate the tractor underside mounted work lights.

00 De-activate
01 Activate
10 Reserved
11 Don't Care";
CM_ SG_ 2365473278 RearFogLightsCmd "Command to activate or de-activate tractor or implement rear fog lights.  

00 De-activate
01 Activate
10 Reserved
11 Don't Care";
CM_ SG_ 2365473278 TractorMarkerLightCmd "Command to activate or de-activate tractor and implement front position lights, rear red tail lights, side amber running lights, license plate lights and instrument and switch back lights.  

00 De-activate
01 Activate
10 Reserved
11 Don't Care";
CM_ SG_ 2365473278 ImplementMarkerLightCmd "Command to activate or de-activate implement front position lights, rear red tail lights, side amber running lights, license plate lights and instrument and switch back lights.  

00 De-activate
01 Activate
10 Reserved
11 Don't Care";
CM_ SG_ 2365473278 TractorClearanceLightCmd "Command to activate or de-activate the tractor high mounted clearance and center ID lights

00 De-activate
01 Activate
10 Reserved
11 Don't Care";
CM_ SG_ 2365473278 ImplementClearanceLightCmd "Command to activate or de-activate the implement high mounted clearance and lights.  

00 De-activate
01 Activate
10 Reserved
11 Don't Care";
CM_ SG_ 2365473278 LeftStopLightCmd "Command to activate or de-activate the tractor and implement left stop lights

00 De-activate
01 Activate
10 Reserved
11 Don't Care";
CM_ SG_ 2365473278 RightStopLightCmd "Command to activate or de-activate the tractor and implement right stop light

00 De-activate
01 Activate
10 Reserved
11 Don't Care";
CM_ SG_ 2365473278 CenterStopLightCmd "Command to activate or de-activate the tractor and implement center stop light

00 De-activate
01 Activate
10 Reserved
11 Don't Care";
CM_ SG_ 2365473278 BackUpLightAndAlarmHornCmd "Command to activate or de-activate the back up lights and/ or associated alarm if required

00 De-activate
01 Activate
10 Reserved
11 Don't Care";
CM_ SG_ 2365473278 LeftTurnSignalLightsCmd "Command to activate or de-activate left turn signal lights on the tractor and all connected implements

00 De-activate
01 Activate
10 Reserved
11 Don't Care";
CM_ SG_ 2365473278 RightTurnSignalLightsCmd "Command to activate or de-activate right turn signal lights on the tractor and all connected implements

00 De-activate
01 Activate
10 Reserved
11 Don't Care";
CM_ SG_ 2365473278 RotatingBeaconLightCmd "Command to activate or de-activate slow moving vehicle indicator lights on tractor and/or implements.  Activation of the slow moving vehicle lights implies that the controller should manipulate the lighting as appropriate to provide the slow moving ...";
CM_ SG_ 2365473278 TractorFrontFogLightsCmd "Command to activate or de-activate tractor front fog lights.

00 De-activate
01 Activate
10 Reserved
11 Don't Care";
CM_ SG_ 2365473278 HighBeamHeadLightCmd "Command to activate or de-activate the tractor high beam head light lamps. 

00 De-activate
01 Activate
10 Reserved
11 Don't Care";
CM_ SG_ 2365473278 LowBeamHeadLightCmd "Command to activate or de-activate the tractor low beam head light lamps. 

00 De-activate
01 Activate
10 Reserved
11 Don't Care";
CM_ SG_ 2365473278 AltBeamHeadLightCmd "Command to activate or de-activate the tractor alternate head lights (only low beam is available on alternate head lights).  The alternate position lights are intended for use with loader and snow plows that tend to block the primary head lights.
 ...";
CM_ SG_ 2365473278 RunningLightCmd "Command to activate or de-activate the tractor or powered vehicle running lights.  Usually only used for on road vehicles.

00 De-activate
01 Activate
10 Reserved
11 Don't Care";
CM_ BO_ 2365485822 "Laser Leveling System Blade Control";
CM_ SG_ 2365485822 LandLevelingSystemEnableStatus "Communicate the enable/disable status of the Land Leveling System.

00 = Disabled
01= Enabled
10 = Error
11 = Not available / Not installed";
CM_ SG_ 2365485822 BladeCtrlModeRight "Indicate if the land leveling system's automatic control is active or inactive for the elevation sensor on the right side of the blade.  The 'left' notation is applicable to grading machines such tractors and motor graders where 'right' is the ...";
CM_ SG_ 2365485822 BladeCtrlModeLeft "Indicate if the land leveling system's automatic control is active or inactive for the elevation sensor on the left side of the blade.  The 'left' notation is applicable to grading machines such tractors and motor graders where 'left' is the ...";
CM_ SG_ 2365485822 BladeCtrlMode "Allows the user to select the type of blade control for the land leveling system.  

00000000 Manual mode
00000001 Automatic mode
00000010 Inactive automatic mode
All other values Reserved";
CM_ SG_ 2365485822 BladeDurationAndDirection "Used to indicate the duration and direction that the land leveling system blade moves.";
CM_ BO_ 2633926654 "Ignition Timing 6";
CM_ SG_ 2633926654 EngActualIgntTiming "The actual ignition timing at the current engine conditions. This parameter may or may not be equal to one of the desired timing parameters (see SPNs 1433-1435), depending on the status of the engine. Positive values indicate an increasingly ...";
CM_ SG_ 2633926654 EngDesiredIgntTiming3 "A programmable timing value specific to the engine's application. Factors affecting this value include both fuel type and the nature of the load being driven. Positive values indicate an increasingly advanced timing from TDC.";
CM_ SG_ 2633926654 EngDesiredIgntTiming2 "A programmable timing value specific to the engine's application. Factors affecting this value include both fuel type and the nature of the load being driven. Positive values indicate an increasingly advanced timing from TDC.";
CM_ SG_ 2633926654 EngDesiredIgntTiming1 "A programmable timing value specific to the engine's application. Factors affecting this value include both fuel type and the nature of the load being driven. Positive values indicate an increasingly advanced timing from TDC.";
CM_ BO_ 2633926398 "Ignition Timing 5";
CM_ SG_ 2633926398 EngCyl20IgntTiming "The ignition timing (SI engines) or main fuel injection timing (CI engines) of the cylinder. Positive values indicate an increasingly advanced timing from TDC.";
CM_ SG_ 2633926398 EngCyl19IgntTiming "The ignition timing (SI engines) or main fuel injection timing (CI engines) of the cylinder. Positive values indicate an increasingly advanced timing from TDC.";
CM_ SG_ 2633926398 EngCyl18IgntTiming "The ignition timing (SI engines) or main fuel injection timing (CI engines) of the cylinder. Positive values indicate an increasingly advanced timing from TDC.";
CM_ SG_ 2633926398 EngCyl17IgntTiming "The ignition timing (SI engines) or main fuel injection timing (CI engines) of the cylinder. Positive values indicate an increasingly advanced timing from TDC.";
CM_ BO_ 2633926142 "Ignition Timing 4";
CM_ SG_ 2633926142 EngCyl16IgntTiming "The ignition timing (SI engines) or main fuel injection timing (CI engines) of the cylinder. Positive values indicate an increasingly advanced timing from TDC.";
CM_ SG_ 2633926142 EngCyl15IgntTiming "The ignition timing (SI engines) or main fuel injection timing (CI engines) of the cylinder. Positive values indicate an increasingly advanced timing from TDC.";
CM_ SG_ 2633926142 EngCyl14IgntTiming "The ignition timing (SI engines) or main fuel injection timing (CI engines) of the cylinder. Positive values indicate an increasingly advanced timing from TDC.";
CM_ SG_ 2633926142 EngCyl13IgntTiming "The ignition timing (SI engines) or main fuel injection timing (CI engines) of the cylinder. Positive values indicate an increasingly advanced timing from TDC.";
CM_ BO_ 2633925886 "Ignition Timing 3";
CM_ SG_ 2633925886 EngCyl12IgntTiming "The ignition timing (SI engines) or main fuel injection timing (CI engines) of the cylinder. Positive values indicate an increasingly advanced timing from TDC.";
CM_ SG_ 2633925886 EngCyl11IgntTiming "The ignition timing (SI engines) or main fuel injection timing (CI engines) of the cylinder. Positive values indicate an increasingly advanced timing from TDC.";
CM_ SG_ 2633925886 EngCyl10IgntTiming "The ignition timing (SI engines) or main fuel injection timing (CI engines) of the cylinder. Positive values indicate an increasingly advanced timing from TDC.";
CM_ SG_ 2633925886 EngCyl9IgntTiming "The ignition timing (SI engines) or main fuel injection timing (CI engines) of the cylinder. Positive values indicate an increasingly advanced timing from TDC.";
CM_ BO_ 2633925630 "Ignition Timing 2";
CM_ SG_ 2633925630 EngCyl8IgntTiming "The ignition timing (SI engines) or main fuel injection timing (CI engines) of the cylinder. Positive values indicate an increasingly advanced timing from TDC.";
CM_ SG_ 2633925630 EngCyl7IgntTiming "The ignition timing (SI engines) or main fuel injection timing (CI engines) of the cylinder. Positive values indicate an increasingly advanced timing from TDC.";
CM_ SG_ 2633925630 EngCyl6IgntTiming "The ignition timing (SI engines) or main fuel injection timing (CI engines) of the cylinder. Positive values indicate an increasingly advanced timing from TDC.";
CM_ SG_ 2633925630 EngCyl5IgntTiming "The ignition timing (SI engines) or main fuel injection timing (CI engines) of the cylinder. Positive values indicate an increasingly advanced timing from TDC.";
CM_ BO_ 2633925374 "Ignition Timing 1";
CM_ SG_ 2633925374 EngCyl4IgntTiming "The ignition timing (SI engines) or main fuel injection timing (CI engines) of the cylinder. Positive values indicate an increasingly advanced timing from TDC.";
CM_ SG_ 2633925374 EngCyl3IgntTiming "The ignition timing (SI engines) or main fuel injection timing (CI engines) of the cylinder. Positive values indicate an increasingly advanced timing from TDC.";
CM_ SG_ 2633925374 EngCyl2IgntTiming "The ignition timing (SI engines) or main fuel injection timing (CI engines) of the cylinder. Positive values indicate an increasingly advanced timing from TDC.";
CM_ SG_ 2633925374 EngCyl1IgntTiming "The ignition timing (SI engines) or main fuel injection timing (CI engines) of the cylinder. Positive values indicate an increasingly advanced timing from TDC.";
CM_ BO_ 2633927422 "Ignition Transformer Secondary Output 3";
CM_ SG_ 2633927422 EngCyl20IgntTransSecondOutput "This parameter indicates the relative intensity of the secondary output voltage of the ignition transformer.";
CM_ SG_ 2633927422 EngCyl19IgntTransSecondOutput "This parameter indicates the relative intensity of the secondary output voltage of the ignition transformer.";
CM_ SG_ 2633927422 EngCyl18IgntTransSecondOutput "This parameter indicates the relative intensity of the secondary output voltage of the ignition transformer.";
CM_ SG_ 2633927422 EngCyl17IgntTransSecondOutput "This parameter indicates the relative intensity of the secondary output voltage of the ignition transformer.";
CM_ BO_ 2633927166 "Ignition Transformer Secondary Output 2";
CM_ SG_ 2633927166 EngCyl16IgntTransSecondOutput "This parameter indicates the relative intensity of the secondary output voltage of the ignition transformer.";
CM_ SG_ 2633927166 EngCyl15IgntTransSecondOutput "This parameter indicates the relative intensity of the secondary output voltage of the ignition transformer.";
CM_ SG_ 2633927166 EngCyl14IgntTransSecondOutput "This parameter indicates the relative intensity of the secondary output voltage of the ignition transformer.";
CM_ SG_ 2633927166 EngCyl13IgntTransSecondOutput "This parameter indicates the relative intensity of the secondary output voltage of the ignition transformer.";
CM_ SG_ 2633927166 EngCyl12IgntTransSecondOutput "This parameter indicates the relative intensity of the secondary output voltage of the ignition transformer.";
CM_ SG_ 2633927166 EngCyl11IgntTransSecondOutput "This parameter indicates the relative intensity of the secondary output voltage of the ignition transformer.";
CM_ SG_ 2633927166 EngCyl10IgntTransSecondOutput "This parameter indicates the relative intensity of the secondary output voltage of the ignition transformer.";
CM_ SG_ 2633927166 EngCyl9IgntTransSecondOutput "This parameter indicates the relative intensity of the secondary output voltage of the ignition transformer.";
CM_ BO_ 2633926910 "Ignition Transformer Secondary Output 1";
CM_ SG_ 2633926910 EngCyl8IgntTransSecondOutput "This parameter indicates the relative intensity of the secondary output voltage of the ignition transformer.";
CM_ SG_ 2633926910 EngCyl7IgntTransSecondOutput "This parameter indicates the relative intensity of the secondary output voltage of the ignition transformer.";
CM_ SG_ 2633926910 EngCyl6IgntTransSecondOutput "This parameter indicates the relative intensity of the secondary output voltage of the ignition transformer.";
CM_ SG_ 2633926910 EngCyl5IgntTransSecondOutput "This parameter indicates the relative intensity of the secondary output voltage of the ignition transformer.";
CM_ SG_ 2633926910 EngCyl4IgntTransSecondOutput "This parameter indicates the relative intensity of the secondary output voltage of the ignition transformer.";
CM_ SG_ 2633926910 EngCyl3IgntTransSecondOutput "This parameter indicates the relative intensity of the secondary output voltage of the ignition transformer.";
CM_ SG_ 2633926910 EngCyl2IgntTransSecondOutput "This parameter indicates the relative intensity of the secondary output voltage of the ignition transformer.";
CM_ SG_ 2633926910 EngCyl1IgntTransSecondOutput "This parameter indicates the relative intensity of the secondary output voltage of the ignition transformer.";
CM_ BO_ 2566768894 "Operator Primary Intermediate Speed Control state
The Operator Primary Intermediate Speed Control State is used to provide the controller feedback to indicate the controls state achieved.";
CM_ SG_ 2566768894 EngOprtrPrmryIntrmdtSpdSlctState "13 preprogrammed intermediate speed control settings are available for the controlling ECM to select.  If no speed setting is requested, the engine operates normally. The Intermediate Speed Control is widely used in the Industrial application to ...";
CM_ BO_ 2566769406 "Intermediate Speed Control
The Intermediate Speed Control is widely used in the Industrial application to control the engine to an intermediate speed setting which can bypass the accelerator position control. An example of this operation would be ...";
CM_ SG_ 2566769406 EngOprtrPrmryIntrmdteSpeedSelect "Allows the operator to select one of 13 preprogrammed Intermediate Speed Control settings. If no speed setting is requested, the engine operates normally. The Intermediate Speed Control is widely used in the Industrial application to control the ...";
CM_ BO_ 2566839550 "Idle Operation";
CM_ SG_ 2566839550 EngTotalIdleHours "Accumulated time of operation of the engine while under idle conditions.";
CM_ SG_ 2566839550 EngTotalIdleFuelUsed "Accumulated amount of fuel used during vehicle operation while under idle conditions.";
CM_ BO_ 2633934334 "Intake Manifold Information 2";
CM_ SG_ 2633934334 EngIntakeManifold6Temp "Temperature of pre-combustion air found in intake manifold  number 6 of engine air supply system.";
CM_ SG_ 2633934334 EngIntakeManifold5Temp "Temperature of pre-combustion air found in intake manifold number 5 of engine air supply system.";
CM_ SG_ 2633934334 EngIntakeManifold4Temp "Temperature of pre-combustion air found in intake manifold of engine air supply system.";
CM_ SG_ 2633934334 EngIntakeManifold3Temp "Temperature of pre-combustion air found in intake manifold of engine air supply system.";
CM_ SG_ 2633934334 EngIntakeManifold2Temp "Temperature of pre-combustion air found in intake manifold of engine air supply system.";
CM_ BO_ 2566825726 "Intake Manifold Information 1";
CM_ SG_ 2566825726 EngTurbo4BoostPress "Gage pressure of air measured downstream of the compressor discharge side of the turbocharger.  See also SPN 102 for alternate range and resolution. If there is only one boost pressure to report and the range and resolution in SPN 102 is adequate, ...";
CM_ SG_ 2566825726 EngTurbo3BoostPress "Gage pressure of air measured downstream of the compressor discharge side of the turbocharger.  See also SPN 102 for alternate range and resolution. If there is only one boost pressure to report and the range and resolution in SPN 102 is adequate, ...";
CM_ SG_ 2566825726 EngTurbo2BoostPress "Gage pressure of air measured downstream of the compressor discharge side of the turbocharger.  See also SPN 102 for alternate range and resolution. If there is only one boost pressure to report and the range and resolution in SPN 102  is adequate, ...";
CM_ SG_ 2566825726 EngTurbo1BoostPress "Gage pressure of air measured downstream of the compressor discharge side of the turbocharger.  See also SPN 102 for alternate range and resolution. If there is only one boost pressure to report and the range and resolution in SPN 102 is adequate, ...";
CM_ BO_ 2566770942 "Intake/Exhaust Conditions 2
Intake/Exhaust Conditions 2 is a second PGN conveying this type of engine information. Also see PGN 65270.";
CM_ SG_ 2566770942 EngIntakeManifold2AbsPress "The absolute pressure measurement of the air intake manifold for bank 2 or the second air intake manifold. If there are multiple air pressure sensors in the intake stream, this is the last one in flow direction before entering the combustion ...";
CM_ SG_ 2566770942 EngIntakeManifold1AbsPress4817 "The absolute pressure measurement of the air intake manifold. If there are multiple air pressure sensors in the intake stream, this is the last one in flow direction before entering the combustion chamber.  This SPN is a high resolution measurement ...";
CM_ SG_ 2566770942 EngIntakeManifold1AbsPress "The absolute pressure measurement of the air intake manifold. If there are multiple air pressure sensors in the intake stream, this is the last one in flow direction before entering the combustion chamber.";
CM_ SG_ 2566770942 EngIntakeManifold2Press "The gage pressure measurement of the air intake manifold for bank #2 or the second air intake manifold. If there are multiple air pressure sensors in the second intake stream, this is the last one in flow direction before entering the combustion ...";
CM_ SG_ 2566770942 EngAirFilter4DiffPress "Change in engine air system pressure, measured across the fourth air filter, due to the filter and any accumulation of solid foreign matter on or in the filter.
This is for monitoring the air filter on the intake to the fourth turbocharger. Filter ...";
CM_ SG_ 2566770942 EngAirFilter3DiffPress "Change in engine air system pressure, measured across the third air filter, due to the filter and any accumulation of solid foreign matter on or in the filter.
This is for monitoring the air filter on the intake to the third turbocharger. Filter ...";
CM_ SG_ 2566770942 EngAirFilter2DiffPress "Change in engine air system pressure, measured across the second air filter, due to the filter and any accumulation of solid foreign matter on or in the filter.
This is for monitoring the air filter on the intake to the second turbocharger. Filter ...";
CM_ BO_ 2566846206 "Intake/Exhaust Conditions 1";
CM_ SG_ 2566846206 EngCoolantFilterDiffPress "Change in coolant pressure, measured across the filter, due to the filter and any accumulation of solid or semisolid matter on or in the filter.";
CM_ SG_ 2566846206 EngExhaustGasTemp "Temperature of combustion byproducts leaving the engine.  See SPNs 2433, 2434, 5969 and 5970 for engines with more than one exhaust temperature measurement.";
CM_ SG_ 2566846206 EngAirFilter1DiffPress "Change in engine air system pressure, measured across the filter, due to the filter and any accumulation of solid foreign matter on or in the filter.
This is the measurement of the first filter in a multiple air filter system.  In a single air ...";
CM_ SG_ 2566846206 EngAirIntakePress "Absolute air pressure at input port to intake manifold or air box.";
CM_ SG_ 2566846206 EngIntakeManifold1Temp "Temperature of pre-combustion air found in intake manifold of engine air supply system.";
CM_ SG_ 2566846206 EngIntakeManifold1Press "The gage pressure measurement of the air intake manifold. If there are multiple air pressure sensors in the intake stream, this is the last one in flow direction before entering the combustion chamber.  This should be the pressure used to drive ...";
CM_ SG_ 2566846206 AFT1DPFInPress "Exhaust pressure as a result of particle accumulation on filter media placed in the exhaust stream.  It is recommended that SPN 3609 be used as it has better resolution.";
CM_ BO_ 2566811134 "Heater Information";
CM_ SG_ 2566811134 ADRCompliantHeaterInstallation "Indicates that the heater is installed in an ADR compliant vehicle.
00 -  Heater installation is not ADR compliant
01 -  Heater installation is ADR compliant
10 -  Error
11 -  Not Available
Note:  ADR is a European agreement concerning the ...";
CM_ SG_ 2566811134 CabHeatingZone "Parameter indicating whether the cab zone is being heated.

00 Cab heating zone off
01 Cab heating zone on
10 Reserved
11 Not available";
CM_ SG_ 2566811134 EngHeatingZone "Parameter indicating whether the engine zone is being heated.

00 Engine heating zone off
01 Engine heating zone on
10 Reserved
11 Not available";
CM_ SG_ 2566811134 CabVentilation "Indicates whether the cab is being ventilated or not.

00 Cab not ventilated
01 Cab is ventilated
10 Reserved
11 Not available";
CM_ SG_ 2566811134 AuxHeaterWaterPumpStatus "Parameter indicating whether the auxiliary heater water pump is running

00 Water Pump is not running
01 Water Pump is  running
10 Reserved
11 Not available";
CM_ SG_ 2566811134 AuxHeaterMode "State of the auxiliary heater
0000 Heater not active
0001 Off due to ADR per European Regulations for Transport of hazardous materials
0010 Economy mode
0011 Normal mode
0100 Heater pump up-keep   (running the equipment in order to keep it in ...";
CM_ SG_ 2566811134 AuxHeaterOutputPowerPercent "Current auxiliary heater output power, relative to the auxiliary heater maximum output power.";
CM_ SG_ 2566811134 AuxHeaterInputAirTemp "Temperature of the input air in an auxiliary heater system.";
CM_ SG_ 2566811134 AuxHeaterOutputCoolantTemp "Temperature of the auxiliary heater output coolant (I.e. water in a water heater system.)";
CM_ BO_ 2298375934 "High Resolution Wheel Speed";
CM_ SG_ 2298375934 RearAxleRightWheelSpeed "High resolution measurement of the speed of the right wheel on the rear axle.";
CM_ SG_ 2298375934 RearAxleLeftWheelSpeed "High resolution measurement of the speed of the left wheel on the rear axle.";
CM_ SG_ 2298375934 FrontAxleRightWheelSpeed "High resolution measurement of the speed of the right wheel on the front axle.";
CM_ SG_ 2298375934 FrontAxleLeftWheelSpeed "High resolution measurement of the speed of the left wheel on the front axle.";
CM_ BO_ 2565867774 "Hydraulic Pressure Governor Info
Information to be used for a hydraulic pressure governing control system";
CM_ SG_ 2565867774 FireApparatusPumpEngagement "The measured status of the pump used to provide water in fire fighting apparatus for distribution of water through water cannons or fire hoses.

00 Pump not engaged
01 Pump engaged
10 Error
11 Not available or not installed";
CM_ SG_ 2565867774 HydPressGovernorPresetSwitch "Switch that commands hydraulic pressure governor to increase or decrease engine rpm to achieve a predefined discharge pressure.

00 Preset Switch Inactive
01 Preset Switch Active
10 Error
11 Not available";
CM_ SG_ 2565867774 HydPressGovernorIncreaseSwitch "Switch that commands hydraulic pressure governor to increase engine rpm resulting in expected increase of hydraulic discharge pressure.

00 Increase Switch Inactive
01 Increase Switch Active
10 Error
11 Not available";
CM_ SG_ 2565867774 HydPressGovernorDecreaseSwitch "Switch that commands hydraulic pressure governor to decrease engine rpm resulting in expected decrease of hydraulic discharge pressure.

00 Decrease Switch Inactive
01 Decrease Switch Active
10 Error
11 Not available";
CM_ SG_ 2565867774 HydPressGovernorIdleSwitch "Switch that commands hydraulic pressure governor to decrease engine rpm to its idle position.

00 Idle Switch Inactive
01 Idle Switch Active
10 Error
11 Not available";
CM_ SG_ 2565867774 HydDischargePressSetPoint "Hydraulic pressure governing system discharge pressure set point.";
CM_ SG_ 2565867774 HydIntakePress "Hydraulic pressure measured at the intake of the hydraulic pump.";
CM_ SG_ 2565867774 FireApparatusOkayToPumpInterlock "The measured state of the Okay To Pump interlock of the fire apparatus.
00 Okay to Pump Interlock Inactive
01 Okay to Pump Interlock Active
10 Error
11 Not Available
Note: 'Okay to Pump' is incorporated into the NFPA 1901 Standard for Fire ...";
CM_ SG_ 2565867774 EngHydPressGovernorSwitch "Switch that sets the  mode of hydraulic governor

00 Pressure Mode Inactive
01 Pressure Mode Active
10 Error Indicator
11 Not Available";
CM_ SG_ 2565867774 EngHydPressGovernorModeIndicator "Mode for governor operation is hydraulic pressure control.

00 Disabled
01 Enabled
10 Error Indicator
11 Not Available";
CM_ SG_ 2565867774 HydPress "Hydraulic pressure measured at the output of the hydraulic pump.";
CM_ BO_ 2566841854 "Engine Hours, Revolutions";
CM_ SG_ 2566841854 EngTotalRevolutions "Accumulated number of revolutions of engine crankshaft during its operation.";
CM_ SG_ 2566841854 EngTotalHoursOfOperation "Accumulated time of operation of engine.";
CM_ BO_ 2365449982 "Hydraulic Braking System
Used for information on a hydraulic brake system
As an example: this PGN may be used for a two circuit hydraulic brake system with separate circuits for front and rear axle. The hydraulic energy is supplied via two ...";
CM_ SG_ 2365449982 HydBrakeFluidLevelSwitch "Signal which indicates whether the hydraulic fluid level in the reservoir(s) is sufficient.

00      Fluid level is not sufficient
01      Fluid level is sufficient
10      Error indicator
11      Not available";
CM_ SG_ 2365449982 HydBrakeSystemAudibleWarningCmd "Signal which commands an audible warning by the hydraulic braking system.

00       Audible warning off
01       Audible warning on
10       Reserved
11       Don't care";
CM_ SG_ 2365449982 HydBrakePressSupplyStateCircuit2 "Signal which indicates whether the hydraulic brake pressure supply of circuit 2 is reliable; that is, able to support continued braking.

00 Supply is not reliable
01 Supply is reliable
10 Error indicator
11 Not available";
CM_ SG_ 2365449982 HydBrakePressSupplyStateCircuit1 "Signal which indicates whether the hydraulic brake pressure supply of circuit 1 is reliable; that is, able to support continued braking.

00 Supply is not reliable
01 Supply is reliable
10 Error indicator
11 Not available";
CM_ SG_ 2365449982 HydBrkePressWarningStateCircuit2 "Signal which indicates whether the hydraulic brake pressure of circuit 2 is below the warning level

00 Pressure level sufficient
01 Pressure level below warning level
10 Error indicator
11 Not available";
CM_ SG_ 2365449982 HydBrkePressWarningStateCircuit1 "Signal which indicates whether the hydraulic brake pressure of circuit 1 is below the warning level

00 Pressure level sufficient
01 Pressure level below warning level
10 Error indicator
11 Not available";
CM_ SG_ 2365449982 HydBrakePressCircuit2 "Gage hydraulic pressure in circuit 2 of the hydraulic brake system";
CM_ SG_ 2365449982 HydBrakePressCircuit1 "Gage hydraulic pressure in circuit 1 of the hydraulic brake system";
CM_ BO_ 2633939198 "Trip Fuel Information (Gaseous)";
CM_ SG_ 2633939198 TripDriveFuelEconomy "Trip drive fuel economy is equal to the distance traveled by vehicle in the drive state (engine speed greater than zero, vehicle speed greater than or equal to 2 km/h, and neither the PTO or remote PTO governors are controlling engine power output) ...";
CM_ SG_ 2633939198 TripCruiseFuelUsed "Total fuel consumed while the engine is in the cruise hold state since the last trip reset.  If both cruise control and VSL (vehicle speed limiter) are commanding the same amount of fuel, the cruise control is deemed the active torque mode and fuel ...";
CM_ SG_ 2633939198 TripVehicleIdleFuelUsed "Total fuel consumed while neither the PTO or remote PTO governors are active, the engine speed is greater than zero, and vehicle speed is less than to 2 km/h, since the last trip reset.
NOTE-This parameter is intended for gaseous fueled engines ...";
CM_ SG_ 2633939198 TripPTOGovernorNonmovingFuelUsed "Total fuel consumed while the PTO or remote PTO governors are in the hold state, the engine speed is greater than zero, and vehicle speed is less than to 2 km/h, since the last trip reset.
NOTE-This parameter is intended for gaseous fueled engines ...";
CM_ SG_ 2633939198 TripPTOGovernorMovingFuelUsed "Total fuel consumed while the PTO or remote PTO governors are in the hold state, the engine speed is greater than zero, and vehicle speed is greater than or equal to 2 km/h, since the last trip reset.
NOTE-This parameter is intended for gaseous ...";
CM_ SG_ 2633939198 TripDriveFuelUsed "Total fuel consumed while the engine speed is greater than zero, vehicle speed is greater than or equal to 2 km/h, and neither the PTO or the remote PTO governors are controlling the engine power output, since the last trip reset.
NOTE-This ...";
CM_ BO_ 2633927678 "Gaseous Fuel Pressure";
CM_ SG_ 2633927678 EngFuelValve1OutletAbsPress "Absolute Pressure of gas on outlet side of the first or only fuel system control valve.  See SPN 3469 for the second fuel control valve.";
CM_ SG_ 2633927678 EngAirToFuelDiffPress "The differential pressure between the gaseous fuel and the air intake manifold.";
CM_ SG_ 2633927678 EngFuelValveDiffPress "The differential pressure between the intake and the outlet of the first or only gaseous fuel valve.";
CM_ SG_ 2633927678 EngFuelValve1IntakeAbsPress "The absolute pressure of gas on the intake side of the first system control valve.  See SPN 3466 for Engine Fuel Valve 2, 7505 for Engine Fuel Valve 3 & 7506 for Engine Fuel Valve 4.";
CM_ BO_ 2633925118 "Fuel Information 2 (Gaseous)
Gaseous fuel information 2";
CM_ SG_ 2633925118 EngRequestedFuelValve2Pos "The commanded position of the second fuel valve that is metering the fuel flow to the engine.";
CM_ SG_ 2633925118 EngRequestedFuelValve1Pos "The commanded position of the first fuel valve that is metering the fuel flow to the engine.";
CM_ SG_ 2633925118 EngFuelValve2Pos "The position of a gaseous fuel valve that is metering the fuel flow to the engine.  0% indicates no fuel flow through valve and 100% means maximum fuel flow through valve.";
CM_ SG_ 2633925118 EngFuelValve1Pos "The position of a gaseous fuel valve that is metering the fuel flow to the engine.  0% indicates no fuel flow through valve and 100% means maximum fuel flow through valve.";
CM_ SG_ 2633925118 EngFuelFlowRate2 "The rate at which the fuel is flowing through a fuel valve.";
CM_ SG_ 2633925118 EngFuelFlowRate1 "The rate at which the fuel is flowing through a fuel valve.";
CM_ BO_ 2633937662 "Fuel Information 1 (Gaseous)";
CM_ SG_ 2633937662 EngFuelSpecificGravity "This parameter conveys the specific gravity of the gaseous fuel being used by the engine.  The specific gravity of the fuel can then be used to compute the density of the fuel.";
CM_ SG_ 2633937662 TripAverageFuelRate "Average fuel rate, equal to trip fuel divided by trip time while the engine speed is above zero, since the last trip reset.  This includes idle, engine PTO governor (both moving and non-moving) and drive operation but excludes ignition-on time while ...";
CM_ SG_ 2633937662 TotalEngPTOGovernorFuelUsed "Total fuel used while the PTO or remote PTO governors are in the hold state and engine speed is above zero, over the life of the engine.

NOTE-This parameter is intended for gaseous fueled engines.  See SPN 1028 for alternate resolution.";
CM_ BO_ 2566804990 "Gaseous Fuel Properties";
CM_ SG_ 2566804990 FuelEnergyContent "Energy content (lower heating value) of the gaseous fuel.
Note:  For gaseous fuels, the fuel's energy content (lower heating value) is commonly defined in terms of energy / volume. The gas volume is defined for regular pressure and temperature ...";
CM_ SG_ 2566804990 ReferenceEngGasMassFlowRate "Configuration of the mass flow rate of gaseous fuel expected for 100% engine fuel valve control command.
Note:  The actuator will request this parameter from the ECU in order to determine what mass fuel flow to associate with a command of 100% from ...";
CM_ SG_ 2566804990 SpecificHeatRatio "The specific heat ratio of the fuel.";
CM_ BO_ 2633936894 "Fuel Consumption (Gaseous)";
CM_ SG_ 2633936894 TotalFuelUsed "Total fuel consumed (trip drive fuel + trip PTO governor moving fuel + trip PTO governor non-moving fuel + trip idle fuel) over the life of the engine.";
CM_ SG_ 2633936894 TripFuel "Total fuel consumed (trip drive fuel + trip PTO governor moving fuel + trip PTO governor non-moving fuel + trip idle fuel) since the last trip reset.";
CM_ BO_ 2566757630 "Sensor Electrical Power #2
Voltage supplies for sensors #2";
CM_ SG_ 2566757630 SensorSupplyVoltage8 "Sensor ECU supply voltage 8";
CM_ SG_ 2566757630 SensorSupplyVoltage7 "Sensor ECU supply voltage 7";
CM_ SG_ 2566757630 SensorSupplyVoltage6 "Sensor ECU supply voltage 6";
CM_ SG_ 2566757630 SensorSupplyVoltage5 "Sensor ECU supply voltage 5";
CM_ BO_ 2566757886 "Sensor Electrical Power #1
Voltage supplies for sensors #1";
CM_ SG_ 2566757886 SensorSupplyVoltage4 "Sensor ECU supply voltage 4";
CM_ SG_ 2566757886 SensorSupplyVoltage3 "Sensor ECU supply voltage 3";
CM_ SG_ 2566757886 SensorSupplyVoltage2 "Sensor ECU supply voltage 2";
CM_ SG_ 2566757886 SensorSupplyVoltage1 "Sensor ECU supply voltage 1";
CM_ BO_ 2566759678 "PTO Drive Engagement
Information relating to the request for engagement, consent for engagement, and status of engagement of various specific physical PTO drives.  This message may be broadcast by one or all controllers involved in the enabling of ...";
CM_ SG_ 2566759678 AtLeastOnePTOEngaged "Indicates that at least one PTO is engaged
00 No PTO drive is engaged
01 At least one PTO drive is engaged
10 Error
11 Not available
Note:  This parameter should only be sent by the controller that has knowledge of all PTO drives on the vehicle ...";
CM_ SG_ 2566759678 EnggmntSttsPTOEngAccessoryDrive2 "Engagement status of the PTO engine accessory drive 2

00 Drive not engaged
01 Drive engaged
10 Error
11 Not available";
CM_ SG_ 2566759678 EnggmntSttsPTOEngAccessoryDrive1 "Engagement status of the PTO engine accessory drive 1

00 Drive not engaged
01 Drive engaged
10 Error
11 Not available";
CM_ SG_ 2566759678 EngagementStatusPTOEngFlywheel "Engagement status of the PTO Engine Flywheel

00 Drive not engaged
01 Drive engaged
10 Error
11 Not available";
CM_ SG_ 2566759678 EnggmntStatusTransInputShaftPTO1 "Reports if this specific PTO drive is engaged.  This parameter should be broadcast only by the controller(s) receiving feedback about the specific drive.
For example, a pressure switch may be used to determine if a PTO-driven pump has been engaged ...";
CM_ SG_ 2566759678 EnggmntStatusTransInputShaftPTO2 "Reports if this specific PTO drive is engaged.  This parameter should be broadcast only by the controller(s) receiving feedback about the specific drive.
For example, a pressure switch may be used to determine if a PTO-driven pump has been engaged ...";
CM_ SG_ 2566759678 EnggmntStatusTransOutputShaftPTO "Reports if this specific PTO drive is engaged.  This parameter should be broadcast only by the controller(s) receiving feedback about the specific drive.
For example, a pressure switch may be used to determine if a PTO-driven pump has been engaged ...";
CM_ SG_ 2566759678 EnggmntSttsTrnsfrCsOtputShaftPTO "Reports if this specific PTO drive is engaged.  This parameter should be broadcast only by the controller(s) receiving feedback about the specific drive.
For example, a pressure switch may be used to determine if a PTO-driven pump has been engaged ...";
CM_ SG_ 2566759678 EnggmntCnsntPTOEngAccssoryDrive2 "Engagement Consent status for the PTO engine accessory drive 2 

00 Consent not given - PTO drive may not be engaged
01 Consent given - PTO drive may be engaged
10 Error
11 Not available";
CM_ SG_ 2566759678 EnggmntCnsntPTOEngAccssoryDrive1 "Engagement consent status for the PTO engine accessory drive 1

00 Consent not given - PTO drive may not be engaged
01 Consent given - PTO drive may be engaged
10 Error
11 Not available";
CM_ SG_ 2566759678 EngagementConsentPTOEngFlywheel "Engagement Consent status for the PTO Engine Flywheel

00 Consent not given - PTO drive may not be engaged
01 Consent given - PTO drive may be engaged
10 Error
11 Not available";
CM_ SG_ 2566759678 EnggmntCnsentTransInputShaftPTO1 "Status of the transmission controller's consent to engage the first or sole PTO drive mounted on the transmission case.  The controller in charge of the PTO drive should monitor this parameter and only engage the drive when consent is given.  If ...";
CM_ SG_ 2566759678 EnggmntCnsentTransInputShaftPTO2 "Status of the transmission controller's consent to engage the second PTO drive mounted on the transmission case.  The controller in charge of the PTO drive should monitor this parameter and only engage the drive when consent is given.  If consent is ...";
CM_ SG_ 2566759678 EnggmntCnsentTransOutputShaftPTO "Status of the transmission controller's consent to engage the PTO drive connected to the transmission output shaft.  The controller in charge of the PTO drive should monitor this parameter and only engage the drive when consent is given.  If consent ...";
CM_ SG_ 2566759678 EnggmntCnsntTrnsfrCsOtptShaftPTO "Status of the transmission controller's consent to engage the PTO drive connected to the transfer case output shaft.  The controller in charge of the PTO drive should monitor this parameter and only engage the drive when consent is given.  If ...";
CM_ SG_ 2566759678 EnbleSwitchPTOEngAccessoryDrive2 "Status of the PTO engine accessory drive 2 enable switch

00 Enable switch off - PTO operation not desired
01 Enable switch on - PTO operation desired
10 Error
11 Not available";
CM_ SG_ 2566759678 EnbleSwitchPTOEngAccessoryDrive1 "Status of the PTO engine accessory drive 1 enable switch

00 Enable switch off - PTO operation not desired
01 Enable switch on - PTO operation desired
10 Error
11 Not available";
CM_ SG_ 2566759678 EnableSwitchPTOEngFlywheel "Status of the PTO Engine Flywheel enable switch

00 Enable switch off - PTO operation not desired
01 Enable switch on - PTO operation desired 
10 Error
11 Not available";
CM_ SG_ 2566759678 EnableSwitchTransInputShaftPTO1 "Status of the operator's switch or other input which indicates the desire for engaging the first PTO drive mounted on the transmission case.  There may be more than one PTO drive mounted on the transmission case.
00   Enable switch off - PTO ...";
CM_ SG_ 2566759678 EnableSwitchTransInputShaftPTO2 "Status of the operator's switch or other input which indicates the desire for engaging the second PTO drive mounted on the transmission case.   If there is only one PTO drive on the transmission case, use SPN 3452 Enable Switch - Transmission input ...";
CM_ SG_ 2566759678 EnableSwitchTransOutputShaftPTO "Status of the operator's switch or other input which indicates the desire for engaging the PTO drive mounted on the transmission output shaft.
00   Enable switch off - PTO operation not desired
01   Enable switch on - PTO operation desired
10 ...";
CM_ SG_ 2566759678 EnblSwtchTrnsfrCseOutputShaftPTO "Status of the operator's switch or other input which indicates the desire for engaging the PTO drive mounted on the output shaft of the transfer case.
00   Enable switch off - PTO operation not desired
01   Enable switch on - PTO operation desired
 ...";
CM_ BO_ 2432541438 "Fuel Information 3 (Gaseous)
Gaseous fuel information 3";
CM_ SG_ 2432541438 EngFuelValve2OutletAbsPress "Absolute pressure of gas on outlet side of the second fuel system control valve.  See SPN 2980 for the first or only fuel system control valve.";
CM_ SG_ 2432541438 EngFuelTemp2 "Second Temperature measurement of fuel (or gas) of the first fuel type. See SPN 174 for first fuel temperature measurement.";
CM_ SG_ 2432541438 EngGas2MassFlowRate "Gas mass flow rate delivered to an engine through its second fuel control system, using standard convention for determining position.
In a system with two fuel system control valves, left/front is #1 (SPN 1241) and right/rear is #2 (SPN 3467).
In ...";
CM_ SG_ 2432541438 EngFuelValve2IntakeAbsPress "Absolute pressure of gas on intake side of the second fuel system control valve, using standard convention for determining position.
In a system with two fuel system control valves, left/front is #1 (SPN 1390) and right/rear is #2 (SPN 3466).
In a ...";
CM_ BO_ 2566761214 "Engine Fluid Level/Pressure 4
4th PGN which identifies parameters that are either measuring various pressures within the engine or identifying engine fluid levels";
CM_ SG_ 2566761214 EngChargeAirCoolerOutletPress "Measures pressure of air at outlet from charge air cooler";
CM_ SG_ 2566761214 EngAftercoolerCoolantLevel "Ratio of aftercooler coolant system volume of liquid to total cooling system volume.  The engine aftercooler coolant level is for  the low temperature (LT) cooling circuit used for the compressor outlet air or charge aftercooling.
SPN 111 'Coolant ...";
CM_ SG_ 2566761214 EngIntercoolerCoolantLevel "Ratio of volume of liquid found in an engine charge air cooler cooling system to total engine charge air cooler cooling system volume.";
CM_ SG_ 2566761214 EngCentrifugalOilFilterSpeed "The speed of a rotating (centrifugal) engine oil filter.";
CM_ SG_ 2566761214 EngCoolantPumpDiffPress "The differential pressure measured across the input and output of the engine coolant pump.";
CM_ SG_ 2566761214 EngChargeAirCooler2IntakePress "Pressure of air at intake to 2nd charge air cooler, from multiple first stage turbochargers being cooled and feeding multiple second stage turbochargers.";
CM_ SG_ 2566761214 EngChargeAirCooler1IntakePress "Pressure of air at intake to 1st or only charge air cooler, from multiple first stage turbochargers being cooled and feeding multiple second stage turbochargers.";
CM_ BO_ 2432541694 "Electronic Engine Controller 6
Engine related parameters";
CM_ SG_ 2432541694 EngVriableGeometryTurboActuator1 "Actuator that controls the variable geometry turbocharger geometry.The control command to the actuator, normalized to percent, where 0% nominally represents fully closed (smallest turbocharger geometry) and 100% represents fully open (largest ...";
CM_ SG_ 2432541694 EngTrbCmprssrBypssActtr1TmpSttus "Used to identify the status of the Engine Turbocharger Compresssor Bypass Actuator 1 drive circuitry temperature.  Temperature excursions may affect the torque output.
000 - High Most severe
001 - High Least severe
010 - In Range
011 - Low Least ...";
CM_ SG_ 2432541694 EngTrbCmprssrBypssActtr1PrlmnryF "Used to identify  the appplicable J1939-73 FMI detected in the Engine Turbocharger Compressor Bypass Actuator 1 by the manufacturers software. When there is no failure FMI 31 is transmitted. When there is multiple failures, the most severe is ...";
CM_ SG_ 2432541694 EngTrbCmprssorBypassActuator2Cmd "The command to a compressor bypass actuator 2, normalized to percent, where 0% nominally represents fully closed and 100% represents fully open. Typically, the turbocharger compressor bypass actuator is used to keep the engine out of surge by ...";
CM_ SG_ 2432541694 EngTrbCmprssorBypassActuator1Pos "Measures the position of the turbocharger compressor bypass actuator, where 0% represents bypass fully closed and 100% represents bypass fully open.  Typically, the compressor bypass is used to lower the compressor outlet pressure and/or intake ...";
CM_ SG_ 2432541694 EngTrbCmprssorBypassActuator1Cmd "The command to a compressor bypass actuator, normalized to percent, where 0% nominally represents fully closed and 100% represents fully open.  Typically, the turbocharger compressor bypass actuator is used to keep the engine out of surge by ...";
CM_ SG_ 2432541694 EngDsrdTrbCmprssrBypssActtor1Pos "The requested position of the Engine Turbocharger Compressor Bypass actuator by the engine ECU, where 0% represents bypass fully closed and 100% represents bypass fully open.

This is the position that the device is attempting to achieve.";
CM_ BO_ 2566759934 "Door Control 2
Used for door information.";
CM_ SG_ 2566759934 EnableStatusOfDoor10 "Enable status of bus door 10.  Enabled means the bus doors are able to be automatically opened or closed.

00  door disabled
01  door enabled
10  error
11  not available";
CM_ SG_ 2566759934 OpenStatusOfDoor10 "Open status of bus door 10

00  door closed
01  door opened
10  error
11  not available";
CM_ SG_ 2566759934 LockStatusOfDoor10 "Lock status of bus door 10

00  unlocked 
01  locked
10  error
11  not available";
CM_ SG_ 2566759934 EnableStatusOfDoor9 "Enable status of bus door 9.  Enabled means the bus doors are able to be automatically opened or closed.

00  door disabled
01  door enabled
10  error
11  not available";
CM_ SG_ 2566759934 OpenStatusOfDoor9 "Open status of bus door 9

00  door closed
01  door opened
10  error
11  not available";
CM_ SG_ 2566759934 LockStatusOfDoor9 "Lock status of bus door 9

00  unlocked 
01  locked
10  error
11  not available";
CM_ SG_ 2566759934 EnableStatusOfDoor8 "Enable status of bus door 8.  Enabled means the bus doors are able to be automatically opened or closed.

00  door disabled
01  door enabled
10  error
11  not available";
CM_ SG_ 2566759934 OpenStatusOfDoor8 "Open status of bus door 8

00  door closed
01  door opened
10  error
11  not available";
CM_ SG_ 2566759934 LockStatusOfDoor8 "Lock status of bus door 8

00  unlocked 
01  locked
10  error
11  not available";
CM_ SG_ 2566759934 EnableStatusOfDoor7 "Enable status of bus door 7.  Enabled means the bus doors are able to be automatically opened or closed.

00  door disabled
01  door enabled
10  error
11  not available";
CM_ SG_ 2566759934 OpenStatusOfDoor7 "Open status of bus door 7

00  door closed
01  door opened
10  error
11  not available";
CM_ SG_ 2566759934 LockStatusOfDoor7 "Lock status of bus door 7

00  unlocked 
01  locked
10  error
11  not available";
CM_ SG_ 2566759934 EnableStatusOfDoor6 "Enable status of bus door 6.  Enabled means the bus doors are able to be automatically opened or closed.

00  door disabled
01  door enabled
10  error
11  not available";
CM_ SG_ 2566759934 OpenStatusOfDoor6 "Open status of bus door 6

00  door closed
01  door opened
10  error
11  not available";
CM_ SG_ 2566759934 LockStatusOfDoor6 "Lock status of bus door 6

00  unlocked 
01  locked
10  error
11  not available";
CM_ SG_ 2566759934 EnableStatusOfDoor5 "Enable status of bus door 5.  Enabled means the bus doors are able to be automatically opened or closed.

00  door disabled
01  door enabled
10  error
11  not available";
CM_ SG_ 2566759934 OpenStatusOfDoor5 "Open status of bus door 5

00  door closed
01  door opened
10  error
11  not available";
CM_ SG_ 2566759934 LockStatusOfDoor5 "Lock status of bus door 5

00  unlocked 
01  locked
10  error
11  not available";
CM_ SG_ 2566759934 EnableStatusOfDoor4 "Enable status of bus door 4.  Enabled means the bus doors are able to be automatically opened or closed.

00  door disabled
01  door enabled
10  error
11  not available";
CM_ SG_ 2566759934 OpenStatusOfDoor4 "Open status of bus door 4

00  door closed
01  door opened
10  error
11  not available";
CM_ SG_ 2566759934 LockStatusOfDoor4 "Lock status of bus door 4

00  unlocked 
01  locked
10  error
11  not available";
CM_ SG_ 2566759934 EnableStatusOfDoor3 "Enable status of bus door 3.  Enabled means the bus doors are able to be automatically opened or closed.

00  door disabled
01  door enabled
10  error
11  not available";
CM_ SG_ 2566759934 OpenStatusOfDoor3 "Open status of bus door 3

00  door closed
01  door opened
10  error
11  not available";
CM_ SG_ 2566759934 LockStatusOfDoor3 "Lock status of bus door 3

00  unlocked 
01  locked
10  error
11  not available";
CM_ SG_ 2566759934 EnableStatusOfDoor2 "Enable status of bus door 2.  Enabled means the bus doors are able to be automatically opened or closed.

00  door disabled
01  door enabled
10  error
11  not available";
CM_ SG_ 2566759934 OpenStatusOfDoor2 "Open status of bus door 2

00  door closed
01  door opened
10  error
11  not available";
CM_ SG_ 2566759934 LockStatusOfDoor2 "Lock status of bus door 2

00  unlocked 
01  locked
10  error
11  not available";
CM_ SG_ 2566759934 EnableStatusOfDoor1 "Enable status of bus door 1.  Enabled means the bus doors are able to be automatically opened or closed.

00  door disabled
01  door enabled
10  error
11  not available";
CM_ SG_ 2566759934 OpenStatusOfDoor1 "Open status of bus door 1

00  door closed
01  door opened
10  error
11  not available";
CM_ SG_ 2566759934 LockStatusOfDoor1 "Lock status of bus door 1

00  unlocked 
01  locked
10  error
11  not available";
BA_DEF_ SG_  "SigType" ENUM  "Default","Range","RangeSigned","ASCII","Discrete","Control","ReferencePGN","DTC","StringDelimiter","StringLength","StringLengthControl","MessageCounter","MessageChecksum";
BA_DEF_ SG_  "GenSigStartValue" INT 0 2147483647;
BA_DEF_ SG_  "GenSigSendType" ENUM  "Cyclic","OnWrite","OnWriteWithRepetition","OnChange","OnChangeWithRepetition","IfActive","IfActiveWithRepetition","NoSigSendType";
BA_DEF_ SG_  "GenSigILSupport" ENUM  "No","Yes";
BA_DEF_ SG_  "GenSigEVName" STRING ;
BA_DEF_ SG_  "SPN" INT 0 524287;
BA_DEF_ BO_  "TpJ1939VarDlc" ENUM  "No","Yes";
BA_DEF_ BO_  "GenMsgCycleTimeFast" INT 0 3600000;
BA_DEF_ BO_  "GenMsgStartDelayTime" INT 0 100000;
BA_DEF_ BO_  "GenMsgILSupport" ENUM  "No","Yes";
BA_DEF_ BO_  "GenMsgDelayTime" INT 0 1000;
BA_DEF_ BO_  "GenMsgRequestable" INT 0 1;
BA_DEF_ BO_  "GenMsgSendType" ENUM  "cyclic","NotUsed","NotUsed","NotUsed","NotUsed","NotUsed","NotUsed","IfActive","noMsgSendType";
BA_DEF_ BO_  "VFrameFormat" ENUM  "StandardCAN","ExtendedCAN","reserved","J1939PG";
BA_DEF_ BO_  "GenMsgCycleTime" INT 0 3600000;
BA_DEF_ BO_  "SendOnChange" ENUM  "No","Yes";
BA_DEF_ SG_  "SystemSignalLongSymbol" STRING ;
BA_DEF_DEF_  "SigType" "Default";
BA_DEF_DEF_  "GenSigStartValue" 0;
BA_DEF_DEF_  "GenSigSendType" "NoSigSendType";
BA_DEF_DEF_  "GenSigILSupport" "Yes";
BA_DEF_DEF_  "GenSigEVName" "Env@Nodename_@Signame";
BA_DEF_DEF_  "SPN" 0;
BA_DEF_DEF_  "TpJ1939VarDlc" "No";
BA_DEF_DEF_  "GenMsgCycleTimeFast" 0;
BA_DEF_DEF_  "GenMsgStartDelayTime" 0;
BA_DEF_DEF_  "GenMsgILSupport" "Yes";
BA_DEF_DEF_  "GenMsgDelayTime" 0;
BA_DEF_DEF_  "GenMsgRequestable" 1;
BA_DEF_DEF_  "GenMsgSendType" "noMsgSendType";
BA_DEF_DEF_  "VFrameFormat" "J1939PG";
BA_DEF_DEF_  "GenMsgCycleTime" 0;
BA_DEF_DEF_  "SendOnChange" "No";
BA_DEF_DEF_  "SystemSignalLongSymbol" "";
BA_ "GenMsgCycleTime" BO_ 2566718974 1000;
BA_ "GenMsgSendType" BO_ 2566718974 0;
BA_ "GenMsgCycleTime" BO_ 2566719230 1000;
BA_ "GenMsgSendType" BO_ 2566719230 0;
BA_ "GenMsgDelayTime" BO_ 2566719230 100;
BA_ "TpJ1939VarDlc" BO_ 2560818942 1;
BA_ "GenMsgCycleTime" BO_ 2566746366 1000;
BA_ "GenMsgDelayTime" BO_ 2566746366 100;
BA_ "GenMsgCycleTime" BO_ 2566755582 100;
BA_ "GenMsgSendType" BO_ 2566755582 0;
BA_ "GenMsgCycleTime" BO_ 2566752510 500;
BA_ "GenMsgSendType" BO_ 2566752510 0;
BA_ "GenMsgCycleTime" BO_ 2566752254 500;
BA_ "GenMsgSendType" BO_ 2566752254 0;
BA_ "GenMsgCycleTime" BO_ 2566751998 500;
BA_ "GenMsgSendType" BO_ 2566751998 0;
BA_ "GenMsgCycleTime" BO_ 2566751742 500;
BA_ "GenMsgSendType" BO_ 2566751742 0;
BA_ "GenMsgCycleTime" BO_ 2566751486 500;
BA_ "GenMsgSendType" BO_ 2566751486 0;
BA_ "GenMsgCycleTime" BO_ 2499641854 500;
BA_ "GenMsgSendType" BO_ 2499641854 0;
BA_ "GenMsgCycleTime" BO_ 2561277694 100;
BA_ "GenMsgSendType" BO_ 2561277694 0;
BA_ "GenMsgCycleTime" BO_ 2565873150 10;
BA_ "GenMsgSendType" BO_ 2565873150 0;
BA_ "GenMsgCycleTime" BO_ 2566751230 1000;
BA_ "GenMsgSendType" BO_ 2566751230 0;
BA_ "GenMsgDelayTime" BO_ 2566751230 100;
BA_ "GenMsgCycleTime" BO_ 2566755838 1000;
BA_ "GenMsgSendType" BO_ 2566755838 0;
BA_ "GenMsgCycleTime" BO_ 2566799614 100;
BA_ "GenMsgCycleTime" BO_ 2365473278 1000;
BA_ "GenMsgSendType" BO_ 2365473278 0;
BA_ "GenMsgDelayTime" BO_ 2365473278 100;
BA_ "SendOnChange" BO_ 2365473278 1;
BA_ "GenMsgCycleTime" BO_ 2365485822 50;
BA_ "GenMsgSendType" BO_ 2365485822 0;
BA_ "GenMsgCycleTime" BO_ 2566768894 1000;
BA_ "GenMsgSendType" BO_ 2566768894 0;
BA_ "GenMsgCycleTime" BO_ 2566769406 1000;
BA_ "GenMsgSendType" BO_ 2566769406 0;
BA_ "GenMsgCycleTime" BO_ 2633934334 1000;
BA_ "GenMsgSendType" BO_ 2633934334 0;
BA_ "GenMsgCycleTime" BO_ 2566825726 5000;
BA_ "GenMsgSendType" BO_ 2566825726 0;
BA_ "GenMsgCycleTime" BO_ 2566770942 5000;
BA_ "GenMsgSendType" BO_ 2566770942 0;
BA_ "GenMsgCycleTime" BO_ 2566846206 5000;
BA_ "GenMsgSendType" BO_ 2566846206 0;
BA_ "GenMsgCycleTime" BO_ 2566811134 1000;
BA_ "GenMsgSendType" BO_ 2566811134 0;
BA_ "GenMsgCycleTime" BO_ 2298375934 20;
BA_ "GenMsgSendType" BO_ 2298375934 0;
BA_ "GenMsgCycleTime" BO_ 2565867774 50;
BA_ "GenMsgSendType" BO_ 2565867774 0;
BA_ "GenMsgCycleTime" BO_ 2365449982 100;
BA_ "GenMsgSendType" BO_ 2365449982 0;
BA_ "GenMsgCycleTime" BO_ 2566757630 1000;
BA_ "GenMsgSendType" BO_ 2566757630 0;
BA_ "GenMsgCycleTime" BO_ 2566757886 1000;
BA_ "GenMsgSendType" BO_ 2566757886 0;
BA_ "GenMsgCycleTime" BO_ 2566759678 100;
BA_ "GenMsgSendType" BO_ 2566759678 0;
BA_ "GenMsgCycleTime" BO_ 2432541438 500;
BA_ "GenMsgSendType" BO_ 2432541438 0;
BA_ "GenMsgCycleTime" BO_ 2566761214 500;
BA_ "GenMsgSendType" BO_ 2566761214 0;
BA_ "GenMsgCycleTime" BO_ 2432541694 100;
BA_ "GenMsgSendType" BO_ 2432541694 0;
BA_ "GenMsgCycleTime" BO_ 2566759934 100;
BA_ "GenMsgSendType" BO_ 2566759934 0;
BA_ "SPN" SG_ 2566718974 VhclAcclerationRateLimitLampData 6900;
BA_ "SigType" SG_ 2566718974 VhclAcclerationRateLimitLampData 4;
BA_ "SPN" SG_ 2566718974 EngSpeedVeryHighLampData 6712;
BA_ "SigType" SG_ 2566718974 EngSpeedVeryHighLampData 5;
BA_ "SPN" SG_ 2566718974 EngSpeedHighLampData 6711;
BA_ "SigType" SG_ 2566718974 EngSpeedHighLampData 5;
BA_ "SPN" SG_ 2566718974 EngCtrlMdule3ReadyForUseLampData 6204;
BA_ "SigType" SG_ 2566718974 EngCtrlMdule3ReadyForUseLampData 4;
BA_ "SPN" SG_ 2566718974 EngCtrlMdule2ReadyForUseLampData 6203;
BA_ "SigType" SG_ 2566718974 EngCtrlMdule2ReadyForUseLampData 4;
BA_ "SPN" SG_ 2566718974 EngCtrlMdule1ReadyForUseLampData 6202;
BA_ "SigType" SG_ 2566718974 EngCtrlMdule1ReadyForUseLampData 4;
BA_ "SPN" SG_ 2566718974 EngWaitToStartLampData 5416;
BA_ "SigType" SG_ 2566718974 EngWaitToStartLampData 4;
BA_ "SPN" SG_ 2566718974 EngFuelFilterRestrictedLampData 5470;
BA_ "SigType" SG_ 2566718974 EngFuelFilterRestrictedLampData 5;
BA_ "SPN" SG_ 2566718974 EngAirFilterRestrictionLampData 5103;
BA_ "SigType" SG_ 2566718974 EngAirFilterRestrictionLampData 4;
BA_ "SPN" SG_ 2566718974 EngIdleManagementActiveLampData 5102;
BA_ "SigType" SG_ 2566718974 EngIdleManagementActiveLampData 4;
BA_ "SPN" SG_ 2566718974 EngCoolantLevelLowLampData 5101;
BA_ "SigType" SG_ 2566718974 EngCoolantLevelLowLampData 4;
BA_ "SPN" SG_ 2566718974 EngCoolantTempHighLampData 5100;
BA_ "SigType" SG_ 2566718974 EngCoolantTempHighLampData 4;
BA_ "SPN" SG_ 2566718974 EngOilPressLowLampData 5099;
BA_ "SigType" SG_ 2566718974 EngOilPressLowLampData 4;
BA_ "SPN" SG_ 2566718974 CmprssnBrkEnblSwtchIndctrLmpData 5098;
BA_ "SigType" SG_ 2566718974 CmprssnBrkEnblSwtchIndctrLmpData 4;
BA_ "SPN" SG_ 2566718974 EngBrakeActiveLampData 5097;
BA_ "SigType" SG_ 2566718974 EngBrakeActiveLampData 4;
BA_ "SPN" SG_ 2566718974 OBDMalfunctionIndicatorLampData 5096;
BA_ "SigType" SG_ 2566718974 OBDMalfunctionIndicatorLampData 4;
BA_ "SPN" SG_ 2566718974 EngRedStopLampData 5095;
BA_ "SigType" SG_ 2566718974 EngRedStopLampData 4;
BA_ "SPN" SG_ 2566718974 EngAmberWarningLampData 5094;
BA_ "SigType" SG_ 2566718974 EngAmberWarningLampData 4;
BA_ "SPN" SG_ 2566718974 EngProtectLampData 5093;
BA_ "SigType" SG_ 2566718974 EngProtectLampData 4;
BA_ "SPN" SG_ 2566719230 HillHolderLampCmd 1847;
BA_ "SigType" SG_ 2566719230 HillHolderLampCmd 5;
BA_ "SPN" SG_ 2566719230 VehicleBatteryChargingLampCmd 5091;
BA_ "SigType" SG_ 2566719230 VehicleBatteryChargingLampCmd 5;
BA_ "SPN" SG_ 2566719230 VehicleHVACRecirculationLampCmd 5090;
BA_ "SigType" SG_ 2566719230 VehicleHVACRecirculationLampCmd 5;
BA_ "SPN" SG_ 2566719230 VehicleAirPressLowLampCmd 5089;
BA_ "SigType" SG_ 2566719230 VehicleAirPressLowLampCmd 5;
BA_ "SPN" SG_ 2566719230 VehicleFuelLevelLowLampCmd 5088;
BA_ "SigType" SG_ 2566719230 VehicleFuelLevelLowLampCmd 5;
BA_ "SPN" SG_ 2566719230 VehicleBatteryVoltageLowLampCmd 5087;
BA_ "SigType" SG_ 2566719230 VehicleBatteryVoltageLowLampCmd 5;
BA_ "SPN" SG_ 2560818942 SPN1 1214;
BA_ "SPN" SG_ 2560818942 FailureModeIdentifier1 1215;
BA_ "SPN" SG_ 2560818942 DTCTimeUntilDerate 4123;
BA_ "SigType" SG_ 2560818942 DTCTimeUntilDerate 1;
BA_ "SPN" SG_ 2560818942 DTCTotalPrevActiveTime 4122;
BA_ "SigType" SG_ 2560818942 DTCTotalPrevActiveTime 1;
BA_ "SPN" SG_ 2560818942 DTCTotalActiveTime 4121;
BA_ "SigType" SG_ 2560818942 DTCTotalActiveTime 1;
BA_ "SPN" SG_ 2561212158 TextDisplayIndex 3614;
BA_ "SigType" SG_ 2561212158 TextDisplayIndex 1;
BA_ "SPN" SG_ 2561212158 TextDisplayInstructions 3613;
BA_ "SPN" SG_ 2566746366 RetractStatusOfRamp5 4457;
BA_ "SigType" SG_ 2566746366 RetractStatusOfRamp5 5;
BA_ "SPN" SG_ 2566746366 RetractStatusOfRamp4 4454;
BA_ "SigType" SG_ 2566746366 RetractStatusOfRamp4 5;
BA_ "SPN" SG_ 2566746366 MovementStatusOfRamp5 4459;
BA_ "SigType" SG_ 2566746366 MovementStatusOfRamp5 5;
BA_ "SPN" SG_ 2566746366 MovementStatusOfRamp4 4456;
BA_ "SigType" SG_ 2566746366 MovementStatusOfRamp4 5;
BA_ "SPN" SG_ 2566746366 EnableStatusOfRamp5 4458;
BA_ "SigType" SG_ 2566746366 EnableStatusOfRamp5 5;
BA_ "SPN" SG_ 2566746366 EnableStatusOfRamp4 4455;
BA_ "SigType" SG_ 2566746366 EnableStatusOfRamp4 5;
BA_ "SPN" SG_ 2566746366 MovementStatusOfRamp3 3818;
BA_ "SigType" SG_ 2566746366 MovementStatusOfRamp3 5;
BA_ "SPN" SG_ 2566746366 EnableStatusOfRamp3 3817;
BA_ "SigType" SG_ 2566746366 EnableStatusOfRamp3 5;
BA_ "SPN" SG_ 2566746366 RetractStatusOfRamp3 3816;
BA_ "SigType" SG_ 2566746366 RetractStatusOfRamp3 5;
BA_ "SPN" SG_ 2566746366 MovementStatusOfRamp2 3815;
BA_ "SigType" SG_ 2566746366 MovementStatusOfRamp2 5;
BA_ "SPN" SG_ 2566746366 EnableStatusOfRamp2 3814;
BA_ "SigType" SG_ 2566746366 EnableStatusOfRamp2 5;
BA_ "SPN" SG_ 2566746366 RetractStatusOfRamp2 3813;
BA_ "SigType" SG_ 2566746366 RetractStatusOfRamp2 5;
BA_ "SPN" SG_ 2566746366 MovementStatusOfRamp1 3812;
BA_ "SigType" SG_ 2566746366 MovementStatusOfRamp1 5;
BA_ "SPN" SG_ 2566746366 EnableStatusOfRamp1 3811;
BA_ "SigType" SG_ 2566746366 EnableStatusOfRamp1 5;
BA_ "SPN" SG_ 2566746366 RetractStatusOfRamp1 3810;
BA_ "SigType" SG_ 2566746366 RetractStatusOfRamp1 5;
BA_ "SPN" SG_ 2566750206 EngConfigIdentification 6395;
BA_ "SigType" SG_ 2566750206 EngConfigIdentification 1;
BA_ "SPN" SG_ 2566750206 NmbrOfCmbstionCyclesForAveraging 6394;
BA_ "GenSigStartValue" SG_ 2566750206 NmbrOfCmbstionCyclesForAveraging 1;
BA_ "SigType" SG_ 2566750206 NmbrOfCmbstionCyclesForAveraging 1;
BA_ "SPN" SG_ 2566750206 MaxCrankAttemptsPerStartAttempt 3670;
BA_ "SigType" SG_ 2566750206 MaxCrankAttemptsPerStartAttempt 1;
BA_ "SPN" SG_ 2566755582 CommandedEngIntakeManifoldPress 5312;
BA_ "SigType" SG_ 2566755582 CommandedEngIntakeManifoldPress 1;
BA_ "SPN" SG_ 2566755582 EngCrnkcsBrtherOilSeparatorSpeed 5444;
BA_ "SigType" SG_ 2566755582 EngCrnkcsBrtherOilSeparatorSpeed 1;
BA_ "SPN" SG_ 2566755582 EngExhstGsRcirculation1Valve2Pos 3822;
BA_ "SigType" SG_ 2566755582 EngExhstGsRcirculation1Valve2Pos 1;
BA_ "SPN" SG_ 2566755582 EngExhstGsRecirculation1ValvePos 27;
BA_ "SigType" SG_ 2566755582 EngExhstGsRecirculation1ValvePos 1;
BA_ "SPN" SG_ 2566746110 EngExhstGsRcrcltn1ClerEfficiency 4752;
BA_ "SigType" SG_ 2566746110 EngExhstGsRcrcltn1ClerEfficiency 1;
BA_ "SPN" SG_ 2566746110 EngExhstGsRcrcltn1ClrIntkGsAbsPr 4751;
BA_ "SigType" SG_ 2566746110 EngExhstGsRcrcltn1ClrIntkGsAbsPr 1;
BA_ "SPN" SG_ 2566746110 EngExhstGsRcrcltn1ClerIntakeTemp 4750;
BA_ "SigType" SG_ 2566746110 EngExhstGsRcrcltn1ClerIntakeTemp 1;
BA_ "SPN" SG_ 2566746110 EngExhstGsRcrculation1Valve2Ctrl 3821;
BA_ "SigType" SG_ 2566746110 EngExhstGsRcrculation1Valve2Ctrl 1;
BA_ "SPN" SG_ 2566752510 EngIntkVlvActtionOilPressForCyl4 3627;
BA_ "SigType" SG_ 2566752510 EngIntkVlvActtionOilPressForCyl4 1;
BA_ "SPN" SG_ 2566752510 EngIntkVlvActtionOilPressForCyl3 3626;
BA_ "SigType" SG_ 2566752510 EngIntkVlvActtionOilPressForCyl3 1;
BA_ "SPN" SG_ 2566752510 EngIntkVlvActtionOilPressForCyl2 3625;
BA_ "SigType" SG_ 2566752510 EngIntkVlvActtionOilPressForCyl2 1;
BA_ "SPN" SG_ 2566752510 EngIntkVlvActtionOilPressForCyl1 3624;
BA_ "SigType" SG_ 2566752510 EngIntkVlvActtionOilPressForCyl1 1;
BA_ "SPN" SG_ 2566752254 EngIntkVlvActtionOilPressForCyl8 3631;
BA_ "SigType" SG_ 2566752254 EngIntkVlvActtionOilPressForCyl8 1;
BA_ "SPN" SG_ 2566752254 EngIntkVlvActtionOilPressForCyl7 3630;
BA_ "SigType" SG_ 2566752254 EngIntkVlvActtionOilPressForCyl7 1;
BA_ "SPN" SG_ 2566752254 EngIntkVlvActtionOilPressForCyl6 3629;
BA_ "SigType" SG_ 2566752254 EngIntkVlvActtionOilPressForCyl6 1;
BA_ "SPN" SG_ 2566752254 EngIntkVlvActtionOilPressForCyl5 3628;
BA_ "SigType" SG_ 2566752254 EngIntkVlvActtionOilPressForCyl5 1;
BA_ "SPN" SG_ 2566751998 EngIntkVlvActtonOilPressForCyl12 3635;
BA_ "SigType" SG_ 2566751998 EngIntkVlvActtonOilPressForCyl12 1;
BA_ "SPN" SG_ 2566751998 EngIntkVlvActtonOilPressForCyl11 3634;
BA_ "SigType" SG_ 2566751998 EngIntkVlvActtonOilPressForCyl11 1;
BA_ "SPN" SG_ 2566751998 EngIntkVlvActtonOilPressForCyl10 3633;
BA_ "SigType" SG_ 2566751998 EngIntkVlvActtonOilPressForCyl10 1;
BA_ "SPN" SG_ 2566751998 EngIntkVlvActtionOilPressForCyl9 3632;
BA_ "SigType" SG_ 2566751998 EngIntkVlvActtionOilPressForCyl9 1;
BA_ "SPN" SG_ 2566751742 EngIntkVlvActtonOilPressForCyl16 3639;
BA_ "SigType" SG_ 2566751742 EngIntkVlvActtonOilPressForCyl16 1;
BA_ "SPN" SG_ 2566751742 EngIntkVlvActtonOilPressForCyl15 3638;
BA_ "SigType" SG_ 2566751742 EngIntkVlvActtonOilPressForCyl15 1;
BA_ "SPN" SG_ 2566751742 EngIntkVlvActtonOilPressForCyl14 3637;
BA_ "SigType" SG_ 2566751742 EngIntkVlvActtonOilPressForCyl14 1;
BA_ "SPN" SG_ 2566751742 EngIntkVlvActtonOilPressForCyl13 3636;
BA_ "SigType" SG_ 2566751742 EngIntkVlvActtonOilPressForCyl13 1;
BA_ "SPN" SG_ 2566751486 EngIntkVlvActtonOilPressForCyl20 3643;
BA_ "SigType" SG_ 2566751486 EngIntkVlvActtonOilPressForCyl20 1;
BA_ "SPN" SG_ 2566751486 EngIntkVlvActtonOilPressForCyl19 3642;
BA_ "SigType" SG_ 2566751486 EngIntkVlvActtonOilPressForCyl19 1;
BA_ "SPN" SG_ 2566751486 EngIntkVlvActtonOilPressForCyl18 3641;
BA_ "SigType" SG_ 2566751486 EngIntkVlvActtonOilPressForCyl18 1;
BA_ "SPN" SG_ 2566751486 EngIntkVlvActtonOilPressForCyl17 3640;
BA_ "SigType" SG_ 2566751486 EngIntkVlvActtonOilPressForCyl17 1;
BA_ "SPN" SG_ 2499641854 EGR1CoolerBypassActuatorPostion 3672;
BA_ "SigType" SG_ 2499641854 EGR1CoolerBypassActuatorPostion 1;
BA_ "SPN" SG_ 2566748158 EngSparkPlug4 1297;
BA_ "SigType" SG_ 2566748158 EngSparkPlug4 1;
BA_ "SPN" SG_ 2566748158 EngSparkPlug3 1296;
BA_ "SigType" SG_ 2566748158 EngSparkPlug3 1;
BA_ "SPN" SG_ 2566748158 EngSparkPlug2 1295;
BA_ "SigType" SG_ 2566748158 EngSparkPlug2 1;
BA_ "SPN" SG_ 2566748158 EngSparkPlug1 1294;
BA_ "SigType" SG_ 2566748158 EngSparkPlug1 1;
BA_ "SPN" SG_ 2566747902 EngSparkPlug8 1301;
BA_ "SigType" SG_ 2566747902 EngSparkPlug8 1;
BA_ "SPN" SG_ 2566747902 EngSparkPlug7 1300;
BA_ "SigType" SG_ 2566747902 EngSparkPlug7 1;
BA_ "SPN" SG_ 2566747902 EngSparkPlug6 1299;
BA_ "SigType" SG_ 2566747902 EngSparkPlug6 1;
BA_ "SPN" SG_ 2566747902 EngSparkPlug5 1298;
BA_ "SigType" SG_ 2566747902 EngSparkPlug5 1;
BA_ "SPN" SG_ 2566747646 EngSparkPlug12 1305;
BA_ "SigType" SG_ 2566747646 EngSparkPlug12 1;
BA_ "SPN" SG_ 2566747646 EngSparkPlug11 1304;
BA_ "SigType" SG_ 2566747646 EngSparkPlug11 1;
BA_ "SPN" SG_ 2566747646 EngSparkPlug10 1303;
BA_ "SigType" SG_ 2566747646 EngSparkPlug10 1;
BA_ "SPN" SG_ 2566747646 EngSparkPlug9 1302;
BA_ "SigType" SG_ 2566747646 EngSparkPlug9 1;
BA_ "SPN" SG_ 2566747390 EngSparkPlug16 1309;
BA_ "SigType" SG_ 2566747390 EngSparkPlug16 1;
BA_ "SPN" SG_ 2566747390 EngSparkPlug15 1308;
BA_ "SigType" SG_ 2566747390 EngSparkPlug15 1;
BA_ "SPN" SG_ 2566747390 EngSparkPlug14 1307;
BA_ "SigType" SG_ 2566747390 EngSparkPlug14 1;
BA_ "SPN" SG_ 2566747390 EngSparkPlug13 1306;
BA_ "SigType" SG_ 2566747390 EngSparkPlug13 1;
BA_ "SPN" SG_ 2566747134 EngSparkPlug20 1313;
BA_ "SigType" SG_ 2566747134 EngSparkPlug20 1;
BA_ "SPN" SG_ 2566747134 EngSparkPlug19 1312;
BA_ "SigType" SG_ 2566747134 EngSparkPlug19 1;
BA_ "SPN" SG_ 2566747134 EngSparkPlug18 1311;
BA_ "SigType" SG_ 2566747134 EngSparkPlug18 1;
BA_ "SPN" SG_ 2566747134 EngSparkPlug17 1310;
BA_ "SigType" SG_ 2566747134 EngSparkPlug17 1;
BA_ "SPN" SG_ 2566746878 EngSparkPlug24 1317;
BA_ "SigType" SG_ 2566746878 EngSparkPlug24 1;
BA_ "SPN" SG_ 2566746878 EngSparkPlug23 1316;
BA_ "SigType" SG_ 2566746878 EngSparkPlug23 1;
BA_ "SPN" SG_ 2566746878 EngSparkPlug22 1315;
BA_ "SigType" SG_ 2566746878 EngSparkPlug22 1;
BA_ "SPN" SG_ 2566746878 EngSparkPlug21 1314;
BA_ "SigType" SG_ 2566746878 EngSparkPlug21 1;
BA_ "SPN" SG_ 2561277694 LaneKeepingAssistEnableCmd 9751;
BA_ "SigType" SG_ 2561277694 LaneKeepingAssistEnableCmd 5;
BA_ "SPN" SG_ 2561277694 LaneCenteringEnableCmd 3564;
BA_ "SigType" SG_ 2561277694 LaneCenteringEnableCmd 5;
BA_ "SPN" SG_ 2561277694 LaneDepartureWarningEnableCmd 3564;
BA_ "SigType" SG_ 2561277694 LaneDepartureWarningEnableCmd 5;
BA_ "SPN" SG_ 2633861886 J2012DTCOccurrenceCount 3622;
BA_ "SPN" SG_ 2633861886 J2012DTCStatus 3621;
BA_ "SPN" SG_ 2633861886 J2012DTC 3620;
BA_ "SPN" SG_ 2633861886 NumberOfJ2012DTCs 3619;
BA_ "SigType" SG_ 2633861886 NumberOfJ2012DTCs 1;
BA_ "SPN" SG_ 2565873150 MessageChecksum 3690;
BA_ "SigType" SG_ 2565873150 MessageChecksum 12;
BA_ "SPN" SG_ 2565873150 MessageCounter 3689;
BA_ "SigType" SG_ 2565873150 MessageCounter 11;
BA_ "SPN" SG_ 2565873150 SteerAngleSensorCalibrated 3688;
BA_ "SigType" SG_ 2565873150 SteerAngleSensorCalibrated 5;
BA_ "SPN" SG_ 2565873150 SteerAngleSensorActiveMode 3687;
BA_ "SigType" SG_ 2565873150 SteerAngleSensorActiveMode 5;
BA_ "SPN" SG_ 2565873150 SteerWheelAngleRange 3686;
BA_ "GenSigStartValue" SG_ 2565873150 SteerWheelAngleRange 32127;
BA_ "SigType" SG_ 2565873150 SteerWheelAngleRange 1;
BA_ "SPN" SG_ 2565873150 SteerWheelAngleRangeCounterType 3685;
BA_ "SigType" SG_ 2565873150 SteerWheelAngleRangeCounterType 5;
BA_ "SPN" SG_ 2565873150 SteerWheelAngleRangeCounter 3684;
BA_ "SPN" SG_ 2565873150 SteerWheelAngle 3683;
BA_ "SigType" SG_ 2565873150 SteerWheelAngle 1;
BA_ "SPN" SG_ 2566745854 SysSulfationLvl 7504;
BA_ "SigType" SG_ 2566745854 SysSulfationLvl 1;
BA_ "SPN" SG_ 2566745854 SCROpIndActiveTraveledDist 5463;
BA_ "SigType" SG_ 2566745854 SCROpIndActiveTraveledDist 1;
BA_ "SPN" SG_ 2566745854 ConversionEfficiency 4364;
BA_ "SigType" SG_ 2566745854 ConversionEfficiency 1;
BA_ "SPN" SG_ 2566745854 CommandedDEFConsumption 3828;
BA_ "SigType" SG_ 2566745854 CommandedDEFConsumption 1;
BA_ "SPN" SG_ 2566745854 DEFAvgConsumption 3826;
BA_ "SigType" SG_ 2566745854 DEFAvgConsumption 1;
BA_ "SPN" SG_ 2566751230 TransferCaseStatus 3645;
BA_ "SPN" SG_ 2566755838 TransOilLevel2MeasurementStatus 5916;
BA_ "SPN" SG_ 2566755838 TransOilLevel2CountdownTimer 5915;
BA_ "SPN" SG_ 2566755838 TransOilLevel2High_Low 5914;
BA_ "SigType" SG_ 2566755838 TransOilLevel2High_Low 1;
BA_ "SPN" SG_ 2566755838 TransOilTemp2 5913;
BA_ "SigType" SG_ 2566755838 TransOilTemp2 1;
BA_ "SPN" SG_ 2566755838 TransOilLifeRemaining 4177;
BA_ "SigType" SG_ 2566755838 TransOilLifeRemaining 1;
BA_ "SPN" SG_ 2566755838 TrnsTorqueConverterOilOutletTemp 3823;
BA_ "SigType" SG_ 2566755838 TrnsTorqueConverterOilOutletTemp 1;
BA_ "SPN" SG_ 2566755838 TransOverheatIndicator 5345;
BA_ "SigType" SG_ 2566755838 TransOverheatIndicator 5;
BA_ "SPN" SG_ 2566755838 TransOilLevelSwitch 3533;
BA_ "SigType" SG_ 2566755838 TransOilLevelSwitch 5;
BA_ "SPN" SG_ 2566755838 TransOilFilterRestrictionSwitch 3359;
BA_ "SigType" SG_ 2566755838 TransOilFilterRestrictionSwitch 5;
BA_ "SPN" SG_ 2566752766 VehicleRoll 3623;
BA_ "GenSigStartValue" SG_ 2566752766 VehicleRoll 14080;
BA_ "SigType" SG_ 2566752766 VehicleRoll 1;
BA_ "SPN" SG_ 2633938942 TotalEngCruiseTime 1017;
BA_ "SigType" SG_ 2633938942 TotalEngCruiseTime 1;
BA_ "SPN" SG_ 2633938942 TotalDriveAverageLoadFactor 1016;
BA_ "SigType" SG_ 2633938942 TotalDriveAverageLoadFactor 1;
BA_ "SPN" SG_ 2633938942 TripDriveAverageLoadFactor 1015;
BA_ "SigType" SG_ 2633938942 TripDriveAverageLoadFactor 1;
BA_ "SPN" SG_ 2633938942 TripAverageEngSpeed 1014;
BA_ "SigType" SG_ 2633938942 TripAverageEngSpeed 1;
BA_ "SPN" SG_ 2633938942 TripMaxEngSpeed 1013;
BA_ "SigType" SG_ 2633938942 TripMaxEngSpeed 1;
BA_ "SPN" SG_ 2566799614 ImplementRearWorkLight 2394;
BA_ "SigType" SG_ 2566799614 ImplementRearWorkLight 4;
BA_ "SPN" SG_ 2566799614 ImplLeftFacingWorkLight 2400;
BA_ "SigType" SG_ 2566799614 ImplLeftFacingWorkLight 4;
BA_ "SPN" SG_ 2566799614 ImplRightForwardWorkLight 2402;
BA_ "SigType" SG_ 2566799614 ImplRightForwardWorkLight 4;
BA_ "SPN" SG_ 2566799614 ImplLeftForwardWorkLight 2598;
BA_ "SigType" SG_ 2566799614 ImplLeftForwardWorkLight 4;
BA_ "SPN" SG_ 2566799614 ImplRightFacingWorkLight 2407;
BA_ "SigType" SG_ 2566799614 ImplRightFacingWorkLight 4;
BA_ "SPN" SG_ 2566799614 ImplementOEMOption1Light 2396;
BA_ "SigType" SG_ 2566799614 ImplementOEMOption1Light 4;
BA_ "SPN" SG_ 2566799614 ImplementOEMOption2Light 2398;
BA_ "SigType" SG_ 2566799614 ImplementOEMOption2Light 4;
BA_ "SPN" SG_ 2566799614 TrctorFrontHighMdWkLights 2356;
BA_ "SigType" SG_ 2566799614 TrctorFrontHighMdWkLights 4;
BA_ "SPN" SG_ 2566799614 TractorFrontLowMdWkLights 2354;
BA_ "SigType" SG_ 2566799614 TractorFrontLowMdWkLights 4;
BA_ "SPN" SG_ 2566799614 TractorSideHighMdWkLights 2366;
BA_ "SigType" SG_ 2566799614 TractorSideHighMdWkLights 4;
BA_ "SPN" SG_ 2566799614 TractorSideLowMdWkLights 2364;
BA_ "SigType" SG_ 2566799614 TractorSideLowMdWkLights 4;
BA_ "SPN" SG_ 2566799614 TractorRearHighMdWkLights 2362;
BA_ "SigType" SG_ 2566799614 TractorRearHighMdWkLights 4;
BA_ "SPN" SG_ 2566799614 TractorRearLowMdWkLights 2360;
BA_ "SigType" SG_ 2566799614 TractorRearLowMdWkLights 4;
BA_ "SPN" SG_ 2566799614 TrctorUndersideMdWkLights 2358;
BA_ "SigType" SG_ 2566799614 TrctorUndersideMdWkLights 4;
BA_ "SPN" SG_ 2566799614 RearFogLights 2390;
BA_ "SigType" SG_ 2566799614 RearFogLights 4;
BA_ "SPN" SG_ 2566799614 TractorMarkerLight 2378;
BA_ "SigType" SG_ 2566799614 TractorMarkerLight 4;
BA_ "SPN" SG_ 2566799614 ImplementMarkerLight 2380;
BA_ "SigType" SG_ 2566799614 ImplementMarkerLight 4;
BA_ "SPN" SG_ 2566799614 TractorClearanceLight 2382;
BA_ "SigType" SG_ 2566799614 TractorClearanceLight 4;
BA_ "SPN" SG_ 2566799614 ImplementClearanceLight 2384;
BA_ "SigType" SG_ 2566799614 ImplementClearanceLight 4;
BA_ "SPN" SG_ 2566799614 LeftStopLight 2372;
BA_ "SigType" SG_ 2566799614 LeftStopLight 4;
BA_ "SPN" SG_ 2566799614 RightStopLight 2374;
BA_ "SigType" SG_ 2566799614 RightStopLight 4;
BA_ "SPN" SG_ 2566799614 CenterStopLight 2376;
BA_ "SigType" SG_ 2566799614 CenterStopLight 4;
BA_ "SPN" SG_ 2566799614 BackUpLightAndAlarmHorn 2392;
BA_ "SigType" SG_ 2566799614 BackUpLightAndAlarmHorn 4;
BA_ "SPN" SG_ 2566799614 LeftTurnSignalLights 2368;
BA_ "SigType" SG_ 2566799614 LeftTurnSignalLights 4;
BA_ "SPN" SG_ 2566799614 RightTurnSignalLights 2370;
BA_ "SigType" SG_ 2566799614 RightTurnSignalLights 4;
BA_ "SPN" SG_ 2566799614 RotatingBeaconLight 2386;
BA_ "SigType" SG_ 2566799614 RotatingBeaconLight 4;
BA_ "SPN" SG_ 2566799614 TractorFrontFogLights 2388;
BA_ "SigType" SG_ 2566799614 TractorFrontFogLights 4;
BA_ "SPN" SG_ 2566799614 HighBeamHeadLight 2348;
BA_ "SigType" SG_ 2566799614 HighBeamHeadLight 4;
BA_ "SPN" SG_ 2566799614 LowBeamHeadLight 2350;
BA_ "SigType" SG_ 2566799614 LowBeamHeadLight 4;
BA_ "SPN" SG_ 2566799614 AltBeamHeadLight 2352;
BA_ "SigType" SG_ 2566799614 AltBeamHeadLight 4;
BA_ "SPN" SG_ 2566799614 RunningLight 2404;
BA_ "SigType" SG_ 2566799614 RunningLight 4;
BA_ "SPN" SG_ 2365473278 ImplementRearWorkLightCmd 2405;
BA_ "SigType" SG_ 2365473278 ImplementRearWorkLightCmd 5;
BA_ "SPN" SG_ 2365473278 ImplLeftFacingWorkLightCmd 2399;
BA_ "SigType" SG_ 2365473278 ImplLeftFacingWorkLightCmd 5;
BA_ "SPN" SG_ 2365473278 ImplRightFwdWorkLightCmd 2401;
BA_ "SigType" SG_ 2365473278 ImplRightFwdWorkLightCmd 5;
BA_ "SPN" SG_ 2365473278 LightingDataRqCmd 2393;
BA_ "SigType" SG_ 2365473278 LightingDataRqCmd 5;
BA_ "SPN" SG_ 2365473278 ImplLeftForwardWorkLightCmd 2597;
BA_ "SigType" SG_ 2365473278 ImplLeftForwardWorkLightCmd 5;
BA_ "SPN" SG_ 2365473278 ImplRightFacingWorkLightCmd 2406;
BA_ "SigType" SG_ 2365473278 ImplRightFacingWorkLightCmd 5;
BA_ "SPN" SG_ 2365473278 ImplOEMOption1LightCmd 2395;
BA_ "SigType" SG_ 2365473278 ImplOEMOption1LightCmd 5;
BA_ "SPN" SG_ 2365473278 ImplOEMOption2LightCmd 2397;
BA_ "SigType" SG_ 2365473278 ImplOEMOption2LightCmd 5;
BA_ "SPN" SG_ 2365473278 TrctrFrntHghMdWkLightsCmd 2355;
BA_ "SigType" SG_ 2365473278 TrctrFrntHghMdWkLightsCmd 5;
BA_ "SPN" SG_ 2365473278 TrctrFrntLowMdWkLightsCmd 2353;
BA_ "SigType" SG_ 2365473278 TrctrFrntLowMdWkLightsCmd 5;
BA_ "SPN" SG_ 2365473278 TrctrSdeHighMdWkLightsCmd 2365;
BA_ "SigType" SG_ 2365473278 TrctrSdeHighMdWkLightsCmd 5;
BA_ "SPN" SG_ 2365473278 TrctrSideLowMdWkLightsCmd 2363;
BA_ "SigType" SG_ 2365473278 TrctrSideLowMdWkLightsCmd 5;
BA_ "SPN" SG_ 2365473278 TrctrRarHighMdWkLightsCmd 2361;
BA_ "SigType" SG_ 2365473278 TrctrRarHighMdWkLightsCmd 5;
BA_ "SPN" SG_ 2365473278 TrctrRearLowMdWkLightsCmd 2359;
BA_ "SigType" SG_ 2365473278 TrctrRearLowMdWkLightsCmd 5;
BA_ "SPN" SG_ 2365473278 TrctrUndrsdeMdWkLightsCmd 2357;
BA_ "SigType" SG_ 2365473278 TrctrUndrsdeMdWkLightsCmd 5;
BA_ "SPN" SG_ 2365473278 RearFogLightsCmd 2389;
BA_ "SigType" SG_ 2365473278 RearFogLightsCmd 5;
BA_ "SPN" SG_ 2365473278 TractorMarkerLightCmd 2377;
BA_ "SigType" SG_ 2365473278 TractorMarkerLightCmd 5;
BA_ "SPN" SG_ 2365473278 ImplementMarkerLightCmd 2379;
BA_ "SigType" SG_ 2365473278 ImplementMarkerLightCmd 5;
BA_ "SPN" SG_ 2365473278 TractorClearanceLightCmd 2381;
BA_ "SigType" SG_ 2365473278 TractorClearanceLightCmd 5;
BA_ "SPN" SG_ 2365473278 ImplementClearanceLightCmd 2383;
BA_ "SigType" SG_ 2365473278 ImplementClearanceLightCmd 5;
BA_ "SPN" SG_ 2365473278 LeftStopLightCmd 2371;
BA_ "SigType" SG_ 2365473278 LeftStopLightCmd 5;
BA_ "SPN" SG_ 2365473278 RightStopLightCmd 2373;
BA_ "SigType" SG_ 2365473278 RightStopLightCmd 5;
BA_ "SPN" SG_ 2365473278 CenterStopLightCmd 2375;
BA_ "SigType" SG_ 2365473278 CenterStopLightCmd 5;
BA_ "SPN" SG_ 2365473278 BackUpLightAndAlarmHornCmd 2391;
BA_ "SigType" SG_ 2365473278 BackUpLightAndAlarmHornCmd 5;
BA_ "SPN" SG_ 2365473278 LeftTurnSignalLightsCmd 2367;
BA_ "SigType" SG_ 2365473278 LeftTurnSignalLightsCmd 5;
BA_ "SPN" SG_ 2365473278 RightTurnSignalLightsCmd 2369;
BA_ "SigType" SG_ 2365473278 RightTurnSignalLightsCmd 5;
BA_ "SPN" SG_ 2365473278 RotatingBeaconLightCmd 2385;
BA_ "SigType" SG_ 2365473278 RotatingBeaconLightCmd 5;
BA_ "SPN" SG_ 2365473278 TractorFrontFogLightsCmd 2387;
BA_ "SigType" SG_ 2365473278 TractorFrontFogLightsCmd 5;
BA_ "SPN" SG_ 2365473278 HighBeamHeadLightCmd 2347;
BA_ "SigType" SG_ 2365473278 HighBeamHeadLightCmd 5;
BA_ "SPN" SG_ 2365473278 LowBeamHeadLightCmd 2349;
BA_ "SigType" SG_ 2365473278 LowBeamHeadLightCmd 5;
BA_ "SPN" SG_ 2365473278 AltBeamHeadLightCmd 2351;
BA_ "SigType" SG_ 2365473278 AltBeamHeadLightCmd 5;
BA_ "SPN" SG_ 2365473278 RunningLightCmd 2403;
BA_ "SigType" SG_ 2365473278 RunningLightCmd 5;
BA_ "SPN" SG_ 2365485822 LandLevelingSystemEnableStatus 5409;
BA_ "SigType" SG_ 2365485822 LandLevelingSystemEnableStatus 5;
BA_ "SPN" SG_ 2365485822 BladeCtrlModeRight 5408;
BA_ "SPN" SG_ 2365485822 BladeCtrlModeLeft 5407;
BA_ "SPN" SG_ 2365485822 BladeCtrlMode 1578;
BA_ "SPN" SG_ 2365485822 BladeDurationAndDirection 1577;
BA_ "SigType" SG_ 2365485822 BladeDurationAndDirection 1;
BA_ "SPN" SG_ 2633926654 EngActualIgntTiming 1436;
BA_ "SigType" SG_ 2633926654 EngActualIgntTiming 1;
BA_ "SPN" SG_ 2633926654 EngDesiredIgntTiming3 1435;
BA_ "SigType" SG_ 2633926654 EngDesiredIgntTiming3 1;
BA_ "SPN" SG_ 2633926654 EngDesiredIgntTiming2 1434;
BA_ "SigType" SG_ 2633926654 EngDesiredIgntTiming2 1;
BA_ "SPN" SG_ 2633926654 EngDesiredIgntTiming1 1433;
BA_ "SigType" SG_ 2633926654 EngDesiredIgntTiming1 1;
BA_ "SPN" SG_ 2633926398 EngCyl20IgntTiming 1432;
BA_ "SigType" SG_ 2633926398 EngCyl20IgntTiming 1;
BA_ "SPN" SG_ 2633926398 EngCyl19IgntTiming 1431;
BA_ "SigType" SG_ 2633926398 EngCyl19IgntTiming 1;
BA_ "SPN" SG_ 2633926398 EngCyl18IgntTiming 1430;
BA_ "SigType" SG_ 2633926398 EngCyl18IgntTiming 1;
BA_ "SPN" SG_ 2633926398 EngCyl17IgntTiming 1429;
BA_ "SigType" SG_ 2633926398 EngCyl17IgntTiming 1;
BA_ "SPN" SG_ 2633926142 EngCyl16IgntTiming 1428;
BA_ "SigType" SG_ 2633926142 EngCyl16IgntTiming 1;
BA_ "SPN" SG_ 2633926142 EngCyl15IgntTiming 1427;
BA_ "SigType" SG_ 2633926142 EngCyl15IgntTiming 1;
BA_ "SPN" SG_ 2633926142 EngCyl14IgntTiming 1426;
BA_ "SigType" SG_ 2633926142 EngCyl14IgntTiming 1;
BA_ "SPN" SG_ 2633926142 EngCyl13IgntTiming 1425;
BA_ "SigType" SG_ 2633926142 EngCyl13IgntTiming 1;
BA_ "SPN" SG_ 2633925886 EngCyl12IgntTiming 1424;
BA_ "SigType" SG_ 2633925886 EngCyl12IgntTiming 1;
BA_ "SPN" SG_ 2633925886 EngCyl11IgntTiming 1423;
BA_ "SigType" SG_ 2633925886 EngCyl11IgntTiming 1;
BA_ "SPN" SG_ 2633925886 EngCyl10IgntTiming 1422;
BA_ "SigType" SG_ 2633925886 EngCyl10IgntTiming 1;
BA_ "SPN" SG_ 2633925886 EngCyl9IgntTiming 1421;
BA_ "SigType" SG_ 2633925886 EngCyl9IgntTiming 1;
BA_ "SPN" SG_ 2633925630 EngCyl8IgntTiming 1420;
BA_ "SigType" SG_ 2633925630 EngCyl8IgntTiming 1;
BA_ "SPN" SG_ 2633925630 EngCyl7IgntTiming 1419;
BA_ "SigType" SG_ 2633925630 EngCyl7IgntTiming 1;
BA_ "SPN" SG_ 2633925630 EngCyl6IgntTiming 1418;
BA_ "SigType" SG_ 2633925630 EngCyl6IgntTiming 1;
BA_ "SPN" SG_ 2633925630 EngCyl5IgntTiming 1417;
BA_ "SigType" SG_ 2633925630 EngCyl5IgntTiming 1;
BA_ "SPN" SG_ 2633925374 EngCyl4IgntTiming 1416;
BA_ "SigType" SG_ 2633925374 EngCyl4IgntTiming 1;
BA_ "SPN" SG_ 2633925374 EngCyl3IgntTiming 1415;
BA_ "SigType" SG_ 2633925374 EngCyl3IgntTiming 1;
BA_ "SPN" SG_ 2633925374 EngCyl2IgntTiming 1414;
BA_ "SigType" SG_ 2633925374 EngCyl2IgntTiming 1;
BA_ "SPN" SG_ 2633925374 EngCyl1IgntTiming 1413;
BA_ "SigType" SG_ 2633925374 EngCyl1IgntTiming 1;
BA_ "SPN" SG_ 2633927422 EngCyl20IgntTransSecondOutput 1412;
BA_ "SigType" SG_ 2633927422 EngCyl20IgntTransSecondOutput 1;
BA_ "SPN" SG_ 2633927422 EngCyl19IgntTransSecondOutput 1411;
BA_ "SigType" SG_ 2633927422 EngCyl19IgntTransSecondOutput 1;
BA_ "SPN" SG_ 2633927422 EngCyl18IgntTransSecondOutput 1410;
BA_ "SigType" SG_ 2633927422 EngCyl18IgntTransSecondOutput 1;
BA_ "SPN" SG_ 2633927422 EngCyl17IgntTransSecondOutput 1409;
BA_ "SigType" SG_ 2633927422 EngCyl17IgntTransSecondOutput 1;
BA_ "SPN" SG_ 2633927166 EngCyl16IgntTransSecondOutput 1408;
BA_ "SigType" SG_ 2633927166 EngCyl16IgntTransSecondOutput 1;
BA_ "SPN" SG_ 2633927166 EngCyl15IgntTransSecondOutput 1407;
BA_ "SigType" SG_ 2633927166 EngCyl15IgntTransSecondOutput 1;
BA_ "SPN" SG_ 2633927166 EngCyl14IgntTransSecondOutput 1406;
BA_ "SigType" SG_ 2633927166 EngCyl14IgntTransSecondOutput 1;
BA_ "SPN" SG_ 2633927166 EngCyl13IgntTransSecondOutput 1405;
BA_ "SigType" SG_ 2633927166 EngCyl13IgntTransSecondOutput 1;
BA_ "SPN" SG_ 2633927166 EngCyl12IgntTransSecondOutput 1404;
BA_ "SigType" SG_ 2633927166 EngCyl12IgntTransSecondOutput 1;
BA_ "SPN" SG_ 2633927166 EngCyl11IgntTransSecondOutput 1403;
BA_ "SigType" SG_ 2633927166 EngCyl11IgntTransSecondOutput 1;
BA_ "SPN" SG_ 2633927166 EngCyl10IgntTransSecondOutput 1402;
BA_ "SigType" SG_ 2633927166 EngCyl10IgntTransSecondOutput 1;
BA_ "SPN" SG_ 2633927166 EngCyl9IgntTransSecondOutput 1401;
BA_ "SigType" SG_ 2633927166 EngCyl9IgntTransSecondOutput 1;
BA_ "SPN" SG_ 2633926910 EngCyl8IgntTransSecondOutput 1400;
BA_ "SigType" SG_ 2633926910 EngCyl8IgntTransSecondOutput 1;
BA_ "SPN" SG_ 2633926910 EngCyl7IgntTransSecondOutput 1399;
BA_ "SigType" SG_ 2633926910 EngCyl7IgntTransSecondOutput 1;
BA_ "SPN" SG_ 2633926910 EngCyl6IgntTransSecondOutput 1398;
BA_ "SigType" SG_ 2633926910 EngCyl6IgntTransSecondOutput 1;
BA_ "SPN" SG_ 2633926910 EngCyl5IgntTransSecondOutput 1397;
BA_ "SigType" SG_ 2633926910 EngCyl5IgntTransSecondOutput 1;
BA_ "SPN" SG_ 2633926910 EngCyl4IgntTransSecondOutput 1396;
BA_ "SigType" SG_ 2633926910 EngCyl4IgntTransSecondOutput 1;
BA_ "SPN" SG_ 2633926910 EngCyl3IgntTransSecondOutput 1395;
BA_ "SigType" SG_ 2633926910 EngCyl3IgntTransSecondOutput 1;
BA_ "SPN" SG_ 2633926910 EngCyl2IgntTransSecondOutput 1394;
BA_ "SigType" SG_ 2633926910 EngCyl2IgntTransSecondOutput 1;
BA_ "SPN" SG_ 2633926910 EngCyl1IgntTransSecondOutput 1393;
BA_ "SigType" SG_ 2633926910 EngCyl1IgntTransSecondOutput 1;
BA_ "SPN" SG_ 2566768894 EngOprtrPrmryIntrmdtSpdSlctState 2892;
BA_ "SPN" SG_ 2566769406 EngOprtrPrmryIntrmdteSpeedSelect 2880;
BA_ "SPN" SG_ 2566839550 EngTotalIdleHours 235;
BA_ "SigType" SG_ 2566839550 EngTotalIdleHours 1;
BA_ "SPN" SG_ 2566839550 EngTotalIdleFuelUsed 236;
BA_ "SigType" SG_ 2566839550 EngTotalIdleFuelUsed 1;
BA_ "SPN" SG_ 2633934334 EngIntakeManifold6Temp 1803;
BA_ "SigType" SG_ 2633934334 EngIntakeManifold6Temp 1;
BA_ "SPN" SG_ 2633934334 EngIntakeManifold5Temp 1802;
BA_ "SigType" SG_ 2633934334 EngIntakeManifold5Temp 1;
BA_ "SPN" SG_ 2633934334 EngIntakeManifold4Temp 1133;
BA_ "SigType" SG_ 2633934334 EngIntakeManifold4Temp 1;
BA_ "SPN" SG_ 2633934334 EngIntakeManifold3Temp 1132;
BA_ "SigType" SG_ 2633934334 EngIntakeManifold3Temp 1;
BA_ "SPN" SG_ 2633934334 EngIntakeManifold2Temp 1131;
BA_ "SigType" SG_ 2633934334 EngIntakeManifold2Temp 1;
BA_ "SPN" SG_ 2566825726 EngTurbo4BoostPress 1130;
BA_ "SigType" SG_ 2566825726 EngTurbo4BoostPress 1;
BA_ "SPN" SG_ 2566825726 EngTurbo3BoostPress 1129;
BA_ "SigType" SG_ 2566825726 EngTurbo3BoostPress 1;
BA_ "SPN" SG_ 2566825726 EngTurbo2BoostPress 1128;
BA_ "SigType" SG_ 2566825726 EngTurbo2BoostPress 1;
BA_ "SPN" SG_ 2566825726 EngTurbo1BoostPress 1127;
BA_ "SigType" SG_ 2566825726 EngTurbo1BoostPress 1;
BA_ "SPN" SG_ 2566770942 EngIntakeManifold2AbsPress 5422;
BA_ "SigType" SG_ 2566770942 EngIntakeManifold2AbsPress 1;
BA_ "SPN" SG_ 2566770942 EngIntakeManifold1AbsPress4817 4817;
BA_ "SigType" SG_ 2566770942 EngIntakeManifold1AbsPress4817 1;
BA_ "SPN" SG_ 2566770942 EngIntakeManifold1AbsPress 3563;
BA_ "SigType" SG_ 2566770942 EngIntakeManifold1AbsPress 1;
BA_ "SPN" SG_ 2566770942 EngIntakeManifold2Press 3562;
BA_ "SigType" SG_ 2566770942 EngIntakeManifold2Press 1;
BA_ "SPN" SG_ 2566770942 EngAirFilter4DiffPress 2811;
BA_ "SigType" SG_ 2566770942 EngAirFilter4DiffPress 1;
BA_ "SPN" SG_ 2566770942 EngAirFilter3DiffPress 2810;
BA_ "SigType" SG_ 2566770942 EngAirFilter3DiffPress 1;
BA_ "SPN" SG_ 2566770942 EngAirFilter2DiffPress 2809;
BA_ "SigType" SG_ 2566770942 EngAirFilter2DiffPress 1;
BA_ "SPN" SG_ 2566846206 EngCoolantFilterDiffPress 112;
BA_ "SigType" SG_ 2566846206 EngCoolantFilterDiffPress 1;
BA_ "SPN" SG_ 2566846206 EngExhaustGasTemp 173;
BA_ "SigType" SG_ 2566846206 EngExhaustGasTemp 1;
BA_ "SPN" SG_ 2566846206 EngAirFilter1DiffPress 107;
BA_ "SigType" SG_ 2566846206 EngAirFilter1DiffPress 1;
BA_ "SPN" SG_ 2566846206 EngAirIntakePress 106;
BA_ "SigType" SG_ 2566846206 EngAirIntakePress 1;
BA_ "SPN" SG_ 2566846206 EngIntakeManifold1Temp 105;
BA_ "SigType" SG_ 2566846206 EngIntakeManifold1Temp 1;
BA_ "SPN" SG_ 2566846206 EngIntakeManifold1Press 102;
BA_ "SigType" SG_ 2566846206 EngIntakeManifold1Press 1;
BA_ "SPN" SG_ 2566846206 AFT1DPFInPress 81;
BA_ "SigType" SG_ 2566846206 AFT1DPFInPress 1;
BA_ "SPN" SG_ 2566811134 ADRCompliantHeaterInstallation 6821;
BA_ "SigType" SG_ 2566811134 ADRCompliantHeaterInstallation 5;
BA_ "SPN" SG_ 2566811134 CabHeatingZone 1680;
BA_ "SigType" SG_ 2566811134 CabHeatingZone 5;
BA_ "SPN" SG_ 2566811134 EngHeatingZone 1679;
BA_ "SigType" SG_ 2566811134 EngHeatingZone 5;
BA_ "SPN" SG_ 2566811134 CabVentilation 1678;
BA_ "SigType" SG_ 2566811134 CabVentilation 5;
BA_ "SPN" SG_ 2566811134 AuxHeaterWaterPumpStatus 1676;
BA_ "SigType" SG_ 2566811134 AuxHeaterWaterPumpStatus 5;
BA_ "SPN" SG_ 2566811134 AuxHeaterMode 1677;
BA_ "SPN" SG_ 2566811134 AuxHeaterOutputPowerPercent 1689;
BA_ "SigType" SG_ 2566811134 AuxHeaterOutputPowerPercent 1;
BA_ "SPN" SG_ 2566811134 AuxHeaterInputAirTemp 1688;
BA_ "SigType" SG_ 2566811134 AuxHeaterInputAirTemp 1;
BA_ "SPN" SG_ 2566811134 AuxHeaterOutputCoolantTemp 1687;
BA_ "SigType" SG_ 2566811134 AuxHeaterOutputCoolantTemp 1;
BA_ "SPN" SG_ 2298375934 RearAxleRightWheelSpeed 1595;
BA_ "SigType" SG_ 2298375934 RearAxleRightWheelSpeed 1;
BA_ "SPN" SG_ 2298375934 RearAxleLeftWheelSpeed 1594;
BA_ "SigType" SG_ 2298375934 RearAxleLeftWheelSpeed 1;
BA_ "SPN" SG_ 2298375934 FrontAxleRightWheelSpeed 1593;
BA_ "SigType" SG_ 2298375934 FrontAxleRightWheelSpeed 1;
BA_ "SPN" SG_ 2298375934 FrontAxleLeftWheelSpeed 1592;
BA_ "SigType" SG_ 2298375934 FrontAxleLeftWheelSpeed 1;
BA_ "SPN" SG_ 2565867774 FireApparatusPumpEngagement 2599;
BA_ "SigType" SG_ 2565867774 FireApparatusPumpEngagement 4;
BA_ "SPN" SG_ 2565867774 HydPressGovernorPresetSwitch 6706;
BA_ "SigType" SG_ 2565867774 HydPressGovernorPresetSwitch 4;
BA_ "SPN" SG_ 2565867774 HydPressGovernorIncreaseSwitch 6703;
BA_ "SigType" SG_ 2565867774 HydPressGovernorIncreaseSwitch 4;
BA_ "SPN" SG_ 2565867774 HydPressGovernorDecreaseSwitch 6704;
BA_ "SigType" SG_ 2565867774 HydPressGovernorDecreaseSwitch 4;
BA_ "SPN" SG_ 2565867774 HydPressGovernorIdleSwitch 6705;
BA_ "SigType" SG_ 2565867774 HydPressGovernorIdleSwitch 4;
BA_ "SPN" SG_ 2565867774 HydDischargePressSetPoint 6708;
BA_ "SigType" SG_ 2565867774 HydDischargePressSetPoint 1;
BA_ "SPN" SG_ 2565867774 HydIntakePress 6707;
BA_ "SigType" SG_ 2565867774 HydIntakePress 1;
BA_ "SPN" SG_ 2565867774 FireApparatusOkayToPumpInterlock 6702;
BA_ "SigType" SG_ 2565867774 FireApparatusOkayToPumpInterlock 4;
BA_ "SPN" SG_ 2565867774 EngHydPressGovernorSwitch 1764;
BA_ "SigType" SG_ 2565867774 EngHydPressGovernorSwitch 4;
BA_ "SPN" SG_ 2565867774 EngHydPressGovernorModeIndicator 1763;
BA_ "SigType" SG_ 2565867774 EngHydPressGovernorModeIndicator 5;
BA_ "SPN" SG_ 2565867774 HydPress 1762;
BA_ "SigType" SG_ 2565867774 HydPress 1;
BA_ "SPN" SG_ 2566841854 EngTotalRevolutions 249;
BA_ "SigType" SG_ 2566841854 EngTotalRevolutions 1;
BA_ "SPN" SG_ 2566841854 EngTotalHoursOfOperation 247;
BA_ "SigType" SG_ 2566841854 EngTotalHoursOfOperation 1;
BA_ "SPN" SG_ 2365449982 HydBrakeFluidLevelSwitch 2931;
BA_ "SigType" SG_ 2365449982 HydBrakeFluidLevelSwitch 4;
BA_ "SPN" SG_ 2365449982 HydBrakeSystemAudibleWarningCmd 2930;
BA_ "SigType" SG_ 2365449982 HydBrakeSystemAudibleWarningCmd 5;
BA_ "SPN" SG_ 2365449982 HydBrakePressSupplyStateCircuit2 2583;
BA_ "SigType" SG_ 2365449982 HydBrakePressSupplyStateCircuit2 4;
BA_ "SPN" SG_ 2365449982 HydBrakePressSupplyStateCircuit1 2582;
BA_ "SigType" SG_ 2365449982 HydBrakePressSupplyStateCircuit1 4;
BA_ "SPN" SG_ 2365449982 HydBrkePressWarningStateCircuit2 2585;
BA_ "SigType" SG_ 2365449982 HydBrkePressWarningStateCircuit2 4;
BA_ "SPN" SG_ 2365449982 HydBrkePressWarningStateCircuit1 2584;
BA_ "SigType" SG_ 2365449982 HydBrkePressWarningStateCircuit1 4;
BA_ "SPN" SG_ 2365449982 HydBrakePressCircuit2 2581;
BA_ "SigType" SG_ 2365449982 HydBrakePressCircuit2 1;
BA_ "SPN" SG_ 2365449982 HydBrakePressCircuit1 2580;
BA_ "SigType" SG_ 2365449982 HydBrakePressCircuit1 1;
BA_ "SPN" SG_ 2633939198 TripDriveFuelEconomy 1012;
BA_ "SigType" SG_ 2633939198 TripDriveFuelEconomy 1;
BA_ "SPN" SG_ 2633939198 TripCruiseFuelUsed 1011;
BA_ "SigType" SG_ 2633939198 TripCruiseFuelUsed 1;
BA_ "SPN" SG_ 2633939198 TripVehicleIdleFuelUsed 1010;
BA_ "SigType" SG_ 2633939198 TripVehicleIdleFuelUsed 1;
BA_ "SPN" SG_ 2633939198 TripPTOGovernorNonmovingFuelUsed 1009;
BA_ "SigType" SG_ 2633939198 TripPTOGovernorNonmovingFuelUsed 1;
BA_ "SPN" SG_ 2633939198 TripPTOGovernorMovingFuelUsed 1008;
BA_ "SigType" SG_ 2633939198 TripPTOGovernorMovingFuelUsed 1;
BA_ "SPN" SG_ 2633939198 TripDriveFuelUsed 1007;
BA_ "SigType" SG_ 2633939198 TripDriveFuelUsed 1;
BA_ "SPN" SG_ 2633927678 EngFuelValve1OutletAbsPress 2980;
BA_ "SigType" SG_ 2633927678 EngFuelValve1OutletAbsPress 1;
BA_ "SPN" SG_ 2633927678 EngAirToFuelDiffPress 1392;
BA_ "SigType" SG_ 2633927678 EngAirToFuelDiffPress 1;
BA_ "SPN" SG_ 2633927678 EngFuelValveDiffPress 1391;
BA_ "SigType" SG_ 2633927678 EngFuelValveDiffPress 1;
BA_ "SPN" SG_ 2633927678 EngFuelValve1IntakeAbsPress 1390;
BA_ "SigType" SG_ 2633927678 EngFuelValve1IntakeAbsPress 1;
BA_ "SPN" SG_ 2633925118 EngRequestedFuelValve2Pos 1766;
BA_ "SigType" SG_ 2633925118 EngRequestedFuelValve2Pos 1;
BA_ "SPN" SG_ 2633925118 EngRequestedFuelValve1Pos 1765;
BA_ "SigType" SG_ 2633925118 EngRequestedFuelValve1Pos 1;
BA_ "SPN" SG_ 2633925118 EngFuelValve2Pos 1443;
BA_ "SigType" SG_ 2633925118 EngFuelValve2Pos 1;
BA_ "SPN" SG_ 2633925118 EngFuelValve1Pos 1442;
BA_ "SigType" SG_ 2633925118 EngFuelValve1Pos 1;
BA_ "SPN" SG_ 2633925118 EngFuelFlowRate2 1441;
BA_ "SigType" SG_ 2633925118 EngFuelFlowRate2 1;
BA_ "SPN" SG_ 2633925118 EngFuelFlowRate1 1440;
BA_ "SigType" SG_ 2633925118 EngFuelFlowRate1 1;
BA_ "SPN" SG_ 2633937662 EngFuelSpecificGravity 1389;
BA_ "SigType" SG_ 2633937662 EngFuelSpecificGravity 1;
BA_ "SPN" SG_ 2633937662 TripAverageFuelRate 1031;
BA_ "SigType" SG_ 2633937662 TripAverageFuelRate 1;
BA_ "SPN" SG_ 2633937662 TotalEngPTOGovernorFuelUsed 1030;
BA_ "SigType" SG_ 2633937662 TotalEngPTOGovernorFuelUsed 1;
BA_ "SPN" SG_ 2566804990 FuelEnergyContent 4245;
BA_ "SigType" SG_ 2566804990 FuelEnergyContent 1;
BA_ "SPN" SG_ 2566804990 ReferenceEngGasMassFlowRate 5684;
BA_ "SigType" SG_ 2566804990 ReferenceEngGasMassFlowRate 1;
BA_ "SPN" SG_ 2566804990 SpecificHeatRatio 1767;
BA_ "SigType" SG_ 2566804990 SpecificHeatRatio 1;
BA_ "SPN" SG_ 2633936894 TotalFuelUsed 1040;
BA_ "SigType" SG_ 2633936894 TotalFuelUsed 1;
BA_ "SPN" SG_ 2633936894 TripFuel 1039;
BA_ "SigType" SG_ 2633936894 TripFuel 1;
BA_ "SPN" SG_ 2566757630 SensorSupplyVoltage8 5126;
BA_ "SigType" SG_ 2566757630 SensorSupplyVoltage8 1;
BA_ "SPN" SG_ 2566757630 SensorSupplyVoltage7 5125;
BA_ "SigType" SG_ 2566757630 SensorSupplyVoltage7 1;
BA_ "SPN" SG_ 2566757630 SensorSupplyVoltage6 3514;
BA_ "SigType" SG_ 2566757630 SensorSupplyVoltage6 1;
BA_ "SPN" SG_ 2566757630 SensorSupplyVoltage5 3513;
BA_ "SigType" SG_ 2566757630 SensorSupplyVoltage5 1;
BA_ "SPN" SG_ 2566757886 SensorSupplyVoltage4 3512;
BA_ "SigType" SG_ 2566757886 SensorSupplyVoltage4 1;
BA_ "SPN" SG_ 2566757886 SensorSupplyVoltage3 3511;
BA_ "SigType" SG_ 2566757886 SensorSupplyVoltage3 1;
BA_ "SPN" SG_ 2566757886 SensorSupplyVoltage2 3510;
BA_ "SigType" SG_ 2566757886 SensorSupplyVoltage2 1;
BA_ "SPN" SG_ 2566757886 SensorSupplyVoltage1 3509;
BA_ "SigType" SG_ 2566757886 SensorSupplyVoltage1 1;
BA_ "SPN" SG_ 2566759678 AtLeastOnePTOEngaged 3948;
BA_ "SigType" SG_ 2566759678 AtLeastOnePTOEngaged 5;
BA_ "SPN" SG_ 2566759678 EnggmntSttsPTOEngAccessoryDrive2 3947;
BA_ "SigType" SG_ 2566759678 EnggmntSttsPTOEngAccessoryDrive2 5;
BA_ "SPN" SG_ 2566759678 EnggmntSttsPTOEngAccessoryDrive1 3944;
BA_ "SigType" SG_ 2566759678 EnggmntSttsPTOEngAccessoryDrive1 5;
BA_ "SPN" SG_ 2566759678 EngagementStatusPTOEngFlywheel 3941;
BA_ "SigType" SG_ 2566759678 EngagementStatusPTOEngFlywheel 5;
BA_ "SPN" SG_ 2566759678 EnggmntStatusTransInputShaftPTO1 3460;
BA_ "SigType" SG_ 2566759678 EnggmntStatusTransInputShaftPTO1 5;
BA_ "SPN" SG_ 2566759678 EnggmntStatusTransInputShaftPTO2 3461;
BA_ "SigType" SG_ 2566759678 EnggmntStatusTransInputShaftPTO2 5;
BA_ "SPN" SG_ 2566759678 EnggmntStatusTransOutputShaftPTO 3462;
BA_ "SigType" SG_ 2566759678 EnggmntStatusTransOutputShaftPTO 5;
BA_ "SPN" SG_ 2566759678 EnggmntSttsTrnsfrCsOtputShaftPTO 3463;
BA_ "SigType" SG_ 2566759678 EnggmntSttsTrnsfrCsOtputShaftPTO 5;
BA_ "SPN" SG_ 2566759678 EnggmntCnsntPTOEngAccssoryDrive2 3946;
BA_ "SigType" SG_ 2566759678 EnggmntCnsntPTOEngAccssoryDrive2 5;
BA_ "SPN" SG_ 2566759678 EnggmntCnsntPTOEngAccssoryDrive1 3943;
BA_ "SigType" SG_ 2566759678 EnggmntCnsntPTOEngAccssoryDrive1 5;
BA_ "SPN" SG_ 2566759678 EngagementConsentPTOEngFlywheel 3940;
BA_ "SigType" SG_ 2566759678 EngagementConsentPTOEngFlywheel 5;
BA_ "SPN" SG_ 2566759678 EnggmntCnsentTransInputShaftPTO1 3456;
BA_ "SigType" SG_ 2566759678 EnggmntCnsentTransInputShaftPTO1 5;
BA_ "SPN" SG_ 2566759678 EnggmntCnsentTransInputShaftPTO2 3457;
BA_ "SigType" SG_ 2566759678 EnggmntCnsentTransInputShaftPTO2 5;
BA_ "SPN" SG_ 2566759678 EnggmntCnsentTransOutputShaftPTO 3458;
BA_ "SigType" SG_ 2566759678 EnggmntCnsentTransOutputShaftPTO 5;
BA_ "SPN" SG_ 2566759678 EnggmntCnsntTrnsfrCsOtptShaftPTO 3459;
BA_ "SigType" SG_ 2566759678 EnggmntCnsntTrnsfrCsOtptShaftPTO 5;
BA_ "SPN" SG_ 2566759678 EnbleSwitchPTOEngAccessoryDrive2 3945;
BA_ "SigType" SG_ 2566759678 EnbleSwitchPTOEngAccessoryDrive2 5;
BA_ "SPN" SG_ 2566759678 EnbleSwitchPTOEngAccessoryDrive1 3942;
BA_ "SigType" SG_ 2566759678 EnbleSwitchPTOEngAccessoryDrive1 5;
BA_ "SPN" SG_ 2566759678 EnableSwitchPTOEngFlywheel 3939;
BA_ "SigType" SG_ 2566759678 EnableSwitchPTOEngFlywheel 5;
BA_ "SPN" SG_ 2566759678 EnableSwitchTransInputShaftPTO1 3452;
BA_ "SigType" SG_ 2566759678 EnableSwitchTransInputShaftPTO1 5;
BA_ "SPN" SG_ 2566759678 EnableSwitchTransInputShaftPTO2 3453;
BA_ "SigType" SG_ 2566759678 EnableSwitchTransInputShaftPTO2 5;
BA_ "SPN" SG_ 2566759678 EnableSwitchTransOutputShaftPTO 3454;
BA_ "SigType" SG_ 2566759678 EnableSwitchTransOutputShaftPTO 5;
BA_ "SPN" SG_ 2566759678 EnblSwtchTrnsfrCseOutputShaftPTO 3455;
BA_ "SigType" SG_ 2566759678 EnblSwtchTrnsfrCseOutputShaftPTO 5;
BA_ "SPN" SG_ 2432541438 EngFuelValve2OutletAbsPress 3469;
BA_ "SigType" SG_ 2432541438 EngFuelValve2OutletAbsPress 1;
BA_ "SPN" SG_ 2432541438 EngFuelTemp2 3468;
BA_ "SigType" SG_ 2432541438 EngFuelTemp2 1;
BA_ "SPN" SG_ 2432541438 EngGas2MassFlowRate 3467;
BA_ "SigType" SG_ 2432541438 EngGas2MassFlowRate 1;
BA_ "SPN" SG_ 2432541438 EngFuelValve2IntakeAbsPress 3466;
BA_ "SigType" SG_ 2432541438 EngFuelValve2IntakeAbsPress 1;
BA_ "SPN" SG_ 2566761214 EngChargeAirCoolerOutletPress 2631;
BA_ "SigType" SG_ 2566761214 EngChargeAirCoolerOutletPress 1;
BA_ "SPN" SG_ 2566761214 EngAftercoolerCoolantLevel 3676;
BA_ "SigType" SG_ 2566761214 EngAftercoolerCoolantLevel 1;
BA_ "SPN" SG_ 2566761214 EngIntercoolerCoolantLevel 3668;
BA_ "SigType" SG_ 2566761214 EngIntercoolerCoolantLevel 1;
BA_ "SPN" SG_ 2566761214 EngCentrifugalOilFilterSpeed 3343;
BA_ "SigType" SG_ 2566761214 EngCentrifugalOilFilterSpeed 1;
BA_ "SPN" SG_ 2566761214 EngCoolantPumpDiffPress 3342;
BA_ "SigType" SG_ 2566761214 EngCoolantPumpDiffPress 1;
BA_ "SPN" SG_ 2566761214 EngChargeAirCooler2IntakePress 3341;
BA_ "SigType" SG_ 2566761214 EngChargeAirCooler2IntakePress 1;
BA_ "SPN" SG_ 2566761214 EngChargeAirCooler1IntakePress 3340;
BA_ "SigType" SG_ 2566761214 EngChargeAirCooler1IntakePress 1;
BA_ "SPN" SG_ 2432541694 EngVriableGeometryTurboActuator1 641;
BA_ "SigType" SG_ 2432541694 EngVriableGeometryTurboActuator1 1;
BA_ "SPN" SG_ 2432541694 EngTrbCmprssrBypssActtr1TmpSttus 5368;
BA_ "SPN" SG_ 2432541694 EngTrbCmprssrBypssActtr1PrlmnryF 5367;
BA_ "SPN" SG_ 2432541694 EngTrbCmprssorBypassActuator2Cmd 5369;
BA_ "SigType" SG_ 2432541694 EngTrbCmprssorBypassActuator2Cmd 1;
BA_ "SPN" SG_ 2432541694 EngTrbCmprssorBypassActuator1Pos 3675;
BA_ "SigType" SG_ 2432541694 EngTrbCmprssorBypassActuator1Pos 1;
BA_ "SPN" SG_ 2432541694 EngTrbCmprssorBypassActuator1Cmd 3470;
BA_ "SigType" SG_ 2432541694 EngTrbCmprssorBypassActuator1Cmd 1;
BA_ "SPN" SG_ 2432541694 EngDsrdTrbCmprssrBypssActtor1Pos 5366;
BA_ "SigType" SG_ 2432541694 EngDsrdTrbCmprssrBypssActtor1Pos 1;
BA_ "SPN" SG_ 2566759934 EnableStatusOfDoor10 3441;
BA_ "SigType" SG_ 2566759934 EnableStatusOfDoor10 4;
BA_ "SPN" SG_ 2566759934 OpenStatusOfDoor10 3440;
BA_ "SigType" SG_ 2566759934 OpenStatusOfDoor10 4;
BA_ "SPN" SG_ 2566759934 LockStatusOfDoor10 3439;
BA_ "SigType" SG_ 2566759934 LockStatusOfDoor10 4;
BA_ "SPN" SG_ 2566759934 EnableStatusOfDoor9 3438;
BA_ "SigType" SG_ 2566759934 EnableStatusOfDoor9 4;
BA_ "SPN" SG_ 2566759934 OpenStatusOfDoor9 3437;
BA_ "SigType" SG_ 2566759934 OpenStatusOfDoor9 4;
BA_ "SPN" SG_ 2566759934 LockStatusOfDoor9 3436;
BA_ "SigType" SG_ 2566759934 LockStatusOfDoor9 4;
BA_ "SPN" SG_ 2566759934 EnableStatusOfDoor8 3435;
BA_ "SigType" SG_ 2566759934 EnableStatusOfDoor8 4;
BA_ "SPN" SG_ 2566759934 OpenStatusOfDoor8 3434;
BA_ "SigType" SG_ 2566759934 OpenStatusOfDoor8 4;
BA_ "SPN" SG_ 2566759934 LockStatusOfDoor8 3433;
BA_ "SigType" SG_ 2566759934 LockStatusOfDoor8 4;
BA_ "SPN" SG_ 2566759934 EnableStatusOfDoor7 3432;
BA_ "SigType" SG_ 2566759934 EnableStatusOfDoor7 4;
BA_ "SPN" SG_ 2566759934 OpenStatusOfDoor7 3431;
BA_ "SigType" SG_ 2566759934 OpenStatusOfDoor7 4;
BA_ "SPN" SG_ 2566759934 LockStatusOfDoor7 3430;
BA_ "SigType" SG_ 2566759934 LockStatusOfDoor7 4;
BA_ "SPN" SG_ 2566759934 EnableStatusOfDoor6 3429;
BA_ "SigType" SG_ 2566759934 EnableStatusOfDoor6 4;
BA_ "SPN" SG_ 2566759934 OpenStatusOfDoor6 3428;
BA_ "SigType" SG_ 2566759934 OpenStatusOfDoor6 4;
BA_ "SPN" SG_ 2566759934 LockStatusOfDoor6 3427;
BA_ "SigType" SG_ 2566759934 LockStatusOfDoor6 4;
BA_ "SPN" SG_ 2566759934 EnableStatusOfDoor5 3426;
BA_ "SigType" SG_ 2566759934 EnableStatusOfDoor5 4;
BA_ "SPN" SG_ 2566759934 OpenStatusOfDoor5 3425;
BA_ "SigType" SG_ 2566759934 OpenStatusOfDoor5 4;
BA_ "SPN" SG_ 2566759934 LockStatusOfDoor5 3424;
BA_ "SigType" SG_ 2566759934 LockStatusOfDoor5 4;
BA_ "SPN" SG_ 2566759934 EnableStatusOfDoor4 3423;
BA_ "SigType" SG_ 2566759934 EnableStatusOfDoor4 4;
BA_ "SPN" SG_ 2566759934 OpenStatusOfDoor4 3422;
BA_ "SigType" SG_ 2566759934 OpenStatusOfDoor4 4;
BA_ "SPN" SG_ 2566759934 LockStatusOfDoor4 3421;
BA_ "SigType" SG_ 2566759934 LockStatusOfDoor4 4;
BA_ "SPN" SG_ 2566759934 EnableStatusOfDoor3 3420;
BA_ "SigType" SG_ 2566759934 EnableStatusOfDoor3 4;
BA_ "SPN" SG_ 2566759934 OpenStatusOfDoor3 3419;
BA_ "SigType" SG_ 2566759934 OpenStatusOfDoor3 4;
BA_ "SPN" SG_ 2566759934 LockStatusOfDoor3 3418;
BA_ "SigType" SG_ 2566759934 LockStatusOfDoor3 4;
BA_ "SPN" SG_ 2566759934 EnableStatusOfDoor2 3417;
BA_ "SigType" SG_ 2566759934 EnableStatusOfDoor2 4;
BA_ "SPN" SG_ 2566759934 OpenStatusOfDoor2 3416;
BA_ "SigType" SG_ 2566759934 OpenStatusOfDoor2 4;
BA_ "SPN" SG_ 2566759934 LockStatusOfDoor2 3415;
BA_ "SigType" SG_ 2566759934 LockStatusOfDoor2 4;
BA_ "SPN" SG_ 2566759934 EnableStatusOfDoor1 3414;
BA_ "SigType" SG_ 2566759934 EnableStatusOfDoor1 4;
BA_ "SPN" SG_ 2566759934 OpenStatusOfDoor1 3413;
BA_ "SigType" SG_ 2566759934 OpenStatusOfDoor1 4;
BA_ "SPN" SG_ 2566759934 LockStatusOfDoor1 3412;
BA_ "SigType" SG_ 2566759934 LockStatusOfDoor1 4;
VAL_ 2566718974 VhclAcclerationRateLimitLampData 3 "Not available" 2 "Error" 1 "Lamp activated" 0 "Lamp deactivated" ;
VAL_ 2566718974 EngSpeedVeryHighLampData 3 "Not available" 2 "Error" 1 "Lamp Activated" 0 "Lamp Deactivated" ;
VAL_ 2566718974 EngSpeedHighLampData 0 "Lamp Deactivated" 3 "Not available" 2 "Error" 1 "Lamp Activated" ;
VAL_ 2566718974 EngCtrlMdule3ReadyForUseLampData 3 "Not Available" 2 "Error" 1 "Lamp activated" 0 "Lamp deactivated" ;
VAL_ 2566718974 EngCtrlMdule2ReadyForUseLampData 3 "Not Available" 2 "Error" 1 "Lamp activated" 0 "Lamp deactivated" ;
VAL_ 2566718974 EngCtrlMdule1ReadyForUseLampData 3 "Not Available" 2 "Error" 1 "Lamp activated" 0 "Lamp deactivated" ;
VAL_ 2566718974 EngWaitToStartLampData 3 "Not available" 2 "Error" 1 "Lamp actived" 0 "Lamp deactived" ;
VAL_ 2566718974 EngFuelFilterRestrictedLampData 3 "Not available" 2 "Error" 1 "Lamp activated" 0 "Lamp deactivated" ;
VAL_ 2566718974 EngAirFilterRestrictionLampData 3 "Not available" 2 "Error" 1 "Lamp activated" 0 "Lamp deactivated" ;
VAL_ 2566718974 EngIdleManagementActiveLampData 3 "Not available" 2 "Error" 1 "Lamp activated" 0 "Lamp deactivated" ;
VAL_ 2566718974 EngCoolantLevelLowLampData 3 "Not available" 2 "Error" 1 "Lamp activated" 0 "Lamp deactivated" ;
VAL_ 2566718974 EngCoolantTempHighLampData 3 "Not available" 2 "Error" 1 "Lamp activated" 0 "Lamp deactivated" ;
VAL_ 2566718974 EngOilPressLowLampData 3 "Not available" 2 "Error" 1 "Lamp activated" 0 "Lamp deactivated" ;
VAL_ 2566718974 CmprssnBrkEnblSwtchIndctrLmpData 3 "Not available" 2 "Error" 1 "Lamp activated" 0 "Lamp deactivated" ;
VAL_ 2566718974 EngBrakeActiveLampData 3 "Not available" 2 "Error" 1 "Lamp activated" 0 "Lamp deactivated" ;
VAL_ 2566718974 OBDMalfunctionIndicatorLampData 3 "Not available" 2 "Error" 1 "Lamp activated" 0 "Lamp deactivated" ;
VAL_ 2566718974 EngRedStopLampData 3 "Not available" 2 "Error" 1 "Lamp activated" 0 "Lamp deactivated" ;
VAL_ 2566718974 EngAmberWarningLampData 3 "Not available" 2 "Error" 1 "Lamp activated" 0 "Lamp deactivated" ;
VAL_ 2566718974 EngProtectLampData 3 "Not available" 2 "Error" 1 "Lamp activated" 0 "Lamp deactivated" ;
VAL_ 2566719230 HillHolderLampCmd 3 "Not available" 2 "Lamp Flash" 1 "Lamp On" 0 "Lamp Off" ;
VAL_ 2566719230 VehicleBatteryChargingLampCmd 3 "Not available" 2 "Reserved" 1 "Lamp On" 0 "Lamp Off" ;
VAL_ 2566719230 VehicleHVACRecirculationLampCmd 3 "Not available" 2 "Reserved" 1 "Lamp On" 0 "Lamp Off" ;
VAL_ 2566719230 VehicleAirPressLowLampCmd 3 "Not available" 2 "Reserved" 1 "Lamp On" 0 "Lamp Off" ;
VAL_ 2566719230 VehicleFuelLevelLowLampCmd 3 "Not available" 2 "Reserved" 1 "Lamp On" 0 "Lamp Off" ;
VAL_ 2566719230 VehicleBatteryVoltageLowLampCmd 3 "Not available" 2 "Reserved" 1 "Lamp On" 0 "Lamp Off" ;
VAL_ 2560818942 FailureModeIdentifier1 31 "Not available" 19 "Received network data in error" 18 "Below normal (moderately severe)" 17 "Below normal (least severe)" 16 "Above normal (moderately severe)" 15 "Above normal (least severe)" 14 "Special intstructions" 13 "Out of calibration" 12 "Bad intelligent device" 11 "Root cause not known" 10 "Abnormal rate of change" 9 "Abnormal update rate" 8 "Abnormal frequency" 7 "Mechanical system not responding" 6 "Current above normal" 5 "Current below normal" 4 "Voltage below normal" 3 "Voltage above normal" 2 "Data erratic" 1 "Below normal (most severe)" 0 "Above normal (most severe)" ;
VAL_ 2561212158 TextDisplayInstructions 15 "- Not applicable" 6 "Blink substring" 5 "Highlight substring" 4 "Overwrite substring" 3 "Overwrite display" 2 "Append at end of display" 1 "Hold display" 0 "Clear display" ;
VAL_ 2566746366 RetractStatusOfRamp5 3 "not available" 2 "error" 1 "ramp extended" 0 "ramp retracted" ;
VAL_ 2566746366 RetractStatusOfRamp4 3 "not available" 2 "error" 1 "ramp extended" 0 "ramp retracted" ;
VAL_ 2566746366 MovementStatusOfRamp5 3 "not available" 2 "error" 1 "ramp being moved" 0 "ramp not being moved" ;
VAL_ 2566746366 MovementStatusOfRamp4 3 "not available" 2 "error" 1 "ramp being moved" 0 "ramp not being moved" ;
VAL_ 2566746366 EnableStatusOfRamp5 3 "not available" 2 "error " 1 "ramp enabled " 0 "ramp disabled" ;
VAL_ 2566746366 EnableStatusOfRamp4 3 "not available" 2 "error " 1 "ramp enabled " 0 "ramp disabled" ;
VAL_ 2566746366 MovementStatusOfRamp3 3 "not available" 2 "error" 1 "ramp being moved" 0 "ramp not being moved" ;
VAL_ 2566746366 EnableStatusOfRamp3 3 "not available" 2 "error " 1 "ramp enabled " 0 "ramp disabled" ;
VAL_ 2566746366 RetractStatusOfRamp3 3 "not available" 2 "error" 1 "ramp extended" 0 "ramp retracted" ;
VAL_ 2566746366 MovementStatusOfRamp2 3 "not available" 2 "error" 1 "ramp being moved" 0 "ramp not being moved" ;
VAL_ 2566746366 EnableStatusOfRamp2 3 "not available" 2 "error " 1 "ramp enabled " 0 "ramp disabled" ;
VAL_ 2566746366 RetractStatusOfRamp2 3 "not available" 2 "error" 1 "ramp extended" 0 "ramp retracted" ;
VAL_ 2566746366 MovementStatusOfRamp1 3 "not available" 2 "error" 1 "ramp being moved" 0 "ramp not being moved" ;
VAL_ 2566746366 EnableStatusOfRamp1 3 "not available" 2 "error " 1 "ramp enabled " 0 "ramp disabled" ;
VAL_ 2566746366 RetractStatusOfRamp1 3 "not available" 2 "error" 1 "ramp extended" 0 "ramp retracted" ;
VAL_ 2561277694 LaneKeepingAssistEnableCmd 3 "Don't care" 2 "Reserved" 1 "Enable lane keeping assist" 0 "Disable lane keeping assist" ;
VAL_ 2561277694 LaneCenteringEnableCmd 3 "Don't care" 2 "Reserved" 1 "Enable lane centering" 0 "Disable lane centering" ;
VAL_ 2561277694 LaneDepartureWarningEnableCmd 3 "Don't care" 2 "Reserved" 1 "Enable Lane Departure Warning" 0 "Disable Lane Departure Warning" ;
VAL_ 2633861886 J2012DTCStatus 1 "DTC is active" 0 "DTC is previously active" ;
VAL_ 2565873150 SteerAngleSensorCalibrated 3 "Not available" 2 "Reserved" 1 "SAS calibrated" 0 "SAS not calibrated" ;
VAL_ 2565873150 SteerAngleSensorActiveMode 3 "Not available" 2 "Reserved" 1 "Normal mode active" 0 "Programming mode active" ;
VAL_ 2565873150 SteerWheelAngleRangeCounterType 3 "signal not available" 2 "not defined" 1 "absolute number of counts" 0 "relative number of counts" ;
VAL_ 2566751230 TransferCaseStatus 7 "not available" 6 "error" 5 "Transfer Case Shift in Progress or gear not confirmed" 4 "4 wheel low" 3 "2 wheel low" 2 "neutral" 1 "4 wheel high" 0 "2 wheel high" ;
VAL_ 2566755838 TransOilLevel2MeasurementStatus 15 "Not available" 14 "Error" 13 "Conditions not valid, Other" 12 "Not defined" 11 "Not defined" 10 "Not defined" 9 "Conditions not valid, No request for reading" 8 "Conditions not valid, Engine speed too high" 7 "Conditions not valid, Engine speed too low" 6 "Conditions not valid, Vehicle not level" 5 "Conditions not valid, Vehicle moving" 4 "Conditions not valid, Transmission fluid temperature too high" 3 "Conditions not valid, Transmission fluid temperature too low" 2 "Conditions not valid, Transmission in gear" 1 "Conditions not valid, Settling timer still counting down" 0 "Conditions valid for transmission oil level measurement" ;
VAL_ 2566755838 TransOilLevel2CountdownTimer 15 "Not Available" 14 "Error" 13 "Thirteen minutes" 12 "Twelve minutes" 11 "Eleven minutes" 10 "Ten minutes" 9 "Nine minutes" 8 "Eight minutes" 7 "Seven minutes" 6 "Six minutes" 5 "Five minutes" 4 "Four minutes" 3 "Three minutes" 2 "Two minutes" 1 "One minute" 0 "less than 1 minute" ;
VAL_ 2566755838 TransOverheatIndicator 3 "Not available" 2 "Transmission Overheat Indicator is flashing" 1 "Transmission Overheat Indicator is on continuously" 0 "Transmission Overheat Indicator is off" ;
VAL_ 2566755838 TransOilLevelSwitch 3 "Not available" 2 "Error" 1 "Full or not empty" 0 "Empty" ;
VAL_ 2566755838 TransOilFilterRestrictionSwitch 3 "Not available" 2 "Error" 1 "Restriction exists on oil filter" 0 "No restriction" ;
VAL_ 2566799614 ImplementRearWorkLight 3 "Not Available" 2 "Fault Detected" 1 "Activated" 0 "De-activated" ;
VAL_ 2566799614 ImplLeftFacingWorkLight 3 "Not Available" 2 "Fault Detected" 1 "Activated" 0 "De-activated" ;
VAL_ 2566799614 ImplRightForwardWorkLight 3 "Not Available" 2 "Fault Detected" 1 "Activated" 0 "De-activated" ;
VAL_ 2566799614 ImplLeftForwardWorkLight 3 "Not Available" 2 "Fault Detected" 1 "Activated" 0 "De-activated" ;
VAL_ 2566799614 ImplRightFacingWorkLight 3 "Not Available" 2 "Fault Detected" 1 "Activated" 0 "De-activated" ;
VAL_ 2566799614 ImplementOEMOption1Light 3 "Not Available" 2 "Fault Detected" 1 "Activated" 0 "De-activated" ;
VAL_ 2566799614 ImplementOEMOption2Light 3 "Not Available" 2 "Fault Detected" 1 "Activated" 0 "De-activated" ;
VAL_ 2566799614 TrctorFrontHighMdWkLights 3 "Not Available" 2 "Fault Detected" 1 "Activated" 0 "De-activated" ;
VAL_ 2566799614 TractorFrontLowMdWkLights 3 "Not Available" 2 "Fault Detected" 1 "Activated" 0 "De-activated" ;
VAL_ 2566799614 TractorSideHighMdWkLights 3 "Not Available" 2 "Fault Detected" 1 "Activated" 0 "De-activated" ;
VAL_ 2566799614 TractorSideLowMdWkLights 3 "Not Available" 2 "Fault Detected" 1 "Activated" 0 "De-activated" ;
VAL_ 2566799614 TractorRearHighMdWkLights 3 "Not Available" 2 "Fault Detected" 1 "Activated" 0 "De-activated" ;
VAL_ 2566799614 TractorRearLowMdWkLights 3 "Not Available" 2 "Fault Detected" 1 "Activated" 0 "De-activated" ;
VAL_ 2566799614 TrctorUndersideMdWkLights 3 "Not Available" 2 "Fault Detected" 1 "Activated" 0 "De-activated" ;
VAL_ 2566799614 RearFogLights 3 "Not Available" 2 "Fault Detected" 1 "Activated" 0 "De-activated" ;
VAL_ 2566799614 TractorMarkerLight 3 "Not Available" 2 "Fault Detected" 1 "Activated" 0 "De-activated" ;
VAL_ 2566799614 ImplementMarkerLight 3 "Not Available" 2 "Fault Detected" 1 "Activated" 0 "De-activated" ;
VAL_ 2566799614 TractorClearanceLight 3 "Not Available" 2 "Fault Detected" 1 "Activated" 0 "De-activated" ;
VAL_ 2566799614 ImplementClearanceLight 3 "Not Available" 2 "Fault Detected" 1 "Activated" 0 "De-activated" ;
VAL_ 2566799614 LeftStopLight 3 "Not Available" 2 "Fault Detected" 1 "Activated" 0 "De-activated" ;
VAL_ 2566799614 RightStopLight 3 "Not Available" 2 "Fault Detected" 1 "Activated" 0 "De-activated" ;
VAL_ 2566799614 CenterStopLight 3 "Not Available" 2 "Fault Detected" 1 "Activated" 0 "De-activated" ;
VAL_ 2566799614 BackUpLightAndAlarmHorn 3 "Not Available" 2 "Fault Detected" 1 "Activated" 0 "De-activated" ;
VAL_ 2566799614 LeftTurnSignalLights 3 "Not Available" 2 "Fault Detected" 1 "Activated" 0 "De-activated" ;
VAL_ 2566799614 RightTurnSignalLights 3 "Not Available" 2 "Fault Detected" 1 "Activated" 0 "De-activated" ;
VAL_ 2566799614 RotatingBeaconLight 3 "Not Available" 2 "Fault Detected" 1 "Activated" 0 "De-activated" ;
VAL_ 2566799614 TractorFrontFogLights 3 "Not Available" 2 "Fault Detected" 1 "Activated" 0 "De-activated" ;
VAL_ 2566799614 HighBeamHeadLight 3 "Not Available" 2 "Fault Detected" 1 "Activated" 0 "De-activated" ;
VAL_ 2566799614 LowBeamHeadLight 3 "Not Available" 2 "Fault Detected" 1 "Activated" 0 "De-activated" ;
VAL_ 2566799614 AltBeamHeadLight 3 "Not Available" 2 "Fault Detected" 1 "Activated" 0 "De-activated" ;
VAL_ 2566799614 RunningLight 3 "Not Available" 2 "Fault Detected" 1 "Activated" 0 "De-activated" ;
VAL_ 2365473278 ImplementRearWorkLightCmd 3 "Don't Care" 2 "Reserved" 1 "Activate" 0 "De-activate" ;
VAL_ 2365473278 ImplLeftFacingWorkLightCmd 3 "Don't Care" 2 "Reserved" 1 "Activate" 0 "De-activate" ;
VAL_ 2365473278 ImplRightFwdWorkLightCmd 3 "Don't Care" 2 "Reserved" 1 "Activate" 0 "De-activate" ;
VAL_ 2365473278 LightingDataRqCmd 3 "Don't Care" 2 "Reserved" 1 "Activate" 0 "De-activate" ;
VAL_ 2365473278 ImplLeftForwardWorkLightCmd 3 "Don't Care" 2 "Reserved" 1 "Activate" 0 "De-activate" ;
VAL_ 2365473278 ImplRightFacingWorkLightCmd 3 "Don't Care" 2 "Reserved" 1 "Activate" 0 "De-activate" ;
VAL_ 2365473278 ImplOEMOption1LightCmd 3 "Don't Care" 2 "Reserved" 1 "Activate" 0 "De-activate" ;
VAL_ 2365473278 ImplOEMOption2LightCmd 3 "Don't Care" 2 "Reserved" 1 "Activate" 0 "De-activate" ;
VAL_ 2365473278 TrctrFrntHghMdWkLightsCmd 3 "Don't Care" 2 "Reserved" 1 "Activate" 0 "De-activate" ;
VAL_ 2365473278 TrctrFrntLowMdWkLightsCmd 3 "Don't Care" 2 "Reserved" 1 "Activate" 0 "De-activate" ;
VAL_ 2365473278 TrctrSdeHighMdWkLightsCmd 3 "Don't Care" 2 "Reserved" 1 "Activate" 0 "De-activate" ;
VAL_ 2365473278 TrctrSideLowMdWkLightsCmd 3 "Don't Care" 2 "Reserved" 1 "Activate" 0 "De-activate" ;
VAL_ 2365473278 TrctrRarHighMdWkLightsCmd 3 "Don't Care" 2 "Reserved" 1 "Activate" 0 "De-activate" ;
VAL_ 2365473278 TrctrRearLowMdWkLightsCmd 3 "Don't Care" 2 "Reserved" 1 "Activate" 0 "De-activate" ;
VAL_ 2365473278 TrctrUndrsdeMdWkLightsCmd 3 "Don't Care" 2 "Reserved" 1 "Activate" 0 "De-activate" ;
VAL_ 2365473278 RearFogLightsCmd 3 "Don't Care" 2 "Reserved" 1 "Activate" 0 "De-activate" ;
VAL_ 2365473278 TractorMarkerLightCmd 3 "Don't Care" 2 "Reserved" 1 "Activate" 0 "De-activate" ;
VAL_ 2365473278 ImplementMarkerLightCmd 2 "Reserved" 3 "Don't Care" 1 "Activate" 0 "De-activate" ;
VAL_ 2365473278 TractorClearanceLightCmd 3 "Don't Care" 2 "Reserved" 1 "Activate" 0 "De-activate" ;
VAL_ 2365473278 ImplementClearanceLightCmd 3 "Don't Care" 2 "Reserved" 1 "Activate" 0 "De-activate" ;
VAL_ 2365473278 LeftStopLightCmd 3 "Don't Care" 2 "Reserved" 1 "Activate" 0 "De-activate" ;
VAL_ 2365473278 RightStopLightCmd 3 "Don't Care" 2 "Reserved" 1 "Activate" 0 "De-activate" ;
VAL_ 2365473278 CenterStopLightCmd 3 "Don't Care" 2 "Reserved" 1 "Activate" 0 "De-activate" ;
VAL_ 2365473278 BackUpLightAndAlarmHornCmd 3 "Don't Care" 2 "Reserved" 1 "Activate" 0 "De-activate" ;
VAL_ 2365473278 LeftTurnSignalLightsCmd 3 "Don't Care" 2 "Reserved" 1 "Activate" 0 "De-activate" ;
VAL_ 2365473278 RightTurnSignalLightsCmd 3 "Don't Care" 2 "Reserved" 1 "Activate" 0 "De-activate" ;
VAL_ 2365473278 RotatingBeaconLightCmd 3 "Don't Care" 2 "Reserved" 1 "Activate" 0 "De-activate" ;
VAL_ 2365473278 TractorFrontFogLightsCmd 3 "Don't Care" 2 "Reserved" 1 "Activate" 0 "De-activate" ;
VAL_ 2365473278 HighBeamHeadLightCmd 3 "Don't Care" 2 "Reserved" 1 "Activate" 0 "De-activate" ;
VAL_ 2365473278 LowBeamHeadLightCmd 3 "Don't Care" 2 "Reserved" 1 "Activate" 0 "De-activate" ;
VAL_ 2365473278 AltBeamHeadLightCmd 3 "Don't Care" 2 "Reserved" 1 "Activate" 0 "De-activate" ;
VAL_ 2365473278 RunningLightCmd 3 "Don't Care" 2 "Reserved" 1 "Activate" 0 "De-activate" ;
VAL_ 2365485822 LandLevelingSystemEnableStatus 3 "Not available / Not installed" 2 "Error" 0 "Disabled" ;
VAL_ 2365485822 BladeCtrlModeRight 15 "Not Available" 14 "Error" 2 "Inactive Auto" 1 "Auto " 0 "Manual" ;
VAL_ 2365485822 BladeCtrlModeLeft 15 "Not Available" 14 "Error" 2 "Inactive Auto" 1 "Auto " 0 "Manual" ;
VAL_ 2365485822 BladeCtrlMode 2 "Inactive automatic mode" 1 "Automatic mode" 0 "Manual mode" ;
VAL_ 2566768894 EngOprtrPrmryIntrmdtSpdSlctState 15 "- not available" 14 "- SAE reserved" 1 "thru 1101" 0 "- Control state is ISC functionality is not requested" ;
VAL_ 2566769406 EngOprtrPrmryIntrmdteSpeedSelect 15 "- not available" 14 "- error condition" 1 "thru 1101" 0 "- indicates that the ISC functionality is not requested" ;
VAL_ 2566811134 ADRCompliantHeaterInstallation 3 "Not Available" 2 "Error" 1 "Heater installation is ADR compliant" 0 "Heater installation is not ADR compliant" ;
VAL_ 2566811134 CabHeatingZone 3 "Not available" 2 "Reserved" 1 "Cab heating zone on" 0 "Cab heating zone off" ;
VAL_ 2566811134 EngHeatingZone 3 "Not available" 2 "Reserved" 1 "Engine heating zone on" 0 "Engine heating zone off" ;
VAL_ 2566811134 CabVentilation 3 "Not available" 2 "Reserved" 1 "Cab is ventilated" 0 "Cab not ventilated" ;
VAL_ 2566811134 AuxHeaterWaterPumpStatus 3 "Not available" 2 "Reserved" 1 "Water Pump is  running" 0 "Water Pump is not running" ;
VAL_ 2566811134 AuxHeaterMode 15 "Not available" 14 "Error" 8 "Heater Locked" 7 "Diagnose Active" 6 "Heater Stopping" 5 "Heater Starting" 4 "Heater pump up-keep  " 3 "Normal mode" 2 "Economy mode" 1 "Off due to ADR per European Regulations for Transport of hazardous materials" 0 "Heater not active" ;
VAL_ 2565867774 FireApparatusPumpEngagement 3 "Not available or not installed" 2 "Error" 1 "Pump engaged" 0 "Pump not engaged" ;
VAL_ 2565867774 HydPressGovernorPresetSwitch 3 "Not available" 2 "Error" 1 "Preset Switch Active" 0 "Preset Switch Inactive" ;
VAL_ 2565867774 HydPressGovernorIncreaseSwitch 3 "Not available" 2 "Error" 1 "Increase Switch Active" 0 "Increase Switch Inactive" ;
VAL_ 2565867774 HydPressGovernorDecreaseSwitch 3 "Not available" 2 "Error" 1 "Decrease Switch Active" 0 "Decrease Switch Inactive" ;
VAL_ 2565867774 HydPressGovernorIdleSwitch 3 "Not available" 2 "Error" 1 "Idle Switch Active" 0 "Idle Switch Inactive" ;
VAL_ 2565867774 FireApparatusOkayToPumpInterlock 3 "Not Available" 2 "Error" 1 "Okay to Pump Interlock Active" 0 "Okay to Pump Interlock Inactive" ;
VAL_ 2565867774 EngHydPressGovernorSwitch 3 "Not Available" 2 "Error Indicator" 1 "Pressure Mode Active" 0 "Pressure Mode Inactive" ;
VAL_ 2565867774 EngHydPressGovernorModeIndicator 3 "Not Available" 2 "Error Indicator" 1 "Enabled" 0 "Disabled" ;
VAL_ 2365449982 HydBrakeFluidLevelSwitch 3 "Not available" 2 "Error indicator" 1 "Fluid level is sufficient" 0 "Fluid level is not sufficient" ;
VAL_ 2365449982 HydBrakeSystemAudibleWarningCmd 3 "Don't care" 2 "Reserved" 1 "Audible warning on" 0 "Audible warning off" ;
VAL_ 2365449982 HydBrakePressSupplyStateCircuit2 3 "Not available" 2 "Error indicator" 1 "Supply is reliable" 0 "Supply is not reliable" ;
VAL_ 2365449982 HydBrakePressSupplyStateCircuit1 3 "Not available" 2 "Error indicator" 1 "Supply is reliable" 0 "Supply is not reliable" ;
VAL_ 2365449982 HydBrkePressWarningStateCircuit2 3 "Not available" 2 "Error indicator" 1 "Pressure level below warning level" 0 "Pressure level sufficient" ;
VAL_ 2365449982 HydBrkePressWarningStateCircuit1 3 "Not available" 2 "Error indicator" 1 "Pressure level below warning level" 0 "Pressure level sufficient" ;
VAL_ 2566759678 AtLeastOnePTOEngaged 3 "Not available" 2 "Error" 1 "At least one PTO drive is engaged" 0 "No PTO drive is engaged" ;
VAL_ 2566759678 EnggmntSttsPTOEngAccessoryDrive2 3 "Not available" 2 "Error" 1 "Drive engaged" 0 "Drive not engaged" ;
VAL_ 2566759678 EnggmntSttsPTOEngAccessoryDrive1 3 "Not available" 2 "Error" 1 "Drive engaged" 0 "Drive not engaged" ;
VAL_ 2566759678 EngagementStatusPTOEngFlywheel 3 "Not available" 2 "Error" 1 "Drive engaged" 0 "Drive not engaged" ;
VAL_ 2566759678 EnggmntStatusTransInputShaftPTO1 3 "Not available" 2 "Error" 1 "Drive is engaged" 0 "Drive not engaged" ;
VAL_ 2566759678 EnggmntStatusTransInputShaftPTO2 3 "Not available" 2 "Error" 1 "Drive is engaged" 0 "Drive not engaged" ;
VAL_ 2566759678 EnggmntStatusTransOutputShaftPTO 3 "Not available" 2 "Error" 1 "Drive is engaged" 0 "Drive not engaged" ;
VAL_ 2566759678 EnggmntSttsTrnsfrCsOtputShaftPTO 3 "Not available" 2 "Error" 1 "Drive is engaged" 0 "Drive not engaged" ;
VAL_ 2566759678 EnggmntCnsntPTOEngAccssoryDrive2 3 "Not available" 2 "Error" 1 "Consent given" 0 "Consent not given" ;
VAL_ 2566759678 EnggmntCnsntPTOEngAccssoryDrive1 3 "Not available" 2 "Error" 1 "Consent given" 0 "Consent not given" ;
VAL_ 2566759678 EngagementConsentPTOEngFlywheel 3 "Not available" 2 "Error" 1 "Consent given" 0 "Consent not given" ;
VAL_ 2566759678 EnggmntCnsentTransInputShaftPTO1 3 "Not available" 2 "Error" 1 "Consent given" 0 "Consent not given" ;
VAL_ 2566759678 EnggmntCnsentTransInputShaftPTO2 3 "Not available" 2 "Error" 1 "Consent given" 0 "Consent not given" ;
VAL_ 2566759678 EnggmntCnsentTransOutputShaftPTO 3 "Not available" 2 "Error" 1 "Consent given" 0 "Consent not given" ;
VAL_ 2566759678 EnggmntCnsntTrnsfrCsOtptShaftPTO 3 "Not available" 2 "Error" 1 "Consent given" 0 "Consent not given" ;
VAL_ 2566759678 EnbleSwitchPTOEngAccessoryDrive2 3 "Not available" 2 "Error" 1 "Enable switch on" 0 "Enable switch off" ;
VAL_ 2566759678 EnbleSwitchPTOEngAccessoryDrive1 3 "Not available" 2 "Error" 1 "Enable switch on" 0 "Enable switch off" ;
VAL_ 2566759678 EnableSwitchPTOEngFlywheel 3 "Not available" 2 "Error" 1 "Enable switch on" 0 "Enable switch off" ;
VAL_ 2566759678 EnableSwitchTransInputShaftPTO1 3 "Not available" 2 "Error" 1 "Enable switch on" 0 "Enable switch off" ;
VAL_ 2566759678 EnableSwitchTransInputShaftPTO2 3 "Not available" 2 "Error" 1 "Enable switch on" 0 "Enable switch off" ;
VAL_ 2566759678 EnableSwitchTransOutputShaftPTO 3 "Not available" 2 "Error" 1 "Enable switch on" 0 "Enable switch off" ;
VAL_ 2566759678 EnblSwtchTrnsfrCseOutputShaftPTO 3 "Not available" 2 "Error" 1 "Enable switch on" 0 "Enable switch off" ;
VAL_ 2432541694 EngTrbCmprssrBypssActtr1TmpSttus 7 "Not available" 6 "Error" 5 "Not Defined" 4 "Low Most severe" 3 "Low Least severe" 2 "In Range" 1 "High Least severe" 0 "High Most severe" ;
VAL_ 2566759934 EnableStatusOfDoor10 3 "not available" 2 "error" 1 "door enabled" 0 "door disabled" ;
VAL_ 2566759934 OpenStatusOfDoor10 3 "not available" 2 "error" 1 "door opened" 0 "door closed" ;
VAL_ 2566759934 LockStatusOfDoor10 3 "not available" 2 "error" 1 "locked" 0 "unlocked " ;
VAL_ 2566759934 EnableStatusOfDoor9 3 "not available" 2 "error" 1 "door enabled" 0 "door disabled" ;
VAL_ 2566759934 OpenStatusOfDoor9 3 "not available" 2 "error" 1 "door opened" 0 "door closed" ;
VAL_ 2566759934 LockStatusOfDoor9 3 "not available" 2 "error" 1 "locked" 0 "unlocked " ;
VAL_ 2566759934 EnableStatusOfDoor8 3 "not available" 2 "error" 1 "door enabled" 0 "door disabled" ;
VAL_ 2566759934 OpenStatusOfDoor8 3 "not available" 2 "error" 1 "door opened" 0 "door closed" ;
VAL_ 2566759934 LockStatusOfDoor8 3 "not available" 2 "error" 1 "locked" 0 "unlocked " ;
VAL_ 2566759934 EnableStatusOfDoor7 3 "not available" 2 "error" 1 "door enabled" 0 "door disabled" ;
VAL_ 2566759934 OpenStatusOfDoor7 3 "not available" 2 "error" 1 "door opened" 0 "door closed" ;
VAL_ 2566759934 LockStatusOfDoor7 3 "not available" 2 "error" 1 "locked" 0 "unlocked " ;
VAL_ 2566759934 EnableStatusOfDoor6 3 "not available" 2 "error" 1 "door enabled" 0 "door disabled" ;
VAL_ 2566759934 OpenStatusOfDoor6 3 "not available" 2 "error" 1 "door opened" 0 "door closed" ;
VAL_ 2566759934 LockStatusOfDoor6 3 "not available" 2 "error" 1 "locked" 0 "unlocked " ;
VAL_ 2566759934 EnableStatusOfDoor5 3 "not available" 2 "error" 1 "door enabled" 0 "door disabled" ;
VAL_ 2566759934 OpenStatusOfDoor5 3 "not available" 2 "error" 1 "door opened" 0 "door closed" ;
VAL_ 2566759934 LockStatusOfDoor5 3 "not available" 2 "error" 1 "locked" 0 "unlocked " ;
VAL_ 2566759934 EnableStatusOfDoor4 3 "not available" 2 "error" 1 "door enabled" 0 "door disabled" ;
VAL_ 2566759934 OpenStatusOfDoor4 3 "not available" 2 "error" 1 "door opened" 0 "door closed" ;
VAL_ 2566759934 LockStatusOfDoor4 3 "not available" 2 "error" 1 "locked" 0 "unlocked " ;
VAL_ 2566759934 EnableStatusOfDoor3 3 "not available" 2 "error" 1 "door enabled" 0 "door disabled" ;
VAL_ 2566759934 OpenStatusOfDoor3 3 "not available" 2 "error" 1 "door opened" 0 "door closed" ;
VAL_ 2566759934 LockStatusOfDoor3 3 "not available" 2 "error" 1 "locked" 0 "unlocked " ;
VAL_ 2566759934 EnableStatusOfDoor2 0 "door disabled" 3 "not available" 2 "error" 1 "door enabled" ;
VAL_ 2566759934 OpenStatusOfDoor2 3 "not available" 2 "error" 1 "door opened" 0 "door closed" ;
VAL_ 2566759934 LockStatusOfDoor2 3 "not available" 2 "error" 1 "locked" 0 "unlocked " ;
VAL_ 2566759934 EnableStatusOfDoor1 3 "not available" 2 "error" 1 "door enabled" 0 "door disabled" ;
VAL_ 2566759934 OpenStatusOfDoor1 3 "not available" 2 "error" 1 "door opened" 0 "door closed" ;
VAL_ 2566759934 LockStatusOfDoor1 3 "not available" 2 "error" 1 "locked" 0 "unlocked " ;
